VERSION ""

NS_ :

BS_:

BU_: FRM_FM_4X

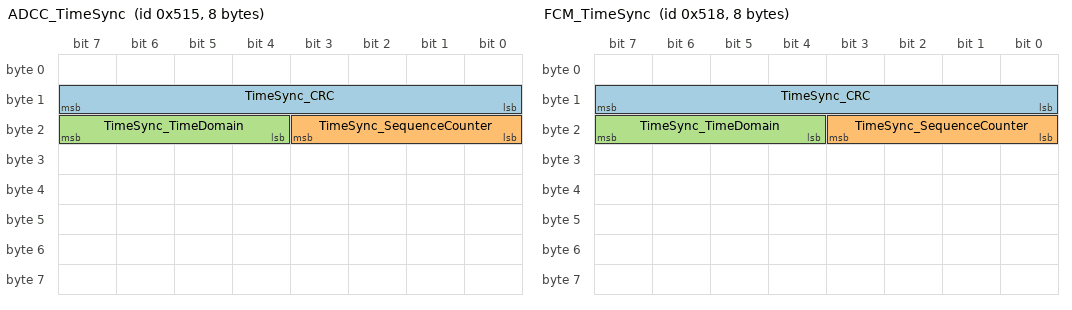
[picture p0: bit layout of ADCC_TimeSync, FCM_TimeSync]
BO_ 1301 ADCC_TimeSync: 8 Vector__XXX
 SG_ TimeSync_Type m: 7|8@0+ (1,0) [0|255] ""  FRM_FM_4X
 SG_ TimeSync_CRC : 15|8@0+ (1,0) [0|255] ""  FRM_FM_4X
 SG_ TimeSync_SequenceCounter : 19|4@0+ (1,0) [0|15] ""  FRM_FM_4X
 SG_ TimeSync_TimeDomain : 23|4@0+ (1,0) [0|15] ""  FRM_FM_4X
 SG_ TimeSync_UserByte0 m0x20: 31|8@0+ (1,0) [0|255] ""  FRM_FM_4X
 SG_ TimeSync_SyncTimeSec m0x20: 39|32@0+ (1,0) [0|4294967295] ""  FRM_FM_4X
 SG_ TimeSync_OverflowOfSeconds m0x28: 25|2@0+ (1,0) [0|3] ""  FRM_FM_4X
 SG_ TimeSync_SGW m0x28: 26|1@0+ (1,0) [0|1] ""  FRM_FM_4X
 SG_ TimeSync_Reserved0 m0x28: 31|5@0+ (1,0) [0|31] ""  FRM_FM_4X
 SG_ TimeSync_SyncTimeNSec m0x28: 39|32@0+ (1,0) [0|4294967295] ""  FRM_FM_4X

BO_ 1304 FCM_TimeSync: 8 Vector__XXX
 SG_ TimeSync_Type m: 7|8@0+ (1,0) [0|255] ""  FRM_FM_4X
 SG_ TimeSync_CRC : 15|8@0+ (1,0) [0|255] ""  FRM_FM_4X
 SG_ TimeSync_SequenceCounter : 19|4@0+ (1,0) [0|15] ""  FRM_FM_4X
 SG_ TimeSync_TimeDomain : 23|4@0+ (1,0) [0|15] ""  FRM_FM_4X
 SG_ TimeSync_UserByte0 m0x20: 31|8@0+ (1,0) [0|255] ""  FRM_FM_4X
 SG_ TimeSync_SyncTimeSec m0x20: 39|32@0+ (1,0) [0|4294967295] ""  FRM_FM_4X
 SG_ TimeSync_OverflowOfSeconds m0x28: 25|2@0+ (1,0) [0|3] ""  FRM_FM_4X
 SG_ TimeSync_SGW m0x28: 26|1@0+ (1,0) [0|1] ""  FRM_FM_4X
 SG_ TimeSync_Reserved0 m0x28: 31|5@0+ (1,0) [0|31] ""  FRM_FM_4X
 SG_ TimeSync_SyncTimeNSec m0x28: 39|32@0+ (1,0) [0|4294967295] ""  FRM_FM_4X

BO_ 960 FRM_1: 64 FRM_FM_4X
 SG_ FRM_1_CRC : 7|16@0+ (1,0) [0|65535] ""  Vector__XXX
 SG_ FRM_1_RollgCntr : 23|8@0+ (1,0) [0|255] ""  Vector__XXX
 SG_ FRM_1_ObjHd_ObjBlockCounter : 31|4@0+ (1,0) [0|15] ""  Vector__XXX
 SG_ FRM_1_ObjHd_MountPosX : 27|10@0+ (0.01,0) [0|10] "m"  Vector__XXX
 SG_ FRM_1_ObjHd_MountPosY : 33|9@0+ (0.01,-2.5) [-2.5|2.5] "m"  Vector__XXX
 SG_ FRM_1_ObjHd_MountPosZ : 40|9@0+ (0.01,0) [0|5] "m"  Vector__XXX
 SG_ FRM_1_ObjHd_MountAngleYaw : 63|9@0+ (0.1,-15) [-15|15] "deg"  Vector__XXX
 SG_ FRM_1_ObjHd_MountAnglePitch : 70|9@0+ (0.1,-15) [-15|15] "deg"  Vector__XXX
 SG_ FRM_1_ObjHd_MountAngleRoll : 77|9@0+ (0.1,-15) [-15|15] "deg"  Vector__XXX
 SG_ FRM_1_ObjHd_AlignAglYawErrCurr : 84|9@0+ (0.1,-15) [-15|15] "deg"  Vector__XXX
 SG_ FRM_1_ObjHd_AlignAglYawErrEOL : 91|9@0+ (0.1,-15) [-15|15] "deg"  Vector__XXX
 SG_ FRM_1_ObjHd_AlignAglPitchErrEOL : 98|9@0+ (0.1,-15) [-15|15] "deg"  Vector__XXX
 SG_ FRM_1_ObjHd_FOVYawAglLower : 105|11@0+ (0.1,-90) [-90|90] "deg"  Vector__XXX
 SG_ FRM_1_ObjHd_FOVYawAglUpper : 126|11@0+ (0.1,-90) [-90|90] "deg"  Vector__XXX
 SG_ FRM_1_ObjHd_FOVPitchAglLower : 131|10@0+ (0.1,-40) [-40|40] "deg"  Vector__XXX
 SG_ FRM_1_ObjHd_FOVPitchAglUpper : 137|10@0+ (0.1,-40) [-40|40] "deg"  Vector__XXX
 SG_ FRM_1_ObjHd_MaxDetectionRange : 159|8@0+ (1,0) [0|200] "m"  Vector__XXX
 SG_ FRM_1_ObjHd_HWFail : 160|1@0+ (1,0) [0|1] ""  Vector__XXX
 SG_ FRM_1_ObjHd_Misalignment : 161|1@0+ (1,0) [0|1] ""  Vector__XXX
 SG_ FRM_1_ObjHd_AlignmentNotDone : 162|1@0+ (1,0) [0|1] ""  Vector__XXX
 SG_ FRM_1_ObjHd_SensorBlockage : 163|1@0+ (1,0) [0|1] ""  Vector__XXX
 SG_ FRM_1_ObjHd_ObjDetFail : 164|1@0+ (1,0) [0|1] ""  Vector__XXX
 SG_ FRM_1_ObjHd_OutOfVoltage : 165|1@0+ (1,0) [0|1] ""  Vector__XXX
 SG_ FRM_1_ObjHd_OverTemperature : 166|1@0+ (1,0) [0|1] ""  Vector__XXX
 SG_ FRM_1_ObjHd_ReceivedCANTimeOut : 167|1@0+ (1,0) [0|1] ""  Vector__XXX
 SG_ FRM_1_ObjHd_ReceivedCANInvalid : 168|1@0+ (1,0) [0|1] ""  Vector__XXX
 SG_ FRM_1_ObjHd_RFBoardWorkingSts : 169|1@0+ (1,0) [0|1] ""  Vector__XXX
 SG_ FRM_1_ObjHd_ValidObjCount : 175|6@0+ (1,0) [0|50] ""  Vector__XXX
 SG_ FRM_1_ObjHd_ObjDownSel : 183|1@0+ (1,0) [0|1] ""  Vector__XXX
 SG_ FRM_1_ObjHd_ObjTimeStamp : 191|42@0+ (1,0) [0|4398046511103] "ms"  Vector__XXX
 SG_ FRM_1_ObjHd_ObjTimeStampSts : 229|5@0+ (1,0) [0|31] ""  Vector__XXX
 SG_ FRM_1_ObjHd_ObjTimeLatency : 224|9@0+ (1,0) [0|511] "ms"  Vector__XXX
 SG_ FRM_1_ObjHd_NotConfigured : 246|1@0+ (1,0) [0|1] ""  Vector__XXX
 SG_ FRM_1_ObjHd_ParameterInvalid : 247|1@0+ (1,0) [0|1] ""  Vector__XXX

BO_ 961 FRM_2: 64 FRM_FM_4X
 SG_ FRM_2_CRC : 7|16@0+ (1,0) [0|65535] ""  Vector__XXX
 SG_ FRM_2_RollgCntr : 23|8@0+ (1,0) [0|255] ""  Vector__XXX
 SG_ FRM_2_DetnHd_DetnBlockCounter : 31|4@0+ (1,0) [0|15] ""  Vector__XXX
 SG_ FRM_2_DetnHd_MountPosX : 27|10@0+ (0.01,0) [0|10] "m"  Vector__XXX
 SG_ FRM_2_DetnHd_MountPosY : 33|9@0+ (0.01,-2.5) [-2.5|2.5] "m"  Vector__XXX
 SG_ FRM_2_DetnHd_MountPosZ : 40|9@0+ (0.01,0) [0|5] "m"  Vector__XXX
 SG_ FRM_2_DetnHd_MountAngleYaw : 63|9@0+ (0.1,-15) [-15|15] "deg"  Vector__XXX
 SG_ FRM_2_DetnHd_MountAnglePitch : 70|9@0+ (0.1,-15) [-15|15] "deg"  Vector__XXX
 SG_ FRM_2_DetnHd_MountAngleRoll : 77|9@0+ (0.1,-15) [-15|15] "deg"  Vector__XXX
 SG_ FRM_2_DetnHd_AlignAglYawErrCurr : 84|9@0+ (0.1,-15) [-15|15] "deg"  Vector__XXX
 SG_ FRM_2_DetnHd_AlignAglYawErrEOL : 91|9@0+ (0.1,-15) [-15|15] "deg"  Vector__XXX
 SG_ FRM_2_DetnHd_AlignAglPitchErrEOL : 98|9@0+ (0.1,-15) [-15|15] "deg"  Vector__XXX
 SG_ FRM_2_DetnHd_FOVYawAglLower : 105|11@0+ (0.1,-90) [-90|90] "deg"  Vector__XXX
 SG_ FRM_2_DetnHd_FOVYawAglUpper : 126|11@0+ (0.1,-90) [-90|90] "deg"  Vector__XXX
 SG_ FRM_2_DetnHd_FOVPitchAglLower : 131|10@0+ (0.1,-40) [-40|40] "deg"  Vector__XXX
 SG_ FRM_2_DetnHd_FOVPitchAglUpper : 137|10@0+ (0.1,-40) [-40|40] "deg"  Vector__XXX
 SG_ FRM_2_DetnHd_MaxDetectionRange : 159|8@0+ (1,0) [0|200] "m"  Vector__XXX
 SG_ FRM_2_DetnHd_HWFail : 160|1@0+ (1,0) [0|1] ""  Vector__XXX
 SG_ FRM_2_DetnHd_Misalignment : 161|1@0+ (1,0) [0|1] ""  Vector__XXX
 SG_ FRM_2_DetnHd_AlignmentNotDone : 162|1@0+ (1,0) [0|1] ""  Vector__XXX
 SG_ FRM_2_DetnHd_SensorBlockage : 163|1@0+ (1,0) [0|1] ""  Vector__XXX
 SG_ FRM_2_DetnHd_ObjDetFail : 164|1@0+ (1,0) [0|1] ""  Vector__XXX
 SG_ FRM_2_DetnHd_OutOfVoltage : 165|1@0+ (1,0) [0|1] ""  Vector__XXX
 SG_ FRM_2_DetnHd_OverTemperature : 166|1@0+ (1,0) [0|1] ""  Vector__XXX
 SG_ FRM_2_DetnHd_ReceivedCANTimeOut : 167|1@0+ (1,0) [0|1] ""  Vector__XXX
 SG_ FRM_2_DetnHd_ReceivedCANInvalid : 168|1@0+ (1,0) [0|1] ""  Vector__XXX
 SG_ FRM_2_DetnHd_RFBoardWorkingSts : 169|1@0+ (1,0) [0|1] ""  Vector__XXX
 SG_ FRM_2_DetnHd_ValidDetnCount : 255|8@0+ (1,0) [0|200] ""  Vector__XXX
 SG_ FRM_2_DetnHd_DetnDownSel : 183|1@0+ (1,0) [0|1] ""  Vector__XXX
 SG_ FRM_2_DetnHd_DetnTimeStamp : 191|42@0+ (1,0) [0|4398046511103] "ms"  Vector__XXX
 SG_ FRM_2_DetnHd_DetnTimeStampSts : 229|5@0+ (1,0) [0|31] ""  Vector__XXX
 SG_ FRM_2_DetnHd_DetnTimeLatency : 224|9@0+ (1,0) [0|511] "ms"  Vector__XXX
 SG_ FRM_2_DetnHd_NotConfigured : 246|1@0+ (1,0) [0|1] ""  Vector__XXX
 SG_ FRM_2_DetnHd_ParameterInvalid : 247|1@0+ (1,0) [0|1] ""  Vector__XXX

BO_ 962 FRM_3: 64 FRM_FM_4X
 SG_ FRM_3_CRC : 7|16@0+ (1,0) [0|65535] ""  Vector__XXX
 SG_ FRM_3_RollgCntr : 23|8@0+ (1,0) [0|255] ""  Vector__XXX
 SG_ FRM_3_ObjBlockCounter : 31|4@0+ (1,0) [0|15] ""  Vector__XXX
 SG_ FRM_3_ObjID_00 : 39|8@0+ (1,0) [0|255] ""  Vector__XXX
 SG_ FRM_3_ObjClosestDistX_00 : 47|15@0+ (0.01,0) [0|200] "m"  Vector__XXX
 SG_ FRM_3_ObjClosestDistY_00 : 63|15@0+ (0.01,-100) [-100|100] "m"  Vector__XXX
 SG_ FRM_3_ObjRelVelX_00 : 79|15@0+ (0.01,-100) [-100|80] "m/s"  Vector__XXX
 SG_ FRM_3_ObjRelVelY_00 : 95|15@0+ (0.01,-100) [-100|80] "m/s"  Vector__XXX
 SG_ FRM_3_ObjAccelX_00 : 111|13@0+ (0.01,-25) [-25|25] "m/s^2"  Vector__XXX
 SG_ FRM_3_ObjAccelY_00 : 114|13@0+ (0.01,-25) [-25|25] "m/s^2"  Vector__XXX
 SG_ FRM_3_ObjClosestDistXStd_00 : 133|6@0+ (0.1,0) [0|5] ""  Vector__XXX
 SG_ FRM_3_ObjClosestDistYStd_00 : 143|6@0+ (0.1,0) [0|5] ""  Vector__XXX
 SG_ FRM_3_ObjRelVelXStd_00 : 137|7@0+ (0.05,0) [0|4] ""  Vector__XXX
 SG_ FRM_3_ObjRelVelYStd_00 : 146|7@0+ (0.05,0) [0|4] ""  Vector__XXX
 SG_ FRM_3_ObjRelAccelXStd_00 : 155|6@0+ (0.05,0) [0|3] ""  Vector__XXX
 SG_ FRM_3_ObjRelAccelYStd_00 : 165|6@0+ (0.05,0) [0|3] ""  Vector__XXX
 SG_ FRM_3_ObjExistProb_00 : 175|7@0+ (1,0) [0|100] "%"  Vector__XXX
 SG_ FRM_3_ObjType_00 : 168|2@0+ (1,0) [0|3] ""  Vector__XXX
 SG_ FRM_3_ObjTypeConf_00 : 182|7@0+ (1,0) [0|100] "%"  Vector__XXX
 SG_ FRM_3_ObjTrackSts_00 : 191|2@0+ (1,0) [0|3] ""  Vector__XXX
 SG_ FRM_3_ObjMotionSts_00 : 189|2@0+ (1,0) [0|3] ""  Vector__XXX
 SG_ FRM_3_ObjMotionDirection_00 : 187|2@0+ (1,0) [0|3] ""  Vector__XXX
 SG_ FRM_3_ObjCenterDistX_00 : 199|15@0+ (0.01,0) [0|200] "m"  Vector__XXX
 SG_ FRM_3_ObjCenterDistY_00 : 215|15@0+ (0.01,-100) [-100|100] "m"  Vector__XXX
 SG_ FRM_3_ObjLength_00 : 216|9@0+ (0.1,0) [0|50] "m"  Vector__XXX
 SG_ FRM_3_ObjWidth_00 : 239|9@0+ (0.1,0) [0|30] "m"  Vector__XXX
 SG_ FRM_3_ObjElevnSts_00 : 246|2@0+ (1,0) [0|3] ""  Vector__XXX
 SG_ FRM_3_ObjElevnStsConf_00 : 244|7@0+ (1,0) [0|100] "%"  Vector__XXX
 SG_ FRM_3_ObjHeading_00 : 253|12@0+ (0.1,-180) [-180|180] "deg"  Vector__XXX
 SG_ FRM_3_ObjID_01 : 271|8@0+ (1,0) [0|255] ""  Vector__XXX
 SG_ FRM_3_ObjClosestDistX_01 : 279|15@0+ (0.01,0) [0|200] "m"  Vector__XXX
 SG_ FRM_3_ObjClosestDistY_01 : 295|15@0+ (0.01,-100) [-100|100] "m"  Vector__XXX
 SG_ FRM_3_ObjRelVelX_01 : 311|15@0+ (0.01,-100) [-100|80] "m/s"  Vector__XXX
 SG_ FRM_3_ObjRelVelY_01 : 327|15@0+ (0.01,-100) [-100|80] "m/s"  Vector__XXX
 SG_ FRM_3_ObjAccelX_01 : 343|13@0+ (0.01,-25) [-25|25] "m/s^2"  Vector__XXX
 SG_ FRM_3_ObjAccelY_01 : 346|13@0+ (0.01,-25) [-25|25] "m/s^2"  Vector__XXX
 SG_ FRM_3_ObjClosestDistXStd_01 : 365|6@0+ (0.1,0) [0|5] ""  Vector__XXX
 SG_ FRM_3_ObjClosestDistYStd_01 : 375|6@0+ (0.1,0) [0|5] ""  Vector__XXX
 SG_ FRM_3_ObjRelVelXStd_01 : 369|7@0+ (0.05,0) [0|4] ""  Vector__XXX
 SG_ FRM_3_ObjRelVelYStd_01 : 378|7@0+ (0.05,0) [0|4] ""  Vector__XXX
 SG_ FRM_3_ObjRelAccelXStd_01 : 387|6@0+ (0.05,0) [0|3] ""  Vector__XXX
 SG_ FRM_3_ObjRelAccelYStd_01 : 397|6@0+ (0.05,0) [0|3] ""  Vector__XXX
 SG_ FRM_3_ObjExistProb_01 : 407|7@0+ (1,0) [0|100] "%"  Vector__XXX
 SG_ FRM_3_ObjType_01 : 400|2@0+ (1,0) [0|3] ""  Vector__XXX
 SG_ FRM_3_ObjTypeConf_01 : 414|7@0+ (1,0) [0|100] "%"  Vector__XXX
 SG_ FRM_3_ObjTrackSts_01 : 423|2@0+ (1,0) [0|3] ""  Vector__XXX
 SG_ FRM_3_ObjMotionSts_01 : 421|2@0+ (1,0) [0|3] ""  Vector__XXX
 SG_ FRM_3_ObjMotionDirection_01 : 419|2@0+ (1,0) [0|3] ""  Vector__XXX
 SG_ FRM_3_ObjCenterDistX_01 : 431|15@0+ (0.01,0) [0|200] "m"  Vector__XXX
 SG_ FRM_3_ObjCenterDistY_01 : 447|15@0+ (0.01,-100) [-100|100] "m"  Vector__XXX
 SG_ FRM_3_ObjLength_01 : 448|9@0+ (0.1,0) [0|50] "m"  Vector__XXX
 SG_ FRM_3_ObjWidth_01 : 471|9@0+ (0.1,0) [0|30] "m"  Vector__XXX
 SG_ FRM_3_ObjElevnSts_01 : 478|2@0+ (1,0) [0|3] ""  Vector__XXX
 SG_ FRM_3_ObjElevnStsConf_01 : 476|7@0+ (1,0) [0|100] "%"  Vector__XXX
 SG_ FRM_3_ObjHeading_01 : 485|12@0+ (0.1,-180) [-180|180] "deg"  Vector__XXX

BO_ 963 FRM_4: 64 FRM_FM_4X
 SG_ FRM_4_CRC : 7|16@0+ (1,0) [0|65535] ""  Vector__XXX
 SG_ FRM_4_RollgCntr : 23|8@0+ (1,0) [0|255] ""  Vector__XXX
 SG_ FRM_4_ObjBlockCounter : 31|4@0+ (1,0) [0|15] ""  Vector__XXX
 SG_ FRM_4_ObjID_02 : 39|8@0+ (1,0) [0|255] ""  Vector__XXX
 SG_ FRM_4_ObjClosestDistX_02 : 47|15@0+ (0.01,0) [0|200] "m"  Vector__XXX
 SG_ FRM_4_ObjClosestDistY_02 : 63|15@0+ (0.01,-100) [-100|100] "m"  Vector__XXX
 SG_ FRM_4_ObjRelVelX_02 : 79|15@0+ (0.01,-100) [-100|80] "m/s"  Vector__XXX
 SG_ FRM_4_ObjRelVelY_02 : 95|15@0+ (0.01,-100) [-100|80] "m/s"  Vector__XXX
 SG_ FRM_4_ObjAccelX_02 : 111|13@0+ (0.01,-25) [-25|25] "m/s^2"  Vector__XXX
 SG_ FRM_4_ObjAccelY_02 : 114|13@0+ (0.01,-25) [-25|25] "m/s^2"  Vector__XXX
 SG_ FRM_4_ObjClosestDistXStd_02 : 133|6@0+ (0.1,0) [0|5] ""  Vector__XXX
 SG_ FRM_4_ObjClosestDistYStd_02 : 143|6@0+ (0.1,0) [0|5] ""  Vector__XXX
 SG_ FRM_4_ObjRelVelXStd_02 : 137|7@0+ (0.05,0) [0|4] ""  Vector__XXX
 SG_ FRM_4_ObjRelVelYStd_02 : 146|7@0+ (0.05,0) [0|4] ""  Vector__XXX
 SG_ FRM_4_ObjRelAccelXStd_02 : 155|6@0+ (0.05,0) [0|3] ""  Vector__XXX
 SG_ FRM_4_ObjRelAccelYStd_02 : 165|6@0+ (0.05,0) [0|3] ""  Vector__XXX
 SG_ FRM_4_ObjExistProb_02 : 175|7@0+ (1,0) [0|100] "%"  Vector__XXX
 SG_ FRM_4_ObjType_02 : 168|2@0+ (1,0) [0|3] ""  Vector__XXX
 SG_ FRM_4_ObjTypeConf_02 : 182|7@0+ (1,0) [0|100] "%"  Vector__XXX
 SG_ FRM_4_ObjTrackSts_02 : 191|2@0+ (1,0) [0|3] ""  Vector__XXX
 SG_ FRM_4_ObjMotionSts_02 : 189|2@0+ (1,0) [0|3] ""  Vector__XXX
 SG_ FRM_4_ObjMotionDirection_02 : 187|2@0+ (1,0) [0|3] ""  Vector__XXX
 SG_ FRM_4_ObjCenterDistX_02 : 199|15@0+ (0.01,0) [0|200] "m"  Vector__XXX
 SG_ FRM_4_ObjCenterDistY_02 : 215|15@0+ (0.01,-100) [-100|100] "m"  Vector__XXX
 SG_ FRM_4_ObjLength_02 : 216|9@0+ (0.1,0) [0|50] "m"  Vector__XXX
 SG_ FRM_4_ObjWidth_02 : 239|9@0+ (0.1,0) [0|30] "m"  Vector__XXX
 SG_ FRM_4_ObjElevnSts_02 : 246|2@0+ (1,0) [0|3] ""  Vector__XXX
 SG_ FRM_4_ObjElevnStsConf_02 : 244|7@0+ (1,0) [0|100] "%"  Vector__XXX
 SG_ FRM_4_ObjHeading_02 : 253|12@0+ (0.1,-180) [-180|180] "deg"  Vector__XXX
 SG_ FRM_4_ObjID_03 : 271|8@0+ (1,0) [0|255] ""  Vector__XXX
 SG_ FRM_4_ObjClosestDistX_03 : 279|15@0+ (0.01,0) [0|200] "m"  Vector__XXX
 SG_ FRM_4_ObjClosestDistY_03 : 295|15@0+ (0.01,-100) [-100|100] "m"  Vector__XXX
 SG_ FRM_4_ObjRelVelX_03 : 311|15@0+ (0.01,-100) [-100|80] "m/s"  Vector__XXX
 SG_ FRM_4_ObjRelVelY_03 : 327|15@0+ (0.01,-100) [-100|80] "m/s"  Vector__XXX
 SG_ FRM_4_ObjAccelX_03 : 343|13@0+ (0.01,-25) [-25|25] "m/s^2"  Vector__XXX
 SG_ FRM_4_ObjAccelY_03 : 346|13@0+ (0.01,-25) [-25|25] "m/s^2"  Vector__XXX
 SG_ FRM_4_ObjClosestDistXStd_03 : 365|6@0+ (0.1,0) [0|5] ""  Vector__XXX
 SG_ FRM_4_ObjClosestDistYStd_03 : 375|6@0+ (0.1,0) [0|5] ""  Vector__XXX
 SG_ FRM_4_ObjRelVelXStd_03 : 369|7@0+ (0.05,0) [0|4] ""  Vector__XXX
 SG_ FRM_4_ObjRelVelYStd_03 : 378|7@0+ (0.05,0) [0|4] ""  Vector__XXX
 SG_ FRM_4_ObjRelAccelXStd_03 : 387|6@0+ (0.05,0) [0|3] ""  Vector__XXX
 SG_ FRM_4_ObjRelAccelYStd_03 : 397|6@0+ (0.05,0) [0|3] ""  Vector__XXX
 SG_ FRM_4_ObjExistProb_03 : 407|7@0+ (1,0) [0|100] "%"  Vector__XXX
 SG_ FRM_4_ObjType_03 : 400|2@0+ (1,0) [0|3] ""  Vector__XXX
 SG_ FRM_4_ObjTypeConf_03 : 414|7@0+ (1,0) [0|100] "%"  Vector__XXX
 SG_ FRM_4_ObjTrackSts_03 : 423|2@0+ (1,0) [0|3] ""  Vector__XXX
 SG_ FRM_4_ObjMotionSts_03 : 421|2@0+ (1,0) [0|3] ""  Vector__XXX
 SG_ FRM_4_ObjMotionDirection_03 : 419|2@0+ (1,0) [0|3] ""  Vector__XXX
 SG_ FRM_4_ObjCenterDistX_03 : 431|15@0+ (0.01,0) [0|200] "m"  Vector__XXX
 SG_ FRM_4_ObjCenterDistY_03 : 447|15@0+ (0.01,-100) [-100|100] "m"  Vector__XXX
 SG_ FRM_4_ObjLength_03 : 448|9@0+ (0.1,0) [0|50] "m"  Vector__XXX
 SG_ FRM_4_ObjWidth_03 : 471|9@0+ (0.1,0) [0|30] "m"  Vector__XXX
 SG_ FRM_4_ObjElevnSts_03 : 478|2@0+ (1,0) [0|3] ""  Vector__XXX
 SG_ FRM_4_ObjElevnStsConf_03 : 476|7@0+ (1,0) [0|100] "%"  Vector__XXX
 SG_ FRM_4_ObjHeading_03 : 485|12@0+ (0.1,-180) [-180|180] "deg"  Vector__XXX

BO_ 964 FRM_5: 64 FRM_FM_4X
 SG_ FRM_5_CRC : 7|16@0+ (1,0) [0|65535] ""  Vector__XXX
 SG_ FRM_5_RollgCntr : 23|8@0+ (1,0) [0|255] ""  Vector__XXX
 SG_ FRM_5_ObjBlockCounter : 31|4@0+ (1,0) [0|15] ""  Vector__XXX
 SG_ FRM_5_ObjID_04 : 39|8@0+ (1,0) [0|255] ""  Vector__XXX
 SG_ FRM_5_ObjClosestDistX_04 : 47|15@0+ (0.01,0) [0|200] "m"  Vector__XXX
 SG_ FRM_5_ObjClosestDistY_04 : 63|15@0+ (0.01,-100) [-100|100] "m"  Vector__XXX
 SG_ FRM_5_ObjRelVelX_04 : 79|15@0+ (0.01,-100) [-100|80] "m/s"  Vector__XXX
 SG_ FRM_5_ObjRelVelY_04 : 95|15@0+ (0.01,-100) [-100|80] "m/s"  Vector__XXX
 SG_ FRM_5_ObjAccelX_04 : 111|13@0+ (0.01,-25) [-25|25] "m/s^2"  Vector__XXX
 SG_ FRM_5_ObjAccelY_04 : 114|13@0+ (0.01,-25) [-25|25] "m/s^2"  Vector__XXX
 SG_ FRM_5_ObjClosestDistXStd_04 : 133|6@0+ (0.1,0) [0|5] ""  Vector__XXX
 SG_ FRM_5_ObjClosestDistYStd_04 : 143|6@0+ (0.1,0) [0|5] ""  Vector__XXX
 SG_ FRM_5_ObjRelVelXStd_04 : 137|7@0+ (0.05,0) [0|4] ""  Vector__XXX
 SG_ FRM_5_ObjRelVelYStd_04 : 146|7@0+ (0.05,0) [0|4] ""  Vector__XXX
 SG_ FRM_5_ObjRelAccelXStd_04 : 155|6@0+ (0.05,0) [0|3] ""  Vector__XXX
 SG_ FRM_5_ObjRelAccelYStd_04 : 165|6@0+ (0.05,0) [0|3] ""  Vector__XXX
 SG_ FRM_5_ObjExistProb_04 : 175|7@0+ (1,0) [0|100] "%"  Vector__XXX
 SG_ FRM_5_ObjType_04 : 168|2@0+ (1,0) [0|3] ""  Vector__XXX
 SG_ FRM_5_ObjTypeConf_04 : 182|7@0+ (1,0) [0|100] "%"  Vector__XXX
 SG_ FRM_5_ObjTrackSts_04 : 191|2@0+ (1,0) [0|3] ""  Vector__XXX
 SG_ FRM_5_ObjMotionSts_04 : 189|2@0+ (1,0) [0|3] ""  Vector__XXX
 SG_ FRM_5_ObjMotionDirection_04 : 187|2@0+ (1,0) [0|3] ""  Vector__XXX
 SG_ FRM_5_ObjCenterDistX_04 : 199|15@0+ (0.01,0) [0|200] "m"  Vector__XXX
 SG_ FRM_5_ObjCenterDistY_04 : 215|15@0+ (0.01,-100) [-100|100] "m"  Vector__XXX
 SG_ FRM_5_ObjLength_04 : 216|9@0+ (0.1,0) [0|50] "m"  Vector__XXX
 SG_ FRM_5_ObjWidth_04 : 239|9@0+ (0.1,0) [0|30] "m"  Vector__XXX
 SG_ FRM_5_ObjElevnSts_04 : 246|2@0+ (1,0) [0|3] ""  Vector__XXX
 SG_ FRM_5_ObjElevnStsConf_04 : 244|7@0+ (1,0) [0|100] "%"  Vector__XXX
 SG_ FRM_5_ObjHeading_04 : 253|12@0+ (0.1,-180) [-180|180] "deg"  Vector__XXX
 SG_ FRM_5_ObjID_05 : 271|8@0+ (1,0) [0|255] ""  Vector__XXX
 SG_ FRM_5_ObjClosestDistX_05 : 279|15@0+ (0.01,0) [0|200] "m"  Vector__XXX
 SG_ FRM_5_ObjClosestDistY_05 : 295|15@0+ (0.01,-100) [-100|100] "m"  Vector__XXX
 SG_ FRM_5_ObjRelVelX_05 : 311|15@0+ (0.01,-100) [-100|80] "m/s"  Vector__XXX
 SG_ FRM_5_ObjRelVelY_05 : 327|15@0+ (0.01,-100) [-100|80] "m/s"  Vector__XXX
 SG_ FRM_5_ObjAccelX_05 : 343|13@0+ (0.01,-25) [-25|25] "m/s^2"  Vector__XXX
 SG_ FRM_5_ObjAccelY_05 : 346|13@0+ (0.01,-25) [-25|25] "m/s^2"  Vector__XXX
 SG_ FRM_5_ObjClosestDistXStd_05 : 365|6@0+ (0.1,0) [0|5] ""  Vector__XXX
 SG_ FRM_5_ObjClosestDistYStd_05 : 375|6@0+ (0.1,0) [0|5] ""  Vector__XXX
 SG_ FRM_5_ObjRelVelXStd_05 : 369|7@0+ (0.05,0) [0|4] ""  Vector__XXX
 SG_ FRM_5_ObjRelVelYStd_05 : 378|7@0+ (0.05,0) [0|4] ""  Vector__XXX
 SG_ FRM_5_ObjRelAccelXStd_05 : 387|6@0+ (0.05,0) [0|3] ""  Vector__XXX
 SG_ FRM_5_ObjRelAccelYStd_05 : 397|6@0+ (0.05,0) [0|3] ""  Vector__XXX
 SG_ FRM_5_ObjExistProb_05 : 407|7@0+ (1,0) [0|100] "%"  Vector__XXX
 SG_ FRM_5_ObjType_05 : 400|2@0+ (1,0) [0|3] ""  Vector__XXX
 SG_ FRM_5_ObjTypeConf_05 : 414|7@0+ (1,0) [0|100] "%"  Vector__XXX
 SG_ FRM_5_ObjTrackSts_05 : 423|2@0+ (1,0) [0|3] ""  Vector__XXX
 SG_ FRM_5_ObjMotionSts_05 : 421|2@0+ (1,0) [0|3] ""  Vector__XXX
 SG_ FRM_5_ObjMotionDirection_05 : 419|2@0+ (1,0) [0|3] ""  Vector__XXX
 SG_ FRM_5_ObjCenterDistX_05 : 431|15@0+ (0.01,0) [0|200] "m"  Vector__XXX
 SG_ FRM_5_ObjCenterDistY_05 : 447|15@0+ (0.01,-100) [-100|100] "m"  Vector__XXX
 SG_ FRM_5_ObjLength_05 : 448|9@0+ (0.1,0) [0|50] "m"  Vector__XXX
 SG_ FRM_5_ObjWidth_05 : 471|9@0+ (0.1,0) [0|30] "m"  Vector__XXX
 SG_ FRM_5_ObjElevnSts_05 : 478|2@0+ (1,0) [0|3] ""  Vector__XXX
 SG_ FRM_5_ObjElevnStsConf_05 : 476|7@0+ (1,0) [0|100] "%"  Vector__XXX
 SG_ FRM_5_ObjHeading_05 : 485|12@0+ (0.1,-180) [-180|180] "deg"  Vector__XXX

BO_ 965 FRM_6: 64 FRM_FM_4X
 SG_ FRM_6_CRC : 7|16@0+ (1,0) [0|65535] ""  Vector__XXX
 SG_ FRM_6_RollgCntr : 23|8@0+ (1,0) [0|255] ""  Vector__XXX
 SG_ FRM_6_ObjBlockCounter : 31|4@0+ (1,0) [0|15] ""  Vector__XXX
 SG_ FRM_6_ObjID_06 : 39|8@0+ (1,0) [0|255] ""  Vector__XXX
 SG_ FRM_6_ObjClosestDistX_06 : 47|15@0+ (0.01,0) [0|200] "m"  Vector__XXX
 SG_ FRM_6_ObjClosestDistY_06 : 63|15@0+ (0.01,-100) [-100|100] "m"  Vector__XXX
 SG_ FRM_6_ObjRelVelX_06 : 79|15@0+ (0.01,-100) [-100|80] "m/s"  Vector__XXX
 SG_ FRM_6_ObjRelVelY_06 : 95|15@0+ (0.01,-100) [-100|80] "m/s"  Vector__XXX
 SG_ FRM_6_ObjAccelX_06 : 111|13@0+ (0.01,-25) [-25|25] "m/s^2"  Vector__XXX
 SG_ FRM_6_ObjAccelY_06 : 114|13@0+ (0.01,-25) [-25|25] "m/s^2"  Vector__XXX
 SG_ FRM_6_ObjClosestDistXStd_06 : 133|6@0+ (0.1,0) [0|5] ""  Vector__XXX
 SG_ FRM_6_ObjClosestDistYStd_06 : 143|6@0+ (0.1,0) [0|5] ""  Vector__XXX
 SG_ FRM_6_ObjRelVelXStd_06 : 137|7@0+ (0.05,0) [0|4] ""  Vector__XXX
 SG_ FRM_6_ObjRelVelYStd_06 : 146|7@0+ (0.05,0) [0|4] ""  Vector__XXX
 SG_ FRM_6_ObjRelAccelXStd_06 : 155|6@0+ (0.05,0) [0|3] ""  Vector__XXX
 SG_ FRM_6_ObjRelAccelYStd_06 : 165|6@0+ (0.05,0) [0|3] ""  Vector__XXX
 SG_ FRM_6_ObjExistProb_06 : 175|7@0+ (1,0) [0|100] "%"  Vector__XXX
 SG_ FRM_6_ObjType_06 : 168|2@0+ (1,0) [0|3] ""  Vector__XXX
 SG_ FRM_6_ObjTypeConf_06 : 182|7@0+ (1,0) [0|100] "%"  Vector__XXX
 SG_ FRM_6_ObjTrackSts_06 : 191|2@0+ (1,0) [0|3] ""  Vector__XXX
 SG_ FRM_6_ObjMotionSts_06 : 189|2@0+ (1,0) [0|3] ""  Vector__XXX
 SG_ FRM_6_ObjMotionDirection_06 : 187|2@0+ (1,0) [0|3] ""  Vector__XXX
 SG_ FRM_6_ObjCenterDistX_06 : 199|15@0+ (0.01,0) [0|200] "m"  Vector__XXX
 SG_ FRM_6_ObjCenterDistY_06 : 215|15@0+ (0.01,-100) [-100|100] "m"  Vector__XXX
 SG_ FRM_6_ObjLength_06 : 216|9@0+ (0.1,0) [0|50] "m"  Vector__XXX
 SG_ FRM_6_ObjWidth_06 : 239|9@0+ (0.1,0) [0|30] "m"  Vector__XXX
 SG_ FRM_6_ObjElevnSts_06 : 246|2@0+ (1,0) [0|3] ""  Vector__XXX
 SG_ FRM_6_ObjElevnStsConf_06 : 244|7@0+ (1,0) [0|100] "%"  Vector__XXX
 SG_ FRM_6_ObjHeading_06 : 253|12@0+ (0.1,-180) [-180|180] "deg"  Vector__XXX
 SG_ FRM_6_ObjID_07 : 271|8@0+ (1,0) [0|255] ""  Vector__XXX
 SG_ FRM_6_ObjClosestDistX_07 : 279|15@0+ (0.01,0) [0|200] "m"  Vector__XXX
 SG_ FRM_6_ObjClosestDistY_07 : 295|15@0+ (0.01,-100) [-100|100] "m"  Vector__XXX
 SG_ FRM_6_ObjRelVelX_07 : 311|15@0+ (0.01,-100) [-100|80] "m/s"  Vector__XXX
 SG_ FRM_6_ObjRelVelY_07 : 327|15@0+ (0.01,-100) [-100|80] "m/s"  Vector__XXX
 SG_ FRM_6_ObjAccelX_07 : 343|13@0+ (0.01,-25) [-25|25] "m/s^2"  Vector__XXX
 SG_ FRM_6_ObjAccelY_07 : 346|13@0+ (0.01,-25) [-25|25] "m/s^2"  Vector__XXX
 SG_ FRM_6_ObjClosestDistXStd_07 : 365|6@0+ (0.1,0) [0|5] ""  Vector__XXX
 SG_ FRM_6_ObjClosestDistYStd_07 : 375|6@0+ (0.1,0) [0|5] ""  Vector__XXX
 SG_ FRM_6_ObjRelVelXStd_07 : 369|7@0+ (0.05,0) [0|4] ""  Vector__XXX
 SG_ FRM_6_ObjRelVelYStd_07 : 378|7@0+ (0.05,0) [0|4] ""  Vector__XXX
 SG_ FRM_6_ObjRelAccelXStd_07 : 387|6@0+ (0.05,0) [0|3] ""  Vector__XXX
 SG_ FRM_6_ObjRelAccelYStd_07 : 397|6@0+ (0.05,0) [0|3] ""  Vector__XXX
 SG_ FRM_6_ObjExistProb_07 : 407|7@0+ (1,0) [0|100] "%"  Vector__XXX
 SG_ FRM_6_ObjType_07 : 400|2@0+ (1,0) [0|3] ""  Vector__XXX
 SG_ FRM_6_ObjTypeConf_07 : 414|7@0+ (1,0) [0|100] "%"  Vector__XXX
 SG_ FRM_6_ObjTrackSts_07 : 423|2@0+ (1,0) [0|3] ""  Vector__XXX
 SG_ FRM_6_ObjMotionSts_07 : 421|2@0+ (1,0) [0|3] ""  Vector__XXX
 SG_ FRM_6_ObjMotionDirection_07 : 419|2@0+ (1,0) [0|3] ""  Vector__XXX
 SG_ FRM_6_ObjCenterDistX_07 : 431|15@0+ (0.01,0) [0|200] "m"  Vector__XXX
 SG_ FRM_6_ObjCenterDistY_07 : 447|15@0+ (0.01,-100) [-100|100] "m"  Vector__XXX
 SG_ FRM_6_ObjLength_07 : 448|9@0+ (0.1,0) [0|50] "m"  Vector__XXX
 SG_ FRM_6_ObjWidth_07 : 471|9@0+ (0.1,0) [0|30] "m"  Vector__XXX
 SG_ FRM_6_ObjElevnSts_07 : 478|2@0+ (1,0) [0|3] ""  Vector__XXX
 SG_ FRM_6_ObjElevnStsConf_07 : 476|7@0+ (1,0) [0|100] "%"  Vector__XXX
 SG_ FRM_6_ObjHeading_07 : 485|12@0+ (0.1,-180) [-180|180] "deg"  Vector__XXX

BO_ 966 FRM_7: 64 FRM_FM_4X
 SG_ FRM_7_CRC : 7|16@0+ (1,0) [0|65535] ""  Vector__XXX
 SG_ FRM_7_RollgCntr : 23|8@0+ (1,0) [0|255] ""  Vector__XXX
 SG_ FRM_7_ObjBlockCounter : 31|4@0+ (1,0) [0|15] ""  Vector__XXX
 SG_ FRM_7_ObjID_08 : 39|8@0+ (1,0) [0|255] ""  Vector__XXX
 SG_ FRM_7_ObjClosestDistX_08 : 47|15@0+ (0.01,0) [0|200] "m"  Vector__XXX
 SG_ FRM_7_ObjClosestDistY_08 : 63|15@0+ (0.01,-100) [-100|100] "m"  Vector__XXX
 SG_ FRM_7_ObjRelVelX_08 : 79|15@0+ (0.01,-100) [-100|80] "m/s"  Vector__XXX
 SG_ FRM_7_ObjRelVelY_08 : 95|15@0+ (0.01,-100) [-100|80] "m/s"  Vector__XXX
 SG_ FRM_7_ObjAccelX_08 : 111|13@0+ (0.01,-25) [-25|25] "m/s^2"  Vector__XXX
 SG_ FRM_7_ObjAccelY_08 : 114|13@0+ (0.01,-25) [-25|25] "m/s^2"  Vector__XXX
 SG_ FRM_7_ObjClosestDistXStd_08 : 133|6@0+ (0.1,0) [0|5] ""  Vector__XXX
 SG_ FRM_7_ObjClosestDistYStd_08 : 143|6@0+ (0.1,0) [0|5] ""  Vector__XXX
 SG_ FRM_7_ObjRelVelXStd_08 : 137|7@0+ (0.05,0) [0|4] ""  Vector__XXX
 SG_ FRM_7_ObjRelVelYStd_08 : 146|7@0+ (0.05,0) [0|4] ""  Vector__XXX
 SG_ FRM_7_ObjRelAccelXStd_08 : 155|6@0+ (0.05,0) [0|3] ""  Vector__XXX
 SG_ FRM_7_ObjRelAccelYStd_08 : 165|6@0+ (0.05,0) [0|3] ""  Vector__XXX
 SG_ FRM_7_ObjExistProb_08 : 175|7@0+ (1,0) [0|100] "%"  Vector__XXX
 SG_ FRM_7_ObjType_08 : 168|2@0+ (1,0) [0|3] ""  Vector__XXX
 SG_ FRM_7_ObjTypeConf_08 : 182|7@0+ (1,0) [0|100] "%"  Vector__XXX
 SG_ FRM_7_ObjTrackSts_08 : 191|2@0+ (1,0) [0|3] ""  Vector__XXX
 SG_ FRM_7_ObjMotionSts_08 : 189|2@0+ (1,0) [0|3] ""  Vector__XXX
 SG_ FRM_7_ObjMotionDirection_08 : 187|2@0+ (1,0) [0|3] ""  Vector__XXX
 SG_ FRM_7_ObjCenterDistX_08 : 199|15@0+ (0.01,0) [0|200] "m"  Vector__XXX
 SG_ FRM_7_ObjCenterDistY_08 : 215|15@0+ (0.01,-100) [-100|100] "m"  Vector__XXX
 SG_ FRM_7_ObjLength_08 : 216|9@0+ (0.1,0) [0|50] "m"  Vector__XXX
 SG_ FRM_7_ObjWidth_08 : 239|9@0+ (0.1,0) [0|30] "m"  Vector__XXX
 SG_ FRM_7_ObjElevnSts_08 : 246|2@0+ (1,0) [0|3] ""  Vector__XXX
 SG_ FRM_7_ObjElevnStsConf_08 : 244|7@0+ (1,0) [0|100] "%"  Vector__XXX
 SG_ FRM_7_ObjHeading_08 : 253|12@0+ (0.1,-180) [-180|180] "deg"  Vector__XXX
 SG_ FRM_7_ObjID_09 : 271|8@0+ (1,0) [0|255] ""  Vector__XXX
 SG_ FRM_7_ObjClosestDistX_09 : 279|15@0+ (0.01,0) [0|200] "m"  Vector__XXX
 SG_ FRM_7_ObjClosestDistY_09 : 295|15@0+ (0.01,-100) [-100|100] "m"  Vector__XXX
 SG_ FRM_7_ObjRelVelX_09 : 311|15@0+ (0.01,-100) [-100|80] "m/s"  Vector__XXX
 SG_ FRM_7_ObjRelVelY_09 : 327|15@0+ (0.01,-100) [-100|80] "m/s"  Vector__XXX
 SG_ FRM_7_ObjAccelX_09 : 343|13@0+ (0.01,-25) [-25|25] "m/s^2"  Vector__XXX
 SG_ FRM_7_ObjAccelY_09 : 346|13@0+ (0.01,-25) [-25|25] "m/s^2"  Vector__XXX
 SG_ FRM_7_ObjClosestDistXStd_09 : 365|6@0+ (0.1,0) [0|5] ""  Vector__XXX
 SG_ FRM_7_ObjClosestDistYStd_09 : 375|6@0+ (0.1,0) [0|5] ""  Vector__XXX
 SG_ FRM_7_ObjRelVelXStd_09 : 369|7@0+ (0.05,0) [0|4] ""  Vector__XXX
 SG_ FRM_7_ObjRelVelYStd_09 : 378|7@0+ (0.05,0) [0|4] ""  Vector__XXX
 SG_ FRM_7_ObjRelAccelXStd_09 : 387|6@0+ (0.05,0) [0|3] ""  Vector__XXX
 SG_ FRM_7_ObjRelAccelYStd_09 : 397|6@0+ (0.05,0) [0|3] ""  Vector__XXX
 SG_ FRM_7_ObjExistProb_09 : 407|7@0+ (1,0) [0|100] "%"  Vector__XXX
 SG_ FRM_7_ObjType_09 : 400|2@0+ (1,0) [0|3] ""  Vector__XXX
 SG_ FRM_7_ObjTypeConf_09 : 414|7@0+ (1,0) [0|100] "%"  Vector__XXX
 SG_ FRM_7_ObjTrackSts_09 : 423|2@0+ (1,0) [0|3] ""  Vector__XXX
 SG_ FRM_7_ObjMotionSts_09 : 421|2@0+ (1,0) [0|3] ""  Vector__XXX
 SG_ FRM_7_ObjMotionDirection_09 : 419|2@0+ (1,0) [0|3] ""  Vector__XXX
 SG_ FRM_7_ObjCenterDistX_09 : 431|15@0+ (0.01,0) [0|200] "m"  Vector__XXX
 SG_ FRM_7_ObjCenterDistY_09 : 447|15@0+ (0.01,-100) [-100|100] "m"  Vector__XXX
 SG_ FRM_7_ObjLength_09 : 448|9@0+ (0.1,0) [0|50] "m"  Vector__XXX
 SG_ FRM_7_ObjWidth_09 : 471|9@0+ (0.1,0) [0|30] "m"  Vector__XXX
 SG_ FRM_7_ObjElevnSts_09 : 478|2@0+ (1,0) [0|3] ""  Vector__XXX
 SG_ FRM_7_ObjElevnStsConf_09 : 476|7@0+ (1,0) [0|100] "%"  Vector__XXX
 SG_ FRM_7_ObjHeading_09 : 485|12@0+ (0.1,-180) [-180|180] "deg"  Vector__XXX

BO_ 967 FRM_8: 64 FRM_FM_4X
 SG_ FRM_8_CRC : 7|16@0+ (1,0) [0|65535] ""  Vector__XXX
 SG_ FRM_8_RollgCntr : 23|8@0+ (1,0) [0|255] ""  Vector__XXX
 SG_ FRM_8_ObjBlockCounter : 31|4@0+ (1,0) [0|15] ""  Vector__XXX
 SG_ FRM_8_ObjID_10 : 39|8@0+ (1,0) [0|255] ""  Vector__XXX
 SG_ FRM_8_ObjClosestDistX_10 : 47|15@0+ (0.01,0) [0|200] "m"  Vector__XXX
 SG_ FRM_8_ObjClosestDistY_10 : 63|15@0+ (0.01,-100) [-100|100] "m"  Vector__XXX
 SG_ FRM_8_ObjRelVelX_10 : 79|15@0+ (0.01,-100) [-100|80] "m/s"  Vector__XXX
 SG_ FRM_8_ObjRelVelY_10 : 95|15@0+ (0.01,-100) [-100|80] "m/s"  Vector__XXX
 SG_ FRM_8_ObjAccelX_10 : 111|13@0+ (0.01,-25) [-25|25] "m/s^2"  Vector__XXX
 SG_ FRM_8_ObjAccelY_10 : 114|13@0+ (0.01,-25) [-25|25] "m/s^2"  Vector__XXX
 SG_ FRM_8_ObjClosestDistXStd_10 : 133|6@0+ (0.1,0) [0|5] ""  Vector__XXX
 SG_ FRM_8_ObjClosestDistYStd_10 : 143|6@0+ (0.1,0) [0|5] ""  Vector__XXX
 SG_ FRM_8_ObjRelVelXStd_10 : 137|7@0+ (0.05,0) [0|4] ""  Vector__XXX
 SG_ FRM_8_ObjRelVelYStd_10 : 146|7@0+ (0.05,0) [0|4] ""  Vector__XXX
 SG_ FRM_8_ObjRelAccelXStd_10 : 155|6@0+ (0.05,0) [0|3] ""  Vector__XXX
 SG_ FRM_8_ObjRelAccelYStd_10 : 165|6@0+ (0.05,0) [0|3] ""  Vector__XXX
 SG_ FRM_8_ObjExistProb_10 : 175|7@0+ (1,0) [0|100] "%"  Vector__XXX
 SG_ FRM_8_ObjType_10 : 168|2@0+ (1,0) [0|3] ""  Vector__XXX
 SG_ FRM_8_ObjTypeConf_10 : 182|7@0+ (1,0) [0|100] "%"  Vector__XXX
 SG_ FRM_8_ObjTrackSts_10 : 191|2@0+ (1,0) [0|3] ""  Vector__XXX
 SG_ FRM_8_ObjMotionSts_10 : 189|2@0+ (1,0) [0|3] ""  Vector__XXX
 SG_ FRM_8_ObjMotionDirection_10 : 187|2@0+ (1,0) [0|3] ""  Vector__XXX
 SG_ FRM_8_ObjCenterDistX_10 : 199|15@0+ (0.01,0) [0|200] "m"  Vector__XXX
 SG_ FRM_8_ObjCenterDistY_10 : 215|15@0+ (0.01,-100) [-100|100] "m"  Vector__XXX
 SG_ FRM_8_ObjLength_10 : 216|9@0+ (0.1,0) [0|50] "m"  Vector__XXX
 SG_ FRM_8_ObjWidth_10 : 239|9@0+ (0.1,0) [0|30] "m"  Vector__XXX
 SG_ FRM_8_ObjElevnSts_10 : 246|2@0+ (1,0) [0|3] ""  Vector__XXX
 SG_ FRM_8_ObjElevnStsConf_10 : 244|7@0+ (1,0) [0|100] "%"  Vector__XXX
 SG_ FRM_8_ObjHeading_10 : 253|12@0+ (0.1,-180) [-180|180] "deg"  Vector__XXX
 SG_ FRM_8_ObjID_11 : 271|8@0+ (1,0) [0|255] ""  Vector__XXX
 SG_ FRM_8_ObjClosestDistX_11 : 279|15@0+ (0.01,0) [0|200] "m"  Vector__XXX
 SG_ FRM_8_ObjClosestDistY_11 : 295|15@0+ (0.01,-100) [-100|100] "m"  Vector__XXX
 SG_ FRM_8_ObjRelVelX_11 : 311|15@0+ (0.01,-100) [-100|80] "m/s"  Vector__XXX
 SG_ FRM_8_ObjRelVelY_11 : 327|15@0+ (0.01,-100) [-100|80] "m/s"  Vector__XXX
 SG_ FRM_8_ObjAccelX_11 : 343|13@0+ (0.01,-25) [-25|25] "m/s^2"  Vector__XXX
 SG_ FRM_8_ObjAccelY_11 : 346|13@0+ (0.01,-25) [-25|25] "m/s^2"  Vector__XXX
 SG_ FRM_8_ObjClosestDistXStd_11 : 365|6@0+ (0.1,0) [0|5] ""  Vector__XXX
 SG_ FRM_8_ObjClosestDistYStd_11 : 375|6@0+ (0.1,0) [0|5] ""  Vector__XXX
 SG_ FRM_8_ObjRelVelXStd_11 : 369|7@0+ (0.05,0) [0|4] ""  Vector__XXX
 SG_ FRM_8_ObjRelVelYStd_11 : 378|7@0+ (0.05,0) [0|4] ""  Vector__XXX
 SG_ FRM_8_ObjRelAccelXStd_11 : 387|6@0+ (0.05,0) [0|3] ""  Vector__XXX
 SG_ FRM_8_ObjRelAccelYStd_11 : 397|6@0+ (0.05,0) [0|3] ""  Vector__XXX
 SG_ FRM_8_ObjExistProb_11 : 407|7@0+ (1,0) [0|100] "%"  Vector__XXX
 SG_ FRM_8_ObjType_11 : 400|2@0+ (1,0) [0|3] ""  Vector__XXX
 SG_ FRM_8_ObjTypeConf_11 : 414|7@0+ (1,0) [0|100] "%"  Vector__XXX
 SG_ FRM_8_ObjTrackSts_11 : 423|2@0+ (1,0) [0|3] ""  Vector__XXX
 SG_ FRM_8_ObjMotionSts_11 : 421|2@0+ (1,0) [0|3] ""  Vector__XXX
 SG_ FRM_8_ObjMotionDirection_11 : 419|2@0+ (1,0) [0|3] ""  Vector__XXX
 SG_ FRM_8_ObjCenterDistX_11 : 431|15@0+ (0.01,0) [0|200] "m"  Vector__XXX
 SG_ FRM_8_ObjCenterDistY_11 : 447|15@0+ (0.01,-100) [-100|100] "m"  Vector__XXX
 SG_ FRM_8_ObjLength_11 : 448|9@0+ (0.1,0) [0|50] "m"  Vector__XXX
 SG_ FRM_8_ObjWidth_11 : 471|9@0+ (0.1,0) [0|30] "m"  Vector__XXX
 SG_ FRM_8_ObjElevnSts_11 : 478|2@0+ (1,0) [0|3] ""  Vector__XXX
 SG_ FRM_8_ObjElevnStsConf_11 : 476|7@0+ (1,0) [0|100] "%"  Vector__XXX
 SG_ FRM_8_ObjHeading_11 : 485|12@0+ (0.1,-180) [-180|180] "deg"  Vector__XXX

BO_ 968 FRM_9: 64 FRM_FM_4X
 SG_ FRM_9_CRC : 7|16@0+ (1,0) [0|65535] ""  Vector__XXX
 SG_ FRM_9_RollgCntr : 23|8@0+ (1,0) [0|255] ""  Vector__XXX
 SG_ FRM_9_ObjBlockCounter : 31|4@0+ (1,0) [0|15] ""  Vector__XXX
 SG_ FRM_9_ObjID_12 : 39|8@0+ (1,0) [0|255] ""  Vector__XXX
 SG_ FRM_9_ObjClosestDistX_12 : 47|15@0+ (0.01,0) [0|200] "m"  Vector__XXX
 SG_ FRM_9_ObjClosestDistY_12 : 63|15@0+ (0.01,-100) [-100|100] "m"  Vector__XXX
 SG_ FRM_9_ObjRelVelX_12 : 79|15@0+ (0.01,-100) [-100|80] "m/s"  Vector__XXX
 SG_ FRM_9_ObjRelVelY_12 : 95|15@0+ (0.01,-100) [-100|80] "m/s"  Vector__XXX
 SG_ FRM_9_ObjAccelX_12 : 111|13@0+ (0.01,-25) [-25|25] "m/s^2"  Vector__XXX
 SG_ FRM_9_ObjAccelY_12 : 114|13@0+ (0.01,-25) [-25|25] "m/s^2"  Vector__XXX
 SG_ FRM_9_ObjClosestDistXStd_12 : 133|6@0+ (0.1,0) [0|5] ""  Vector__XXX
 SG_ FRM_9_ObjClosestDistYStd_12 : 143|6@0+ (0.1,0) [0|5] ""  Vector__XXX
 SG_ FRM_9_ObjRelVelXStd_12 : 137|7@0+ (0.05,0) [0|4] ""  Vector__XXX
 SG_ FRM_9_ObjRelVelYStd_12 : 146|7@0+ (0.05,0) [0|4] ""  Vector__XXX
 SG_ FRM_9_ObjRelAccelXStd_12 : 155|6@0+ (0.05,0) [0|3] ""  Vector__XXX
 SG_ FRM_9_ObjRelAccelYStd_12 : 165|6@0+ (0.05,0) [0|3] ""  Vector__XXX
 SG_ FRM_9_ObjExistProb_12 : 175|7@0+ (1,0) [0|100] "%"  Vector__XXX
 SG_ FRM_9_ObjType_12 : 168|2@0+ (1,0) [0|3] ""  Vector__XXX
 SG_ FRM_9_ObjTypeConf_12 : 182|7@0+ (1,0) [0|100] "%"  Vector__XXX
 SG_ FRM_9_ObjTrackSts_12 : 191|2@0+ (1,0) [0|3] ""  Vector__XXX
 SG_ FRM_9_ObjMotionSts_12 : 189|2@0+ (1,0) [0|3] ""  Vector__XXX
 SG_ FRM_9_ObjMotionDirection_12 : 187|2@0+ (1,0) [0|3] ""  Vector__XXX
 SG_ FRM_9_ObjCenterDistX_12 : 199|15@0+ (0.01,0) [0|200] "m"  Vector__XXX
 SG_ FRM_9_ObjCenterDistY_12 : 215|15@0+ (0.01,-100) [-100|100] "m"  Vector__XXX
 SG_ FRM_9_ObjLength_12 : 216|9@0+ (0.1,0) [0|50] "m"  Vector__XXX
 SG_ FRM_9_ObjWidth_12 : 239|9@0+ (0.1,0) [0|30] "m"  Vector__XXX
 SG_ FRM_9_ObjElevnSts_12 : 246|2@0+ (1,0) [0|3] ""  Vector__XXX
 SG_ FRM_9_ObjElevnStsConf_12 : 244|7@0+ (1,0) [0|100] "%"  Vector__XXX
 SG_ FRM_9_ObjHeading_12 : 253|12@0+ (0.1,-180) [-180|180] "deg"  Vector__XXX
 SG_ FRM_9_ObjID_13 : 271|8@0+ (1,0) [0|255] ""  Vector__XXX
 SG_ FRM_9_ObjClosestDistX_13 : 279|15@0+ (0.01,0) [0|200] "m"  Vector__XXX
 SG_ FRM_9_ObjClosestDistY_13 : 295|15@0+ (0.01,-100) [-100|100] "m"  Vector__XXX
 SG_ FRM_9_ObjRelVelX_13 : 311|15@0+ (0.01,-100) [-100|80] "m/s"  Vector__XXX
 SG_ FRM_9_ObjRelVelY_13 : 327|15@0+ (0.01,-100) [-100|80] "m/s"  Vector__XXX
 SG_ FRM_9_ObjAccelX_13 : 343|13@0+ (0.01,-25) [-25|25] "m/s^2"  Vector__XXX
 SG_ FRM_9_ObjAccelY_13 : 346|13@0+ (0.01,-25) [-25|25] "m/s^2"  Vector__XXX
 SG_ FRM_9_ObjClosestDistXStd_13 : 365|6@0+ (0.1,0) [0|5] ""  Vector__XXX
 SG_ FRM_9_ObjClosestDistYStd_13 : 375|6@0+ (0.1,0) [0|5] ""  Vector__XXX
 SG_ FRM_9_ObjRelVelXStd_13 : 369|7@0+ (0.05,0) [0|4] ""  Vector__XXX
 SG_ FRM_9_ObjRelVelYStd_13 : 378|7@0+ (0.05,0) [0|4] ""  Vector__XXX
 SG_ FRM_9_ObjRelAccelXStd_13 : 387|6@0+ (0.05,0) [0|3] ""  Vector__XXX
 SG_ FRM_9_ObjRelAccelYStd_13 : 397|6@0+ (0.05,0) [0|3] ""  Vector__XXX
 SG_ FRM_9_ObjExistProb_13 : 407|7@0+ (1,0) [0|100] "%"  Vector__XXX
 SG_ FRM_9_ObjType_13 : 400|2@0+ (1,0) [0|3] ""  Vector__XXX
 SG_ FRM_9_ObjTypeConf_13 : 414|7@0+ (1,0) [0|100] "%"  Vector__XXX
 SG_ FRM_9_ObjTrackSts_13 : 423|2@0+ (1,0) [0|3] ""  Vector__XXX
 SG_ FRM_9_ObjMotionSts_13 : 421|2@0+ (1,0) [0|3] ""  Vector__XXX
 SG_ FRM_9_ObjMotionDirection_13 : 419|2@0+ (1,0) [0|3] ""  Vector__XXX
 SG_ FRM_9_ObjCenterDistX_13 : 431|15@0+ (0.01,0) [0|200] "m"  Vector__XXX
 SG_ FRM_9_ObjCenterDistY_13 : 447|15@0+ (0.01,-100) [-100|100] "m"  Vector__XXX
 SG_ FRM_9_ObjLength_13 : 448|9@0+ (0.1,0) [0|50] "m"  Vector__XXX
 SG_ FRM_9_ObjWidth_13 : 471|9@0+ (0.1,0) [0|30] "m"  Vector__XXX
 SG_ FRM_9_ObjElevnSts_13 : 478|2@0+ (1,0) [0|3] ""  Vector__XXX
 SG_ FRM_9_ObjElevnStsConf_13 : 476|7@0+ (1,0) [0|100] "%"  Vector__XXX
 SG_ FRM_9_ObjHeading_13 : 485|12@0+ (0.1,-180) [-180|180] "deg"  Vector__XXX

BO_ 969 FRM_10: 64 FRM_FM_4X
 SG_ FRM_10_CRC : 7|16@0+ (1,0) [0|65535] ""  Vector__XXX
 SG_ FRM_10_RollgCntr : 23|8@0+ (1,0) [0|255] ""  Vector__XXX
 SG_ FRM_10_ObjBlockCounter : 31|4@0+ (1,0) [0|15] ""  Vector__XXX
 SG_ FRM_10_ObjID_14 : 39|8@0+ (1,0) [0|255] ""  Vector__XXX
 SG_ FRM_10_ObjClosestDistX_14 : 47|15@0+ (0.01,0) [0|200] "m"  Vector__XXX
 SG_ FRM_10_ObjClosestDistY_14 : 63|15@0+ (0.01,-100) [-100|100] "m"  Vector__XXX
 SG_ FRM_10_ObjRelVelX_14 : 79|15@0+ (0.01,-100) [-100|80] "m/s"  Vector__XXX
 SG_ FRM_10_ObjRelVelY_14 : 95|15@0+ (0.01,-100) [-100|80] "m/s"  Vector__XXX
 SG_ FRM_10_ObjAccelX_14 : 111|13@0+ (0.01,-25) [-25|25] "m/s^2"  Vector__XXX
 SG_ FRM_10_ObjAccelY_14 : 114|13@0+ (0.01,-25) [-25|25] "m/s^2"  Vector__XXX
 SG_ FRM_10_ObjClosestDistXStd_14 : 133|6@0+ (0.1,0) [0|5] ""  Vector__XXX
 SG_ FRM_10_ObjClosestDistYStd_14 : 143|6@0+ (0.1,0) [0|5] ""  Vector__XXX
 SG_ FRM_10_ObjRelVelXStd_14 : 137|7@0+ (0.05,0) [0|4] ""  Vector__XXX
 SG_ FRM_10_ObjRelVelYStd_14 : 146|7@0+ (0.05,0) [0|4] ""  Vector__XXX
 SG_ FRM_10_ObjRelAccelXStd_14 : 155|6@0+ (0.05,0) [0|3] ""  Vector__XXX
 SG_ FRM_10_ObjRelAccelYStd_14 : 165|6@0+ (0.05,0) [0|3] ""  Vector__XXX
 SG_ FRM_10_ObjExistProb_14 : 175|7@0+ (1,0) [0|100] "%"  Vector__XXX
 SG_ FRM_10_ObjType_14 : 168|2@0+ (1,0) [0|3] ""  Vector__XXX
 SG_ FRM_10_ObjTypeConf_14 : 182|7@0+ (1,0) [0|100] "%"  Vector__XXX
 SG_ FRM_10_ObjTrackSts_14 : 191|2@0+ (1,0) [0|3] ""  Vector__XXX
 SG_ FRM_10_ObjMotionSts_14 : 189|2@0+ (1,0) [0|3] ""  Vector__XXX
 SG_ FRM_10_ObjMotionDirection_14 : 187|2@0+ (1,0) [0|3] ""  Vector__XXX
 SG_ FRM_10_ObjCenterDistX_14 : 199|15@0+ (0.01,0) [0|200] "m"  Vector__XXX
 SG_ FRM_10_ObjCenterDistY_14 : 215|15@0+ (0.01,-100) [-100|100] "m"  Vector__XXX
 SG_ FRM_10_ObjLength_14 : 216|9@0+ (0.1,0) [0|50] "m"  Vector__XXX
 SG_ FRM_10_ObjWidth_14 : 239|9@0+ (0.1,0) [0|30] "m"  Vector__XXX
 SG_ FRM_10_ObjElevnSts_14 : 246|2@0+ (1,0) [0|3] ""  Vector__XXX
 SG_ FRM_10_ObjElevnStsConf_14 : 244|7@0+ (1,0) [0|100] "%"  Vector__XXX
 SG_ FRM_10_ObjHeading_14 : 253|12@0+ (0.1,-180) [-180|180] "deg"  Vector__XXX
 SG_ FRM_10_ObjID_15 : 271|8@0+ (1,0) [0|255] ""  Vector__XXX
 SG_ FRM_10_ObjClosestDistX_15 : 279|15@0+ (0.01,0) [0|200] "m"  Vector__XXX
 SG_ FRM_10_ObjClosestDistY_15 : 295|15@0+ (0.01,-100) [-100|100] "m"  Vector__XXX
 SG_ FRM_10_ObjRelVelX_15 : 311|15@0+ (0.01,-100) [-100|80] "m/s"  Vector__XXX
 SG_ FRM_10_ObjRelVelY_15 : 327|15@0+ (0.01,-100) [-100|80] "m/s"  Vector__XXX
 SG_ FRM_10_ObjAccelX_15 : 343|13@0+ (0.01,-25) [-25|25] "m/s^2"  Vector__XXX
 SG_ FRM_10_ObjAccelY_15 : 346|13@0+ (0.01,-25) [-25|25] "m/s^2"  Vector__XXX
 SG_ FRM_10_ObjClosestDistXStd_15 : 365|6@0+ (0.1,0) [0|5] ""  Vector__XXX
 SG_ FRM_10_ObjClosestDistYStd_15 : 375|6@0+ (0.1,0) [0|5] ""  Vector__XXX
 SG_ FRM_10_ObjRelVelXStd_15 : 369|7@0+ (0.05,0) [0|4] ""  Vector__XXX
 SG_ FRM_10_ObjRelVelYStd_15 : 378|7@0+ (0.05,0) [0|4] ""  Vector__XXX
 SG_ FRM_10_ObjRelAccelXStd_15 : 387|6@0+ (0.05,0) [0|3] ""  Vector__XXX
 SG_ FRM_10_ObjRelAccelYStd_15 : 397|6@0+ (0.05,0) [0|3] ""  Vector__XXX
 SG_ FRM_10_ObjExistProb_15 : 407|7@0+ (1,0) [0|100] "%"  Vector__XXX
 SG_ FRM_10_ObjType_15 : 400|2@0+ (1,0) [0|3] ""  Vector__XXX
 SG_ FRM_10_ObjTypeConf_15 : 414|7@0+ (1,0) [0|100] "%"  Vector__XXX
 SG_ FRM_10_ObjTrackSts_15 : 423|2@0+ (1,0) [0|3] ""  Vector__XXX
 SG_ FRM_10_ObjMotionSts_15 : 421|2@0+ (1,0) [0|3] ""  Vector__XXX
 SG_ FRM_10_ObjMotionDirection_15 : 419|2@0+ (1,0) [0|3] ""  Vector__XXX
 SG_ FRM_10_ObjCenterDistX_15 : 431|15@0+ (0.01,0) [0|200] "m"  Vector__XXX
 SG_ FRM_10_ObjCenterDistY_15 : 447|15@0+ (0.01,-100) [-100|100] "m"  Vector__XXX
 SG_ FRM_10_ObjLength_15 : 448|9@0+ (0.1,0) [0|50] "m"  Vector__XXX
 SG_ FRM_10_ObjWidth_15 : 471|9@0+ (0.1,0) [0|30] "m"  Vector__XXX
 SG_ FRM_10_ObjElevnSts_15 : 478|2@0+ (1,0) [0|3] ""  Vector__XXX
 SG_ FRM_10_ObjElevnStsConf_15 : 476|7@0+ (1,0) [0|100] "%"  Vector__XXX
 SG_ FRM_10_ObjHeading_15 : 485|12@0+ (0.1,-180) [-180|180] "deg"  Vector__XXX

CM_ "Version:V3.0,Date:2024.06.05,Author:ZhengFang,Review:ZhonglingWang,Approval:JiancaiLi,Description:()based on V3.2 of REEV(横置);
 ";

CM_ BO_ 1301 "中高配以ADCC时间同步信息为主";
CM_ BO_ 1304 "低配ADCC不发";
CM_ BO_ 961 "禾多配置不发此帧报文";
CM_ SG_ 1301 TimeSync_Type "Mode Signal: Multiplexer: 0x20 = SYNC with CRC, 0x28 = FUP with CRC, 0x10 = SYNC, 0x18 = FUP";
CM_ SG_ 1301 TimeSync_CRC "CRC calculation: AUTOSAR_SWS_CRCLibrary.pdf, function Crc_CalculateCRC8H2F()";
CM_ SG_ 1301 TimeSync_SequenceCounter "SC = Sequence Counter";
CM_ SG_ 1301 TimeSync_TimeDomain "Time Domain 0 to 15";
CM_ SG_ 1301 TimeSync_UserByte0 "Mode 32:UserByte0";
CM_ SG_ 1301 TimeSync_SyncTimeSec "Mode 32:SyncTime: seconds";
CM_ SG_ 1301 TimeSync_OverflowOfSeconds "Mode 40:OVS = Overflow of seconds, must be added to SyncTimeSec";
CM_ SG_ 1301 TimeSync_SGW "Mode 40:SyncToGTM = 0
SyncToSubDomain = 1";
CM_ SG_ 1301 TimeSync_Reserved0 "Mode 40:FUP Byte3: Bit7 to Bit3 reserved area";
CM_ SG_ 1301 TimeSync_SyncTimeNSec "Mode 40:SyncTime: nanoseconds";
CM_ SG_ 1304 TimeSync_Type "Mode Signal: Multiplexer: 0x20 = SYNC with CRC, 0x28 = FUP with CRC, 0x10 = SYNC, 0x18 = FUP";
CM_ SG_ 1304 TimeSync_CRC "CRC calculation: AUTOSAR_SWS_CRCLibrary.pdf, function Crc_CalculateCRC8H2F()";
CM_ SG_ 1304 TimeSync_SequenceCounter "SC = Sequence Counter";
CM_ SG_ 1304 TimeSync_TimeDomain "Time Domain 0 to 15";
CM_ SG_ 1304 TimeSync_UserByte0 "Mode 32:UserByte0";
CM_ SG_ 1304 TimeSync_SyncTimeSec "Mode 32:SyncTime: seconds";
CM_ SG_ 1304 TimeSync_OverflowOfSeconds "Mode 40:OVS = Overflow of seconds, must be added to SyncTimeSec";
CM_ SG_ 1304 TimeSync_SGW "Mode 40:SyncToGTM = 0
SyncToSubDomain = 1";
CM_ SG_ 1304 TimeSync_Reserved0 "Mode 40:FUP Byte3: Bit7 to Bit3 reserved area";
CM_ SG_ 1304 TimeSync_SyncTimeNSec "Mode 40:SyncTime: nanoseconds";
CM_ SG_ 960 FRM_1_CRC "Profile5:E2E CRC16 (polynomial:0x1021)       
DataID:Use CANID,other bits Fill with 0";
CM_ SG_ 960 FRM_1_RollgCntr "Profile5:E2E Rolling message counter";
CM_ SG_ 960 FRM_1_ObjHd_ObjBlockCounter "Front Radar Moudle_1_Object Header_Object Block Counter 
前雷达目标物前言：块计数值";
CM_ SG_ 960 FRM_1_ObjHd_MountPosX "Front Radar Moudle_1_Object Header_Mount Position X Direction
前雷达目标物前言：雷达在X方向安装位置
mount offset of sensor in longitudinal direction relative to rear axis of vehicle";
CM_ SG_ 960 FRM_1_ObjHd_MountPosY "Front Radar Moudle_1_Object Header_Mount Position Y Direction
前雷达目标物前言：雷达在Y方向安装位置
mount offset of sensor in lateral direction relative to mid axis of vehicle";
CM_ SG_ 960 FRM_1_ObjHd_MountPosZ "Front Radar Moudle_1_Object Header_Mount Position Z Direction
前雷达目标物前言：雷达在Z方向安装位置
mount offset of sensor in elevation direction relative to GROUND";
CM_ SG_ 960 FRM_1_ObjHd_MountAngleYaw "Front Radar Moudle_1_Object Header_Mount AngleYaw
前雷达目标物前言：雷达安装位置偏航角
angle between sensor mounting direction(boresight direction) and vehicle longitudinal axis, Azimuth";
CM_ SG_ 960 FRM_1_ObjHd_MountAnglePitch "Front Radar Moudle_1_Object Header_Mount Angle Pitch
前雷达目标物前言：雷达安装位置俯仰角
angle between sensor mounting direction(boresight direction) and vehicle longitudinal axis, Elevation";
CM_ SG_ 960 FRM_1_ObjHd_MountAngleRoll "Front Radar Moudle_1_Object Header_Mount Angle Roll
前雷达目标物前言：雷达安装倾斜角
Tilt of the mounting sensor";
CM_ SG_ 960 FRM_1_ObjHd_AlignAglYawErrCurr "Front Radar Moudle_1_Object Header_Alignment AngleYaw Erro Current
前雷达目标物前言：雷达当前校准的偏航角误差
Current sensor mounting azimuth angle error by auto-alignment";
CM_ SG_ 960 FRM_1_ObjHd_AlignAglYawErrEOL "Front Radar Moudle_1_Object Header_Alignment AngleYaw Erro EOL
前雷达目标物前言：雷达产线校准的偏航角误差
Recorded sensor mounting azimuth angle error by EOL-alignment";
CM_ SG_ 960 FRM_1_ObjHd_AlignAglPitchErrEOL "Front Radar Moudle_1_Object Header_Alignment Angle Pitch Erro EOL
前雷达目标物前言：雷达产线校准的俯仰角误差
Recorded sensor mounting elevation angle error by EOL-alignment";
CM_ SG_ 960 FRM_1_ObjHd_FOVYawAglLower "Front Radar Moudle_1_Object Header_Field Of View Yaw Angle Lower
前雷达目标物前言：雷达在偏航方向上的下视场角
Lower angle of the fied of view Azimuth";
CM_ SG_ 960 FRM_1_ObjHd_FOVYawAglUpper "Front Radar Moudle_1_Object Header_Field Of View Yaw Angle Upper
前雷达目标物前言：雷达在偏航方向上的上视场角
Upper angle of the field of view Azimuth based on sensro boresight direction";
CM_ SG_ 960 FRM_1_ObjHd_FOVPitchAglLower "Front Radar Moudle_1_Object Header_Field Of View Pitch Angle Lower
前雷达目标物前言：雷达在俯仰方向上的下视场
Lower angle of the fied of view Elevation based on sensro boresight direction";
CM_ SG_ 960 FRM_1_ObjHd_FOVPitchAglUpper "Front Radar Moudle_1_Object Header_Field Of View Pitch Angle Upper
前雷达目标物前言：雷达在俯仰方向上的上视场
Upper angle of the field of view Elevation based on sensro boresight direction";
CM_ SG_ 960 FRM_1_ObjHd_MaxDetectionRange "Front Radar Moudle_1_Object Header_Maximun Detection Range
前雷达目标物前言：雷达最大探测范围
Estimated detection range of the sensor";
CM_ SG_ 960 FRM_1_ObjHd_HWFail "Front Radar Moudle_1_Object Header_Hardware Fail
前雷达目标物前言：雷达硬件故障
Flag To Indicate If Sensor Hardware Failure Is Exist Or Not";
CM_ SG_ 960 FRM_1_ObjHd_Misalignment "Front Radar Moudle_1_Object Header_Misalignment
前雷达目标物前言：雷达失校准
Flag To Indicate If Alignment Out Of Spec";
CM_ SG_ 960 FRM_1_ObjHd_AlignmentNotDone "Front Radar Moudle_1_Object Header_Alignment Not Done
前雷达目标物前言：雷达未校准
Flag To Indicate if Alignment Has Been Done or Not";
CM_ SG_ 960 FRM_1_ObjHd_SensorBlockage "Front Radar Moudle_1_Object Header_Sensor Blockage
前雷达目标物前言：雷达被遮挡
Flag To Indicate If Sensor Is Blind Or Not";
CM_ SG_ 960 FRM_1_ObjHd_ObjDetFail "Front Radar Moudle_1_Object Header_Object Detection Fail
前雷达目标物前言：雷达目标探测失效
Indicates An Error In The Object Detection System. This flag include all conditions that shall impact radar detection performance, like HWFailure, Misalignment, AlignmentNotDone, SensorBlockage, OutOfVoltage, OverTemperature, ReceivedCANTimeOut, ReceivedCANInvalid, RF-BoardNoWorking.";
CM_ SG_ 960 FRM_1_ObjHd_OutOfVoltage "Front Radar Moudle_1_Object Header_Out Of Voltage
前雷达目标物前言：雷达电压超范围
Indicates An Error Of Over Or Under Voltage";
CM_ SG_ 960 FRM_1_ObjHd_OverTemperature "Front Radar Moudle_1_Detection Header_Over Temperature
前雷达目标物前言：雷达温度过高
Indicates An Error Of Over Temperature";
CM_ SG_ 960 FRM_1_ObjHd_ReceivedCANTimeOut "Front Radar Moudle_1_Object Header_Received CAN Time Out
前雷达目标物前言：雷达接收CAN信号超时
Flag To Indicate If Received CAN Signal Time Out Or Not";
CM_ SG_ 960 FRM_1_ObjHd_ReceivedCANInvalid "Front Radar Moudle_1_Object Header_Received CAN Invalid
前雷达目标物前言：雷达接收到无效CAN信号
Flag To Indicate If Received CAN Signal Invalid Or Not";
CM_ SG_ 960 FRM_1_ObjHd_RFBoardWorkingSts "Front Radar Moudle_1_Object Header_Radial Frequency Board Working Status
前雷达目标物前言：雷达射频板工作状态
Flag To Indicate Sensor RF Board Working Or Not. This flag shall set to 0x1 NoWokring only when RF Board power cutted off via UDS command actively. RF Board failure shall not set this flag.";
CM_ SG_ 960 FRM_1_ObjHd_ValidObjCount "Front Radar Moudle_1_Object Header_Valid Object Count
前雷达目标物前言：雷达有效目标物数量
number of detected VALID Objects that have been sent to the bus";
CM_ SG_ 960 FRM_1_ObjHd_ObjDownSel "Front Radar Moudle_1_Object Header_Object Down Select
前雷达目标物前言：雷达目标物输出达到上限
the detected number of objects exceeded the number of max. objects that can be transmitted";
CM_ SG_ 960 FRM_1_ObjHd_ObjTimeStamp "Front Radar Moudle_1_Object Header_Object Time Stamp
前雷达目标物前言：目标物的时间戳
Captured time of object based on local time base of FRM which is synchronized by global time periodically";
CM_ SG_ 960 FRM_1_ObjHd_ObjTimeStampSts "Front Radar Moudle_1_Object Header_Object Time Stamp Status
前雷达目标物前言：目标物时间戳状态
Autosar StbM_TimeBaseStatusType bitfield
Bit 0: TIMEOUT
Bit 1: SYNC_TO_GATEWAY
Bit 2: GLOBAL_TIME_BASE
Bit 3: TIMELEAP_FUTURE
Bit 4: TIMELEAP_PAST";
CM_ SG_ 960 FRM_1_ObjHd_ObjTimeLatency "Front Radar Moudle_1_Object Header_Object Time Latency
前雷达目标物前言：目标物时间延迟
Sensor latency from object capture scene to object transmission";
CM_ SG_ 960 FRM_1_ObjHd_NotConfigured "Front Radar Moudle_1_Object Header_Not Configured
前雷达目标物前言：雷达未配置
Flag To Indicate If Radar Configured Or Not";
CM_ SG_ 960 FRM_1_ObjHd_ParameterInvalid "Front Radar Moudle_1_Object Header_Parameter Invalid
前雷达目标物前言：雷达参数无效
Flag To Indicate If Parameter Invalid Or Not";
CM_ SG_ 961 FRM_2_CRC "Profile5:E2E CRC16 (polynomial:0x1021)       
DataID:Use CANID,other bits Fill with 0";
CM_ SG_ 961 FRM_2_RollgCntr "Profile5:E2E Rolling message counter";
CM_ SG_ 961 FRM_2_DetnHd_DetnBlockCounter "Front Radar Moudle_2_Detection Header_Detection Block Counter 
前雷达探测点前言：块计数值";
CM_ SG_ 961 FRM_2_DetnHd_MountPosX "Front Radar Moudle_2_Detection Header_Mount Position X
前雷达探测点前言：雷达在X方向安装位置
mount offset of sensor in longitudinal direction relative to rear axis of vehicle";
CM_ SG_ 961 FRM_2_DetnHd_MountPosY "Front Radar Moudle_2_Detection Header_Mount Position Y
前雷达探测点前言：雷达在Y方向安装位置
mount offset of sensor in lateral direction relative to mid axis of vehicle";
CM_ SG_ 961 FRM_2_DetnHd_MountPosZ "Front Radar Moudle_2_Detection Header_Mount Position Z
前雷达探测点前言：雷达在Z方向安装位置
mount offset of sensor in elevation direction relative to GROUND";
CM_ SG_ 961 FRM_2_DetnHd_MountAngleYaw "Front Radar Moudle_2_Detection Header_Mount AngleYaw
前雷达探测点前言：雷达安装位置偏航角
angle between sensor mounting direction(boresight direction) and vehicle longitudinal axis, Azimuth";
CM_ SG_ 961 FRM_2_DetnHd_MountAnglePitch "Front Radar Moudle_2_Detection Header_Mount Angle Pitch
前雷达探测点前言：雷达安装位置俯仰角
angle between sensor mounting direction(boresight direction) and vehicle longitudinal axis, Elevation";
CM_ SG_ 961 FRM_2_DetnHd_MountAngleRoll "Front Radar Moudle_2_Detection Header_Mount Angle Roll
前雷达探测点前言：雷达安装倾斜角
Tilt of the mounting sensor";
CM_ SG_ 961 FRM_2_DetnHd_AlignAglYawErrCurr "Front Radar Moudle_2_Detection Header_Alignment AngleYaw Erro Current
前雷达探测点前言：雷达当前校准的偏航角误差
Current sensor mounting azimuth angle error by auto-alignment";
CM_ SG_ 961 FRM_2_DetnHd_AlignAglYawErrEOL "Front Radar Moudle_2_Detection Header_Alignment AngleYaw ErroEOL
前雷达探测点前言：雷达产线校准的偏航角误差
Recorded sensor mounting azimuth angle error by EOL-alignment";
CM_ SG_ 961 FRM_2_DetnHd_AlignAglPitchErrEOL "Front Radar Moudle_2_Detection Header_Alignment Angle Pitch Erro EOL
前雷达探测点前言：雷达产线校准的俯仰角误差
Recorded sensor mounting elevation angle error by EOL-alignment";
CM_ SG_ 961 FRM_2_DetnHd_FOVYawAglLower "Front Radar Moudle_2_Detection Header_Field Of View Yaw Angle Lower
前雷达探测点前言：雷达在偏航方向上的下视场角
Lower angle of the fied of view Azimuth";
CM_ SG_ 961 FRM_2_DetnHd_FOVYawAglUpper "Front Radar Moudle_2_Detection Header_Field Of View Yaw Angle Upper
前雷达探测点前言：雷达在偏航方向上的上视场角
Upper angle of the field of view Azimuth based on sensro boresight direction";
CM_ SG_ 961 FRM_2_DetnHd_FOVPitchAglLower "Front Radar Moudle_2_Detection Header_Field Of View Pitch Angle Lower
前雷达探测点前言：雷达在俯仰方向上的下视场
Lower angle of the fied of view Elevation based on sensro boresight direction";
CM_ SG_ 961 FRM_2_DetnHd_FOVPitchAglUpper "Front Radar Moudle_2_Detection Header_Field Of View Pitch Angle Upper
前雷达探测点前言：雷达在俯仰方向上的上视场
Upper angle of the field of view Elevation based on sensro boresight direction";
CM_ SG_ 961 FRM_2_DetnHd_MaxDetectionRange "Front Radar Moudle_2_Detection Header_Maximun Detection Range
前雷达探测点前言：雷达最大探测范围
Estimated detection range of the sensor";
CM_ SG_ 961 FRM_2_DetnHd_HWFail "Front Radar Moudle_2_Detection Header_Hardware Fail
前雷达探测点前言：雷达硬件故障
Flag To Indicate If Sensor Hardware Failure Is Exist Or Not";
CM_ SG_ 961 FRM_2_DetnHd_Misalignment "Front Radar Moudle_2_Detection Header_Misalignment
前雷达探测点前言：雷达失校准
Flag To Indicate If Alignment Out Of Spec";
CM_ SG_ 961 FRM_2_DetnHd_AlignmentNotDone "Front Radar Moudle_2_Detection Header_Alignment Not Done
前雷达探测点前言：雷达未校准
Flag To Indicate if Alignment Has Been Done or Not";
CM_ SG_ 961 FRM_2_DetnHd_SensorBlockage "Front Radar Moudle_2_Detection Header_Sensor Blockage
前雷达探测点前言：雷达被遮挡
Flag To Indicate If Sensor Is Blind Or Not";
CM_ SG_ 961 FRM_2_DetnHd_ObjDetFail "Front Radar Moudle_2_Detection Header_Object Detection Fail
前雷达探测点前言：雷达目标探测失效
Indicates An Error In The Object Detection System. This flag include all conditions that shall impact radar detection performance, like HWFailure, Misalignment, AlignmentNotDone, SensorBlockage, OutOfVoltage, OverTemperature, ReceivedCANTimeOut, ReceivedCANInvalid, RF-BoardNoWorking.";
CM_ SG_ 961 FRM_2_DetnHd_OutOfVoltage "Front Radar Moudle_2_Detection Header_Out Of Voltage
前雷达探测点前言：雷达电压超范围
Indicates An Error Of Over Or Under Voltage";
CM_ SG_ 961 FRM_2_DetnHd_OverTemperature "Front Radar Moudle_2_Detection Header_Over Temperature
前雷达探测点前言：雷达温度过高
Indicates An Error Of Over Temperature";
CM_ SG_ 961 FRM_2_DetnHd_ReceivedCANTimeOut "Front Radar Moudle_2_Detection Header_Received CAN Time Out
前雷达探测点前言：雷达接收CAN信号超时
Flag To Indicate If Received CAN Signal Time Out Or Not";
CM_ SG_ 961 FRM_2_DetnHd_ReceivedCANInvalid "Front Radar Moudle_2_Detection Header_Received CAN Invalid
前雷达探测点前言：雷达接收到无效CAN信号
Flag To Indicate If Received CAN Signal Invalid Or Not";
CM_ SG_ 961 FRM_2_DetnHd_RFBoardWorkingSts "Front Radar Moudle_2_Detection Header_Radial Frequency Board Working Status
前雷达探测点前言：雷达射频板工作状态
Flag To Indicate Sensor RF Board Working Or Not. This flag shall set to 0x1 NoWokring only when RF Board power cutted off via UDS command actively. RF Board failure shall not set this flag.";
CM_ SG_ 961 FRM_2_DetnHd_ValidDetnCount "Front Radar Moudle_2_Detection Header_Valid Detection Count
前雷达探测点前言：雷达有效探测点数量
number of detected VALID Objects that have been sent to the bus";
CM_ SG_ 961 FRM_2_DetnHd_DetnDownSel "Front Radar Moudle_2_Detection Header_Detection Down Select
前雷达探测点前言：雷达探测点输出达到上限
the detected number of objects exceeded the number of max. objects that can be transmitted";
CM_ SG_ 961 FRM_2_DetnHd_DetnTimeStamp "Front Radar Moudle_2_Detection Header_Detection Time Stamp
前雷达探测点前言：探测点的时间戳
Captured time of object based on local time base of FRM which is synchronized by global time periodically";
CM_ SG_ 961 FRM_2_DetnHd_DetnTimeStampSts "Front Radar Moudle_2_Detection Header_Detection Time Stamp Status
前雷达探测点前言：探测点时间戳状态
Autosar StbM_TimeBaseStatusType bitfield
Bit 0: TIMEOUT
Bit 1: SYNC_TO_GATEWAY
Bit 2: GLOBAL_TIME_BASE
Bit 3: TIMELEAP_FUTURE
Bit 4: TIMELEAP_PAST";
CM_ SG_ 961 FRM_2_DetnHd_DetnTimeLatency "Front Radar Moudle_2_Detection Header_Detection Time Latency
前雷达探测点前言：探测点时间延迟
Sensor latency from object capture scene to object transmission";
CM_ SG_ 961 FRM_2_DetnHd_NotConfigured "Front Radar Moudle_2_Detection Header_Not Configured
前雷达探测点前言：雷达未配置
Flag To Indicate If Radar Configured Or Not";
CM_ SG_ 961 FRM_2_DetnHd_ParameterInvalid "Front Radar Moudle_2_Detection Header_Parameter Invalid
前雷达探测点前言：雷达参数无效
Flag To Indicate If Parameter Invalid Or Not";
CM_ SG_ 962 FRM_3_CRC "Profile5:E2E CRC16 (polynomial:0x1021)       
DataID:Use CANID,other bits Fill with 0";
CM_ SG_ 962 FRM_3_RollgCntr "Profile5:E2E Rolling message counter";
CM_ SG_ 962 FRM_3_ObjBlockCounter "Front Radar Moudle_X_Object Block Counter
前雷达目标物块计数值";
CM_ SG_ 962 FRM_3_ObjID_00 "Front Radar Moudle_X_Object ID_00
前雷达目标物身份标识码_00
ID Is An Identifier Number That Allows For Tracking Of Persistent Objects Over Time
Note:A value of 0 indicates 'no object'";
CM_ SG_ 962 FRM_3_ObjClosestDistX_00 "Front Radar Moudle_X_Object Closest Distance X_00
前雷达目标物最近点在X轴上的距离_00
Closest Position Of Target Vehicle In X Direction
The rear axle center coordinate system is used";
CM_ SG_ 962 FRM_3_ObjClosestDistY_00 "Front Radar Moudle_X_Object Closest Distance Y_00
前雷达距目标物最近点在Y轴上的距离_00
Closest Position Of Target Vehicle In Y Direction
The rear axle center coordinate system is used";
CM_ SG_ 962 FRM_3_ObjRelVelX_00 "Front Radar Moudle_X_Object Relative Velocity X_00
前雷达目标物在X轴上的相对速度_00
Relative Target Object Velocity In X Direction";
CM_ SG_ 962 FRM_3_ObjRelVelY_00 "Front Radar Moudle_X_Object Relative Velocity Y_00
前雷达目标物在Y轴上的相对速度_00
Relative Target Object Velocity In Y Direction";
CM_ SG_ 962 FRM_3_ObjAccelX_00 "Front Radar Moudle_X_Object Acceleration X_00
前雷达目标物在X轴上的加速度_00
Relative Target Object Acceleration In X Direction";
CM_ SG_ 962 FRM_3_ObjAccelY_00 "Front Radar Moudle_X_Object Acceleration Y_00
前雷达目标物在Y轴上的加速度_00
Relative Target Object Acceleration In Y Direction";
CM_ SG_ 962 FRM_3_ObjClosestDistXStd_00 "Front Radar Moudle_X_Object Closest Distance X Standard_00
前雷达目标物最近点在X轴上的距离的标准差_00
Standard Deviation Of Closest Position Of Target Vehicle in X Direction";
CM_ SG_ 962 FRM_3_ObjClosestDistYStd_00 "Front Radar Moudle_X_Object Closest Distance Y Standard_00
前雷达目标物最近点在Y轴上的距离的标准差_00
Standard Deviation Of Closest Position Of Target Vehicle in Y Direction";
CM_ SG_ 962 FRM_3_ObjRelVelXStd_00 "Front Radar Moudle_X_Object Relative Velocity X Standard_00
前雷达目标物在X轴上的相对速度的标准差_00
Standard Deviation Of Relative Velocity X";
CM_ SG_ 962 FRM_3_ObjRelVelYStd_00 "Front Radar Moudle_X_Object Relative Velocity Y Standard_00
前雷达目标物在Y轴上的相对速度的标准差_00
Standard Deviation Of Relative Velocity Y";
CM_ SG_ 962 FRM_3_ObjRelAccelXStd_00 "Front Radar Moudle_X_Object Relative  Acceleration X Standard_00
前雷达目标物在X轴上的相对加速度的标准差_00
Standard Deviation Of Relative Acceleration X";
CM_ SG_ 962 FRM_3_ObjRelAccelYStd_00 "Front Radar Moudle_X_Object Relative  Acceleration Y Standard_00
前雷达目标物相对加速度在Y轴上的标准差_00
Standard Deviation Of Relative Acceleration Y";
CM_ SG_ 962 FRM_3_ObjExistProb_00 "Front Radar Moudle_X_Object Exist Probability_00
前雷达目标物存在的可能性_00
The Probability Of An Object To Exist In Reality";
CM_ SG_ 962 FRM_3_ObjType_00 "Front Radar Moudle_X_Object Type_00
前雷达目标物的分类_00
Class Of Object Type
Note: Type of static object shall always be 0x0: unknown";
CM_ SG_ 962 FRM_3_ObjTypeConf_00 "Front Radar Moudle_X_Object Type Confidence_00
前雷达目标物分类的置信度_00
The Class Confidence Of Object Type";
CM_ SG_ 962 FRM_3_ObjTrackSts_00 "Front Radar Moudle_X_Object Track Status_00
前雷达目标物的跟踪状态_00
Signal To Indicate The Object Track Status";
CM_ SG_ 962 FRM_3_ObjMotionSts_00 "Front Radar Moudle_X_Object Motion Status_00
前雷达目标物的运动状态_00
Signal To Indicate The Object Whether Moving or Stopped or Static";
CM_ SG_ 962 FRM_3_ObjMotionDirection_00 "Front Radar Moudle_X_Object Motion Direction_00
前雷达目标物的运动方向_00
Signal To Indicate The Object Moving Direction.
Note: Moving direction of static object or stopped object shall always be 0x0: Unknown";
CM_ SG_ 962 FRM_3_ObjCenterDistX_00 "Front Radar Moudle_X_Object Center Distance X_00
前雷达目标物中心点在X轴方向的距离_00
Center Position Of Target Vehicle In X Direction
The rear axle center coordinate system is used";
CM_ SG_ 962 FRM_3_ObjCenterDistY_00 "Front Radar Moudle_X_Object Center Distance Y_00
前雷达目标物中心点在Y轴方向的距离_00
Center Position Of Target Vehicle In Y Direction
The rear axle center coordinate system is used";
CM_ SG_ 962 FRM_3_ObjLength_00 "Front Radar Moudle_X_Object Length_00
前雷达目标物的长度_00
Length Of Target
Note: Length of static object shall always be 0";
CM_ SG_ 962 FRM_3_ObjWidth_00 "Front Radar Moudle_X_Object Width_00
前雷达目标物的宽度_00
Width Of Target
Note: Width of static object shall always be 0";
CM_ SG_ 962 FRM_3_ObjElevnSts_00 "Front Radar Moudle_X_Object Elevation Status_00
前雷达目标物的高度状态_00
The Elevation Status Of An Object
Note: Elevation Status of moving object or stopped object shall always be 0x2: Obstacle";
CM_ SG_ 962 FRM_3_ObjElevnStsConf_00 "Front Radar Moudle_X_Object Elevation Status Confidence_00
前雷达目标物的高度状态的置信度_00
The Confidence Of An Object Elevation Status
Note: Elevation Status Confidence of moving object or stopped object shall always be 100%";
CM_ SG_ 962 FRM_3_ObjHeading_00 "Front Radar Moudle_X_Object Heading_00
前雷达目标物朝向_00
Heading of object 
Note: A rotation vector with anticlock-rotating as positive +π shall be used instead of -π when obect vertically backward
Note: Heading of static object shall always be 0";
CM_ SG_ 962 FRM_3_ObjID_01 "Front Radar Moudle_X_Object ID_01
前雷达目标物身份标识码_01
ID Is An Identifier Number That Allows For Tracking Of Persistent Objects Over Time
Note:A value of 0 indicates 'no object'";
CM_ SG_ 962 FRM_3_ObjClosestDistX_01 "Front Radar Moudle_X_Object Closest Distance X_01
前雷达目标物最近点在X轴上的距离_01
Closest Position Of Target Vehicle In X Direction
The rear axle center coordinate system is used";
CM_ SG_ 962 FRM_3_ObjClosestDistY_01 "Front Radar Moudle_X_Object Closest Distance Y_01
前雷达距目标物最近点在Y轴上的距离_01
Closest Position Of Target Vehicle In Y Direction
The rear axle center coordinate system is used";
CM_ SG_ 962 FRM_3_ObjRelVelX_01 "Front Radar Moudle_X_Object Relative Velocity X_01
前雷达目标物在X轴上的相对速度_01
Relative Target Object Velocity In X Direction";
CM_ SG_ 962 FRM_3_ObjRelVelY_01 "Front Radar Moudle_X_Object Relative Velocity Y_01
前雷达目标物在Y轴上的相对速度_01
Relative Target Object Velocity In Y Direction";
CM_ SG_ 962 FRM_3_ObjAccelX_01 "Front Radar Moudle_X_Object Acceleration X_01
前雷达目标物在X轴上的加速度_01
Relative Target Object Acceleration In X Direction";
CM_ SG_ 962 FRM_3_ObjAccelY_01 "Front Radar Moudle_X_Object Acceleration Y_01
前雷达目标物在Y轴上的加速度_01
Relative Target Object Acceleration In Y Direction";
CM_ SG_ 962 FRM_3_ObjClosestDistXStd_01 "Front Radar Moudle_X_Object Closest Distance X Standard_01
前雷达目标物最近点在X轴上的距离的标准差_01
Standard Deviation Of Closest Position Of Target Vehicle in X Direction";
CM_ SG_ 962 FRM_3_ObjClosestDistYStd_01 "Front Radar Moudle_X_Object Closest Distance Y Standard_01
前雷达目标物最近点在Y轴上的距离的标准差_01
Standard Deviation Of Closest Position Of Target Vehicle in Y Direction";
CM_ SG_ 962 FRM_3_ObjRelVelXStd_01 "Front Radar Moudle_X_Object Relative Velocity X Standard_01
前雷达目标物在X轴上的相对速度的标准差_01
Standard Deviation Of Relative Velocity X";
CM_ SG_ 962 FRM_3_ObjRelVelYStd_01 "Front Radar Moudle_X_Object Relative Velocity Y Standard_01
前雷达目标物在Y轴上的相对速度的标准差_01
Standard Deviation Of Relative Velocity Y";
CM_ SG_ 962 FRM_3_ObjRelAccelXStd_01 "Front Radar Moudle_X_Object Relative  Acceleration X Standard_01
前雷达目标物在X轴上的相对加速度的标准差_01
Standard Deviation Of Relative Acceleration X";
CM_ SG_ 962 FRM_3_ObjRelAccelYStd_01 "Front Radar Moudle_X_Object Relative  Acceleration Y Standard_01
前雷达目标物相对加速度在Y轴上的标准差_01
Standard Deviation Of Relative Acceleration Y";
CM_ SG_ 962 FRM_3_ObjExistProb_01 "Front Radar Moudle_X_Object Exist Probability_01
前雷达目标物存在的可能性_01
The Probability Of An Object To Exist In Reality";
CM_ SG_ 962 FRM_3_ObjType_01 "Front Radar Moudle_X_Object Type_01
前雷达目标物的分类_01
Class Of Object Type
Note: Type of static object shall always be 0x0: unknown";
CM_ SG_ 962 FRM_3_ObjTypeConf_01 "Front Radar Moudle_X_Object Type Confidence_01
前雷达目标物分类的置信度_01
The Class Confidence Of Object Type";
CM_ SG_ 962 FRM_3_ObjTrackSts_01 "Front Radar Moudle_X_Object Track Status_01
前雷达目标物的跟踪状态_01
Signal To Indicate The Object Track Status";
CM_ SG_ 962 FRM_3_ObjMotionSts_01 "Front Radar Moudle_X_Object Motion Status_01
前雷达目标物的运动状态_01
Signal To Indicate The Object Whether Moving or Stopped or Static";
CM_ SG_ 962 FRM_3_ObjMotionDirection_01 "Front Radar Moudle_X_Object Motion Direction_01
前雷达目标物的运动方向_01
Signal To Indicate The Object Moving Direction.
Note: Moving direction of static object or stopped object shall always be 0x0: Unknown";
CM_ SG_ 962 FRM_3_ObjCenterDistX_01 "Front Radar Moudle_X_Object Center Distance X_01
前雷达目标物中心点在X轴方向的距离_01
Center Position Of Target Vehicle In X Direction
The rear axle center coordinate system is used";
CM_ SG_ 962 FRM_3_ObjCenterDistY_01 "Front Radar Moudle_X_Object Center Distance Y_01
前雷达目标物中心点在Y轴方向的距离_01
Center Position Of Target Vehicle In Y Direction
The rear axle center coordinate system is used";
CM_ SG_ 962 FRM_3_ObjLength_01 "Front Radar Moudle_X_Object Length_01
前雷达目标物的长度_01
Length Of Target
Note: Length of static object shall always be 0";
CM_ SG_ 962 FRM_3_ObjWidth_01 "Front Radar Moudle_X_Object Width_01
前雷达目标物的宽度_01
Width Of Target
Note: Width of static object shall always be 0";
CM_ SG_ 962 FRM_3_ObjElevnSts_01 "Front Radar Moudle_X_Object Elevation Status_01
前雷达目标物的高度状态_01
The Elevation Status Of An Object
Note: Elevation Status of moving object or stopped object shall always be 0x2: Obstacle";
CM_ SG_ 962 FRM_3_ObjElevnStsConf_01 "Front Radar Moudle_X_Object Elevation Status Confidence_01
前雷达目标物的高度状态的置信度_01
The Confidence Of An Object Elevation Status
Note: Elevation Status Confidence of moving object or stopped object shall always be 100%";
CM_ SG_ 962 FRM_3_ObjHeading_01 "Front Radar Moudle_X_Object Heading_01
前雷达目标物朝向_01
Heading of object 
Note: A rotation vector with anticlock-rotating as positive +π shall be used instead of -π when obect vertically backward
Note: Heading of static object shall always be 0";
CM_ SG_ 963 FRM_4_CRC "Profile5:E2E CRC16 (polynomial:0x1021)       
DataID:Use CANID,other bits Fill with 0";
CM_ SG_ 963 FRM_4_RollgCntr "Profile5:E2E Rolling message counter";
CM_ SG_ 963 FRM_4_ObjBlockCounter "Front Radar Moudle_X_Object Block Counter
前雷达目标物块计数值";
CM_ SG_ 963 FRM_4_ObjID_02 "Front Radar Moudle_X_Object ID_00
前雷达目标物身份标识码_00
ID Is An Identifier Number That Allows For Tracking Of Persistent Objects Over Time
Note:A value of 0 indicates 'no object'";
CM_ SG_ 963 FRM_4_ObjClosestDistX_02 "Front Radar Moudle_X_Object Closest Distance X_00
前雷达目标物最近点在X轴上的距离_00
Closest Position Of Target Vehicle In X Direction
The rear axle center coordinate system is used";
CM_ SG_ 963 FRM_4_ObjClosestDistY_02 "Front Radar Moudle_X_Object Closest Distance Y_00
前雷达距目标物最近点在Y轴上的距离_00
Closest Position Of Target Vehicle In Y Direction
The rear axle center coordinate system is used";
CM_ SG_ 963 FRM_4_ObjRelVelX_02 "Front Radar Moudle_X_Object Relative Velocity X_00
前雷达目标物在X轴上的相对速度_00
Relative Target Object Velocity In X Direction";
CM_ SG_ 963 FRM_4_ObjRelVelY_02 "Front Radar Moudle_X_Object Relative Velocity Y_00
前雷达目标物在Y轴上的相对速度_00
Relative Target Object Velocity In Y Direction";
CM_ SG_ 963 FRM_4_ObjAccelX_02 "Front Radar Moudle_X_Object Acceleration X_00
前雷达目标物在X轴上的加速度_00
Relative Target Object Acceleration In X Direction";
CM_ SG_ 963 FRM_4_ObjAccelY_02 "Front Radar Moudle_X_Object Acceleration Y_00
前雷达目标物在Y轴上的加速度_00
Relative Target Object Acceleration In Y Direction";
CM_ SG_ 963 FRM_4_ObjClosestDistXStd_02 "Front Radar Moudle_X_Object Closest Distance X Standard_00
前雷达目标物最近点在X轴上的距离的标准差_00
Standard Deviation Of Closest Position Of Target Vehicle in X Direction";
CM_ SG_ 963 FRM_4_ObjClosestDistYStd_02 "Front Radar Moudle_X_Object Closest Distance Y Standard_00
前雷达目标物最近点在Y轴上的距离的标准差_00
Standard Deviation Of Closest Position Of Target Vehicle in Y Direction";
CM_ SG_ 963 FRM_4_ObjRelVelXStd_02 "Front Radar Moudle_X_Object Relative Velocity X Standard_00
前雷达目标物在X轴上的相对速度的标准差_00
Standard Deviation Of Relative Velocity X";
CM_ SG_ 963 FRM_4_ObjRelVelYStd_02 "Front Radar Moudle_X_Object Relative Velocity Y Standard_00
前雷达目标物在Y轴上的相对速度的标准差_00
Standard Deviation Of Relative Velocity Y";
CM_ SG_ 963 FRM_4_ObjRelAccelXStd_02 "Front Radar Moudle_X_Object Relative  Acceleration X Standard_00
前雷达目标物在X轴上的相对加速度的标准差_00
Standard Deviation Of Relative Acceleration X";
CM_ SG_ 963 FRM_4_ObjRelAccelYStd_02 "Front Radar Moudle_X_Object Relative  Acceleration Y Standard_00
前雷达目标物相对加速度在Y轴上的标准差_00
Standard Deviation Of Relative Acceleration Y";
CM_ SG_ 963 FRM_4_ObjExistProb_02 "Front Radar Moudle_X_Object Exist Probability_00
前雷达目标物存在的可能性_00
The Probability Of An Object To Exist In Reality";
CM_ SG_ 963 FRM_4_ObjType_02 "Front Radar Moudle_X_Object Type_00
前雷达目标物的分类_00
Class Of Object Type
Note: Type of static object shall always be 0x0: unknown";
CM_ SG_ 963 FRM_4_ObjTypeConf_02 "Front Radar Moudle_X_Object Type Confidence_00
前雷达目标物分类的置信度_00
The Class Confidence Of Object Type";
CM_ SG_ 963 FRM_4_ObjTrackSts_02 "Front Radar Moudle_X_Object Track Status_00
前雷达目标物的跟踪状态_00
Signal To Indicate The Object Track Status";
CM_ SG_ 963 FRM_4_ObjMotionSts_02 "Front Radar Moudle_X_Object Motion Status_00
前雷达目标物的运动状态_00
Signal To Indicate The Object Whether Moving or Stopped or Static";
CM_ SG_ 963 FRM_4_ObjMotionDirection_02 "Front Radar Moudle_X_Object Motion Direction_00
前雷达目标物的运动方向_00
Signal To Indicate The Object Moving Direction.
Note: Moving direction of static object or stopped object shall always be 0x0: Unknown";
CM_ SG_ 963 FRM_4_ObjCenterDistX_02 "Front Radar Moudle_X_Object Center Distance X_00
前雷达目标物中心点在X轴方向的距离_00
Center Position Of Target Vehicle In X Direction
The rear axle center coordinate system is used";
CM_ SG_ 963 FRM_4_ObjCenterDistY_02 "Front Radar Moudle_X_Object Center Distance Y_00
前雷达目标物中心点在Y轴方向的距离_00
Center Position Of Target Vehicle In Y Direction
The rear axle center coordinate system is used";
CM_ SG_ 963 FRM_4_ObjLength_02 "Front Radar Moudle_X_Object Length_00
前雷达目标物的长度_00
Length Of Target
Note: Length of static object shall always be 0";
CM_ SG_ 963 FRM_4_ObjWidth_02 "Front Radar Moudle_X_Object Width_00
前雷达目标物的宽度_00
Width Of Target
Note: Width of static object shall always be 0";
CM_ SG_ 963 FRM_4_ObjElevnSts_02 "Front Radar Moudle_X_Object Elevation Status_00
前雷达目标物的高度状态_00
The Elevation Status Of An Object
Note: Elevation Status of moving object or stopped object shall always be 0x2: Obstacle";
CM_ SG_ 963 FRM_4_ObjElevnStsConf_02 "Front Radar Moudle_X_Object Elevation Status Confidence_00
前雷达目标物的高度状态的置信度_00
The Confidence Of An Object Elevation Status
Note: Elevation Status Confidence of moving object or stopped object shall always be 100%";
CM_ SG_ 963 FRM_4_ObjHeading_02 "Front Radar Moudle_X_Object Heading_00
前雷达目标物朝向_00
Heading of object 
Note: A rotation vector with anticlock-rotating as positive +π shall be used instead of -π when obect vertically backward
Note: Heading of static object shall always be 0";
CM_ SG_ 963 FRM_4_ObjID_03 "Front Radar Moudle_X_Object ID_01
前雷达目标物身份标识码_01
ID Is An Identifier Number That Allows For Tracking Of Persistent Objects Over Time
Note:A value of 0 indicates 'no object'";
CM_ SG_ 963 FRM_4_ObjClosestDistX_03 "Front Radar Moudle_X_Object Closest Distance X_01
前雷达目标物最近点在X轴上的距离_01
Closest Position Of Target Vehicle In X Direction
The rear axle center coordinate system is used";
CM_ SG_ 963 FRM_4_ObjClosestDistY_03 "Front Radar Moudle_X_Object Closest Distance Y_01
前雷达距目标物最近点在Y轴上的距离_01
Closest Position Of Target Vehicle In Y Direction
The rear axle center coordinate system is used";
CM_ SG_ 963 FRM_4_ObjRelVelX_03 "Front Radar Moudle_X_Object Relative Velocity X_01
前雷达目标物在X轴上的相对速度_01
Relative Target Object Velocity In X Direction";
CM_ SG_ 963 FRM_4_ObjRelVelY_03 "Front Radar Moudle_X_Object Relative Velocity Y_01
前雷达目标物在Y轴上的相对速度_01
Relative Target Object Velocity In Y Direction";
CM_ SG_ 963 FRM_4_ObjAccelX_03 "Front Radar Moudle_X_Object Acceleration X_01
前雷达目标物在X轴上的加速度_01
Relative Target Object Acceleration In X Direction";
CM_ SG_ 963 FRM_4_ObjAccelY_03 "Front Radar Moudle_X_Object Acceleration Y_01
前雷达目标物在Y轴上的加速度_01
Relative Target Object Acceleration In Y Direction";
CM_ SG_ 963 FRM_4_ObjClosestDistXStd_03 "Front Radar Moudle_X_Object Closest Distance X Standard_01
前雷达目标物最近点在X轴上的距离的标准差_01
Standard Deviation Of Closest Position Of Target Vehicle in X Direction";
CM_ SG_ 963 FRM_4_ObjClosestDistYStd_03 "Front Radar Moudle_X_Object Closest Distance Y Standard_01
前雷达目标物最近点在Y轴上的距离的标准差_01
Standard Deviation Of Closest Position Of Target Vehicle in Y Direction";
CM_ SG_ 963 FRM_4_ObjRelVelXStd_03 "Front Radar Moudle_X_Object Relative Velocity X Standard_01
前雷达目标物在X轴上的相对速度的标准差_01
Standard Deviation Of Relative Velocity X";
CM_ SG_ 963 FRM_4_ObjRelVelYStd_03 "Front Radar Moudle_X_Object Relative Velocity Y Standard_01
前雷达目标物在Y轴上的相对速度的标准差_01
Standard Deviation Of Relative Velocity Y";
CM_ SG_ 963 FRM_4_ObjRelAccelXStd_03 "Front Radar Moudle_X_Object Relative  Acceleration X Standard_01
前雷达目标物在X轴上的相对加速度的标准差_01
Standard Deviation Of Relative Acceleration X";
CM_ SG_ 963 FRM_4_ObjRelAccelYStd_03 "Front Radar Moudle_X_Object Relative  Acceleration Y Standard_01
前雷达目标物相对加速度在Y轴上的标准差_01
Standard Deviation Of Relative Acceleration Y";
CM_ SG_ 963 FRM_4_ObjExistProb_03 "Front Radar Moudle_X_Object Exist Probability_01
前雷达目标物存在的可能性_01
The Probability Of An Object To Exist In Reality";
CM_ SG_ 963 FRM_4_ObjType_03 "Front Radar Moudle_X_Object Type_01
前雷达目标物的分类_01
Class Of Object Type
Note: Type of static object shall always be 0x0: unknown";
CM_ SG_ 963 FRM_4_ObjTypeConf_03 "Front Radar Moudle_X_Object Type Confidence_01
前雷达目标物分类的置信度_01
The Class Confidence Of Object Type";
CM_ SG_ 963 FRM_4_ObjTrackSts_03 "Front Radar Moudle_X_Object Track Status_01
前雷达目标物的跟踪状态_01
Signal To Indicate The Object Track Status";
CM_ SG_ 963 FRM_4_ObjMotionSts_03 "Front Radar Moudle_X_Object Motion Status_01
前雷达目标物的运动状态_01
Signal To Indicate The Object Whether Moving or Stopped or Static";
CM_ SG_ 963 FRM_4_ObjMotionDirection_03 "Front Radar Moudle_X_Object Motion Direction_01
前雷达目标物的运动方向_01
Signal To Indicate The Object Moving Direction.
Note: Moving direction of static object or stopped object shall always be 0x0: Unknown";
CM_ SG_ 963 FRM_4_ObjCenterDistX_03 "Front Radar Moudle_X_Object Center Distance X_01
前雷达目标物中心点在X轴方向的距离_01
Center Position Of Target Vehicle In X Direction
The rear axle center coordinate system is used";
CM_ SG_ 963 FRM_4_ObjCenterDistY_03 "Front Radar Moudle_X_Object Center Distance Y_01
前雷达目标物中心点在Y轴方向的距离_01
Center Position Of Target Vehicle In Y Direction
The rear axle center coordinate system is used";
CM_ SG_ 963 FRM_4_ObjLength_03 "Front Radar Moudle_X_Object Length_01
前雷达目标物的长度_01
Length Of Target
Note: Length of static object shall always be 0";
CM_ SG_ 963 FRM_4_ObjWidth_03 "Front Radar Moudle_X_Object Width_01
前雷达目标物的宽度_01
Width Of Target
Note: Width of static object shall always be 0";
CM_ SG_ 963 FRM_4_ObjElevnSts_03 "Front Radar Moudle_X_Object Elevation Status_01
前雷达目标物的高度状态_01
The Elevation Status Of An Object
Note: Elevation Status of moving object or stopped object shall always be 0x2: Obstacle";
CM_ SG_ 963 FRM_4_ObjElevnStsConf_03 "Front Radar Moudle_X_Object Elevation Status Confidence_01
前雷达目标物的高度状态的置信度_01
The Confidence Of An Object Elevation Status
Note: Elevation Status Confidence of moving object or stopped object shall always be 100%";
CM_ SG_ 963 FRM_4_ObjHeading_03 "Front Radar Moudle_X_Object Heading_01
前雷达目标物朝向_01
Heading of object 
Note: A rotation vector with anticlock-rotating as positive +π shall be used instead of -π when obect vertically backward
Note: Heading of static object shall always be 0";
CM_ SG_ 964 FRM_5_CRC "Profile5:E2E CRC16 (polynomial:0x1021)       
DataID:Use CANID,other bits Fill with 0";
CM_ SG_ 964 FRM_5_RollgCntr "Profile5:E2E Rolling message counter";
CM_ SG_ 964 FRM_5_ObjBlockCounter "Front Radar Moudle_X_Object Block Counter
前雷达目标物块计数值";
CM_ SG_ 964 FRM_5_ObjID_04 "Front Radar Moudle_X_Object ID_00
前雷达目标物身份标识码_00
ID Is An Identifier Number That Allows For Tracking Of Persistent Objects Over Time
Note:A value of 0 indicates 'no object'";
CM_ SG_ 964 FRM_5_ObjClosestDistX_04 "Front Radar Moudle_X_Object Closest Distance X_00
前雷达目标物最近点在X轴上的距离_00
Closest Position Of Target Vehicle In X Direction
The rear axle center coordinate system is used";
CM_ SG_ 964 FRM_5_ObjClosestDistY_04 "Front Radar Moudle_X_Object Closest Distance Y_00
前雷达距目标物最近点在Y轴上的距离_00
Closest Position Of Target Vehicle In Y Direction
The rear axle center coordinate system is used";
CM_ SG_ 964 FRM_5_ObjRelVelX_04 "Front Radar Moudle_X_Object Relative Velocity X_00
前雷达目标物在X轴上的相对速度_00
Relative Target Object Velocity In X Direction";
CM_ SG_ 964 FRM_5_ObjRelVelY_04 "Front Radar Moudle_X_Object Relative Velocity Y_00
前雷达目标物在Y轴上的相对速度_00
Relative Target Object Velocity In Y Direction";
CM_ SG_ 964 FRM_5_ObjAccelX_04 "Front Radar Moudle_X_Object Acceleration X_00
前雷达目标物在X轴上的加速度_00
Relative Target Object Acceleration In X Direction";
CM_ SG_ 964 FRM_5_ObjAccelY_04 "Front Radar Moudle_X_Object Acceleration Y_00
前雷达目标物在Y轴上的加速度_00
Relative Target Object Acceleration In Y Direction";
CM_ SG_ 964 FRM_5_ObjClosestDistXStd_04 "Front Radar Moudle_X_Object Closest Distance X Standard_00
前雷达目标物最近点在X轴上的距离的标准差_00
Standard Deviation Of Closest Position Of Target Vehicle in X Direction";
CM_ SG_ 964 FRM_5_ObjClosestDistYStd_04 "Front Radar Moudle_X_Object Closest Distance Y Standard_00
前雷达目标物最近点在Y轴上的距离的标准差_00
Standard Deviation Of Closest Position Of Target Vehicle in Y Direction";
CM_ SG_ 964 FRM_5_ObjRelVelXStd_04 "Front Radar Moudle_X_Object Relative Velocity X Standard_00
前雷达目标物在X轴上的相对速度的标准差_00
Standard Deviation Of Relative Velocity X";
CM_ SG_ 964 FRM_5_ObjRelVelYStd_04 "Front Radar Moudle_X_Object Relative Velocity Y Standard_00
前雷达目标物在Y轴上的相对速度的标准差_00
Standard Deviation Of Relative Velocity Y";
CM_ SG_ 964 FRM_5_ObjRelAccelXStd_04 "Front Radar Moudle_X_Object Relative  Acceleration X Standard_00
前雷达目标物在X轴上的相对加速度的标准差_00
Standard Deviation Of Relative Acceleration X";
CM_ SG_ 964 FRM_5_ObjRelAccelYStd_04 "Front Radar Moudle_X_Object Relative  Acceleration Y Standard_00
前雷达目标物相对加速度在Y轴上的标准差_00
Standard Deviation Of Relative Acceleration Y";
CM_ SG_ 964 FRM_5_ObjExistProb_04 "Front Radar Moudle_X_Object Exist Probability_00
前雷达目标物存在的可能性_00
The Probability Of An Object To Exist In Reality";
CM_ SG_ 964 FRM_5_ObjType_04 "Front Radar Moudle_X_Object Type_00
前雷达目标物的分类_00
Class Of Object Type
Note: Type of static object shall always be 0x0: unknown";
CM_ SG_ 964 FRM_5_ObjTypeConf_04 "Front Radar Moudle_X_Object Type Confidence_00
前雷达目标物分类的置信度_00
The Class Confidence Of Object Type";
CM_ SG_ 964 FRM_5_ObjTrackSts_04 "Front Radar Moudle_X_Object Track Status_00
前雷达目标物的跟踪状态_00
Signal To Indicate The Object Track Status";
CM_ SG_ 964 FRM_5_ObjMotionSts_04 "Front Radar Moudle_X_Object Motion Status_00
前雷达目标物的运动状态_00
Signal To Indicate The Object Whether Moving or Stopped or Static";
CM_ SG_ 964 FRM_5_ObjMotionDirection_04 "Front Radar Moudle_X_Object Motion Direction_00
前雷达目标物的运动方向_00
Signal To Indicate The Object Moving Direction.
Note: Moving direction of static object or stopped object shall always be 0x0: Unknown";
CM_ SG_ 964 FRM_5_ObjCenterDistX_04 "Front Radar Moudle_X_Object Center Distance X_00
前雷达目标物中心点在X轴方向的距离_00
Center Position Of Target Vehicle In X Direction
The rear axle center coordinate system is used";
CM_ SG_ 964 FRM_5_ObjCenterDistY_04 "Front Radar Moudle_X_Object Center Distance Y_00
前雷达目标物中心点在Y轴方向的距离_00
Center Position Of Target Vehicle In Y Direction
The rear axle center coordinate system is used";
CM_ SG_ 964 FRM_5_ObjLength_04 "Front Radar Moudle_X_Object Length_00
前雷达目标物的长度_00
Length Of Target
Note: Length of static object shall always be 0";
CM_ SG_ 964 FRM_5_ObjWidth_04 "Front Radar Moudle_X_Object Width_00
前雷达目标物的宽度_00
Width Of Target
Note: Width of static object shall always be 0";
CM_ SG_ 964 FRM_5_ObjElevnSts_04 "Front Radar Moudle_X_Object Elevation Status_00
前雷达目标物的高度状态_00
The Elevation Status Of An Object
Note: Elevation Status of moving object or stopped object shall always be 0x2: Obstacle";
CM_ SG_ 964 FRM_5_ObjElevnStsConf_04 "Front Radar Moudle_X_Object Elevation Status Confidence_00
前雷达目标物的高度状态的置信度_00
The Confidence Of An Object Elevation Status
Note: Elevation Status Confidence of moving object or stopped object shall always be 100%";
CM_ SG_ 964 FRM_5_ObjHeading_04 "Front Radar Moudle_X_Object Heading_00
前雷达目标物朝向_00
Heading of object 
Note: A rotation vector with anticlock-rotating as positive +π shall be used instead of -π when obect vertically backward
Note: Heading of static object shall always be 0";
CM_ SG_ 964 FRM_5_ObjID_05 "Front Radar Moudle_X_Object ID_01
前雷达目标物身份标识码_01
ID Is An Identifier Number That Allows For Tracking Of Persistent Objects Over Time
Note:A value of 0 indicates 'no object'";
CM_ SG_ 964 FRM_5_ObjClosestDistX_05 "Front Radar Moudle_X_Object Closest Distance X_01
前雷达目标物最近点在X轴上的距离_01
Closest Position Of Target Vehicle In X Direction
The rear axle center coordinate system is used";
CM_ SG_ 964 FRM_5_ObjClosestDistY_05 "Front Radar Moudle_X_Object Closest Distance Y_01
前雷达距目标物最近点在Y轴上的距离_01
Closest Position Of Target Vehicle In Y Direction
The rear axle center coordinate system is used";
CM_ SG_ 964 FRM_5_ObjRelVelX_05 "Front Radar Moudle_X_Object Relative Velocity X_01
前雷达目标物在X轴上的相对速度_01
Relative Target Object Velocity In X Direction";
CM_ SG_ 964 FRM_5_ObjRelVelY_05 "Front Radar Moudle_X_Object Relative Velocity Y_01
前雷达目标物在Y轴上的相对速度_01
Relative Target Object Velocity In Y Direction";
CM_ SG_ 964 FRM_5_ObjAccelX_05 "Front Radar Moudle_X_Object Acceleration X_01
前雷达目标物在X轴上的加速度_01
Relative Target Object Acceleration In X Direction";
CM_ SG_ 964 FRM_5_ObjAccelY_05 "Front Radar Moudle_X_Object Acceleration Y_01
前雷达目标物在Y轴上的加速度_01
Relative Target Object Acceleration In Y Direction";
CM_ SG_ 964 FRM_5_ObjClosestDistXStd_05 "Front Radar Moudle_X_Object Closest Distance X Standard_01
前雷达目标物最近点在X轴上的距离的标准差_01
Standard Deviation Of Closest Position Of Target Vehicle in X Direction";
CM_ SG_ 964 FRM_5_ObjClosestDistYStd_05 "Front Radar Moudle_X_Object Closest Distance Y Standard_01
前雷达目标物最近点在Y轴上的距离的标准差_01
Standard Deviation Of Closest Position Of Target Vehicle in Y Direction";
CM_ SG_ 964 FRM_5_ObjRelVelXStd_05 "Front Radar Moudle_X_Object Relative Velocity X Standard_01
前雷达目标物在X轴上的相对速度的标准差_01
Standard Deviation Of Relative Velocity X";
CM_ SG_ 964 FRM_5_ObjRelVelYStd_05 "Front Radar Moudle_X_Object Relative Velocity Y Standard_01
前雷达目标物在Y轴上的相对速度的标准差_01
Standard Deviation Of Relative Velocity Y";
CM_ SG_ 964 FRM_5_ObjRelAccelXStd_05 "Front Radar Moudle_X_Object Relative  Acceleration X Standard_01
前雷达目标物在X轴上的相对加速度的标准差_01
Standard Deviation Of Relative Acceleration X";
CM_ SG_ 964 FRM_5_ObjRelAccelYStd_05 "Front Radar Moudle_X_Object Relative  Acceleration Y Standard_01
前雷达目标物相对加速度在Y轴上的标准差_01
Standard Deviation Of Relative Acceleration Y";
CM_ SG_ 964 FRM_5_ObjExistProb_05 "Front Radar Moudle_X_Object Exist Probability_01
前雷达目标物存在的可能性_01
The Probability Of An Object To Exist In Reality";
CM_ SG_ 964 FRM_5_ObjType_05 "Front Radar Moudle_X_Object Type_01
前雷达目标物的分类_01
Class Of Object Type
Note: Type of static object shall always be 0x0: unknown";
CM_ SG_ 964 FRM_5_ObjTypeConf_05 "Front Radar Moudle_X_Object Type Confidence_01
前雷达目标物分类的置信度_01
The Class Confidence Of Object Type";
CM_ SG_ 964 FRM_5_ObjTrackSts_05 "Front Radar Moudle_X_Object Track Status_01
前雷达目标物的跟踪状态_01
Signal To Indicate The Object Track Status";
CM_ SG_ 964 FRM_5_ObjMotionSts_05 "Front Radar Moudle_X_Object Motion Status_01
前雷达目标物的运动状态_01
Signal To Indicate The Object Whether Moving or Stopped or Static";
CM_ SG_ 964 FRM_5_ObjMotionDirection_05 "Front Radar Moudle_X_Object Motion Direction_01
前雷达目标物的运动方向_01
Signal To Indicate The Object Moving Direction.
Note: Moving direction of static object or stopped object shall always be 0x0: Unknown";
CM_ SG_ 964 FRM_5_ObjCenterDistX_05 "Front Radar Moudle_X_Object Center Distance X_01
前雷达目标物中心点在X轴方向的距离_01
Center Position Of Target Vehicle In X Direction
The rear axle center coordinate system is used";
CM_ SG_ 964 FRM_5_ObjCenterDistY_05 "Front Radar Moudle_X_Object Center Distance Y_01
前雷达目标物中心点在Y轴方向的距离_01
Center Position Of Target Vehicle In Y Direction
The rear axle center coordinate system is used";
CM_ SG_ 964 FRM_5_ObjLength_05 "Front Radar Moudle_X_Object Length_01
前雷达目标物的长度_01
Length Of Target
Note: Length of static object shall always be 0";
CM_ SG_ 964 FRM_5_ObjWidth_05 "Front Radar Moudle_X_Object Width_01
前雷达目标物的宽度_01
Width Of Target
Note: Width of static object shall always be 0";
CM_ SG_ 964 FRM_5_ObjElevnSts_05 "Front Radar Moudle_X_Object Elevation Status_01
前雷达目标物的高度状态_01
The Elevation Status Of An Object
Note: Elevation Status of moving object or stopped object shall always be 0x2: Obstacle";
CM_ SG_ 964 FRM_5_ObjElevnStsConf_05 "Front Radar Moudle_X_Object Elevation Status Confidence_01
前雷达目标物的高度状态的置信度_01
The Confidence Of An Object Elevation Status
Note: Elevation Status Confidence of moving object or stopped object shall always be 100%";
CM_ SG_ 964 FRM_5_ObjHeading_05 "Front Radar Moudle_X_Object Heading_01
前雷达目标物朝向_01
Heading of object 
Note: A rotation vector with anticlock-rotating as positive +π shall be used instead of -π when obect vertically backward
Note: Heading of static object shall always be 0";
CM_ SG_ 965 FRM_6_CRC "Profile5:E2E CRC16 (polynomial:0x1021)       
DataID:Use CANID,other bits Fill with 0";
CM_ SG_ 965 FRM_6_RollgCntr "Profile5:E2E Rolling message counter";
CM_ SG_ 965 FRM_6_ObjBlockCounter "Front Radar Moudle_X_Object Block Counter
前雷达目标物块计数值";
CM_ SG_ 965 FRM_6_ObjID_06 "Front Radar Moudle_X_Object ID_00
前雷达目标物身份标识码_00
ID Is An Identifier Number That Allows For Tracking Of Persistent Objects Over Time
Note:A value of 0 indicates 'no object'";
CM_ SG_ 965 FRM_6_ObjClosestDistX_06 "Front Radar Moudle_X_Object Closest Distance X_00
前雷达目标物最近点在X轴上的距离_00
Closest Position Of Target Vehicle In X Direction
The rear axle center coordinate system is used";
CM_ SG_ 965 FRM_6_ObjClosestDistY_06 "Front Radar Moudle_X_Object Closest Distance Y_00
前雷达距目标物最近点在Y轴上的距离_00
Closest Position Of Target Vehicle In Y Direction
The rear axle center coordinate system is used";
CM_ SG_ 965 FRM_6_ObjRelVelX_06 "Front Radar Moudle_X_Object Relative Velocity X_00
前雷达目标物在X轴上的相对速度_00
Relative Target Object Velocity In X Direction";
CM_ SG_ 965 FRM_6_ObjRelVelY_06 "Front Radar Moudle_X_Object Relative Velocity Y_00
前雷达目标物在Y轴上的相对速度_00
Relative Target Object Velocity In Y Direction";
CM_ SG_ 965 FRM_6_ObjAccelX_06 "Front Radar Moudle_X_Object Acceleration X_00
前雷达目标物在X轴上的加速度_00
Relative Target Object Acceleration In X Direction";
CM_ SG_ 965 FRM_6_ObjAccelY_06 "Front Radar Moudle_X_Object Acceleration Y_00
前雷达目标物在Y轴上的加速度_00
Relative Target Object Acceleration In Y Direction";
CM_ SG_ 965 FRM_6_ObjClosestDistXStd_06 "Front Radar Moudle_X_Object Closest Distance X Standard_00
前雷达目标物最近点在X轴上的距离的标准差_00
Standard Deviation Of Closest Position Of Target Vehicle in X Direction";
CM_ SG_ 965 FRM_6_ObjClosestDistYStd_06 "Front Radar Moudle_X_Object Closest Distance Y Standard_00
前雷达目标物最近点在Y轴上的距离的标准差_00
Standard Deviation Of Closest Position Of Target Vehicle in Y Direction";
CM_ SG_ 965 FRM_6_ObjRelVelXStd_06 "Front Radar Moudle_X_Object Relative Velocity X Standard_00
前雷达目标物在X轴上的相对速度的标准差_00
Standard Deviation Of Relative Velocity X";
CM_ SG_ 965 FRM_6_ObjRelVelYStd_06 "Front Radar Moudle_X_Object Relative Velocity Y Standard_00
前雷达目标物在Y轴上的相对速度的标准差_00
Standard Deviation Of Relative Velocity Y";
CM_ SG_ 965 FRM_6_ObjRelAccelXStd_06 "Front Radar Moudle_X_Object Relative  Acceleration X Standard_00
前雷达目标物在X轴上的相对加速度的标准差_00
Standard Deviation Of Relative Acceleration X";
CM_ SG_ 965 FRM_6_ObjRelAccelYStd_06 "Front Radar Moudle_X_Object Relative  Acceleration Y Standard_00
前雷达目标物相对加速度在Y轴上的标准差_00
Standard Deviation Of Relative Acceleration Y";
CM_ SG_ 965 FRM_6_ObjExistProb_06 "Front Radar Moudle_X_Object Exist Probability_00
前雷达目标物存在的可能性_00
The Probability Of An Object To Exist In Reality";
CM_ SG_ 965 FRM_6_ObjType_06 "Front Radar Moudle_X_Object Type_00
前雷达目标物的分类_00
Class Of Object Type
Note: Type of static object shall always be 0x0: unknown";
CM_ SG_ 965 FRM_6_ObjTypeConf_06 "Front Radar Moudle_X_Object Type Confidence_00
前雷达目标物分类的置信度_00
The Class Confidence Of Object Type";
CM_ SG_ 965 FRM_6_ObjTrackSts_06 "Front Radar Moudle_X_Object Track Status_00
前雷达目标物的跟踪状态_00
Signal To Indicate The Object Track Status";
CM_ SG_ 965 FRM_6_ObjMotionSts_06 "Front Radar Moudle_X_Object Motion Status_00
前雷达目标物的运动状态_00
Signal To Indicate The Object Whether Moving or Stopped or Static";
CM_ SG_ 965 FRM_6_ObjMotionDirection_06 "Front Radar Moudle_X_Object Motion Direction_00
前雷达目标物的运动方向_00
Signal To Indicate The Object Moving Direction.
Note: Moving direction of static object or stopped object shall always be 0x0: Unknown";
CM_ SG_ 965 FRM_6_ObjCenterDistX_06 "Front Radar Moudle_X_Object Center Distance X_00
前雷达目标物中心点在X轴方向的距离_00
Center Position Of Target Vehicle In X Direction
The rear axle center coordinate system is used";
CM_ SG_ 965 FRM_6_ObjCenterDistY_06 "Front Radar Moudle_X_Object Center Distance Y_00
前雷达目标物中心点在Y轴方向的距离_00
Center Position Of Target Vehicle In Y Direction
The rear axle center coordinate system is used";
CM_ SG_ 965 FRM_6_ObjLength_06 "Front Radar Moudle_X_Object Length_00
前雷达目标物的长度_00
Length Of Target
Note: Length of static object shall always be 0";
CM_ SG_ 965 FRM_6_ObjWidth_06 "Front Radar Moudle_X_Object Width_00
前雷达目标物的宽度_00
Width Of Target
Note: Width of static object shall always be 0";
CM_ SG_ 965 FRM_6_ObjElevnSts_06 "Front Radar Moudle_X_Object Elevation Status_00
前雷达目标物的高度状态_00
The Elevation Status Of An Object
Note: Elevation Status of moving object or stopped object shall always be 0x2: Obstacle";
CM_ SG_ 965 FRM_6_ObjElevnStsConf_06 "Front Radar Moudle_X_Object Elevation Status Confidence_00
前雷达目标物的高度状态的置信度_00
The Confidence Of An Object Elevation Status
Note: Elevation Status Confidence of moving object or stopped object shall always be 100%";
CM_ SG_ 965 FRM_6_ObjHeading_06 "Front Radar Moudle_X_Object Heading_00
前雷达目标物朝向_00
Heading of object 
Note: A rotation vector with anticlock-rotating as positive +π shall be used instead of -π when obect vertically backward
Note: Heading of static object shall always be 0";
CM_ SG_ 965 FRM_6_ObjID_07 "Front Radar Moudle_X_Object ID_01
前雷达目标物身份标识码_01
ID Is An Identifier Number That Allows For Tracking Of Persistent Objects Over Time
Note:A value of 0 indicates 'no object'";
CM_ SG_ 965 FRM_6_ObjClosestDistX_07 "Front Radar Moudle_X_Object Closest Distance X_01
前雷达目标物最近点在X轴上的距离_01
Closest Position Of Target Vehicle In X Direction
The rear axle center coordinate system is used";
CM_ SG_ 965 FRM_6_ObjClosestDistY_07 "Front Radar Moudle_X_Object Closest Distance Y_01
前雷达距目标物最近点在Y轴上的距离_01
Closest Position Of Target Vehicle In Y Direction
The rear axle center coordinate system is used";
CM_ SG_ 965 FRM_6_ObjRelVelX_07 "Front Radar Moudle_X_Object Relative Velocity X_01
前雷达目标物在X轴上的相对速度_01
Relative Target Object Velocity In X Direction";
CM_ SG_ 965 FRM_6_ObjRelVelY_07 "Front Radar Moudle_X_Object Relative Velocity Y_01
前雷达目标物在Y轴上的相对速度_01
Relative Target Object Velocity In Y Direction";
CM_ SG_ 965 FRM_6_ObjAccelX_07 "Front Radar Moudle_X_Object Acceleration X_01
前雷达目标物在X轴上的加速度_01
Relative Target Object Acceleration In X Direction";
CM_ SG_ 965 FRM_6_ObjAccelY_07 "Front Radar Moudle_X_Object Acceleration Y_01
前雷达目标物在Y轴上的加速度_01
Relative Target Object Acceleration In Y Direction";
CM_ SG_ 965 FRM_6_ObjClosestDistXStd_07 "Front Radar Moudle_X_Object Closest Distance X Standard_01
前雷达目标物最近点在X轴上的距离的标准差_01
Standard Deviation Of Closest Position Of Target Vehicle in X Direction";
CM_ SG_ 965 FRM_6_ObjClosestDistYStd_07 "Front Radar Moudle_X_Object Closest Distance Y Standard_01
前雷达目标物最近点在Y轴上的距离的标准差_01
Standard Deviation Of Closest Position Of Target Vehicle in Y Direction";
CM_ SG_ 965 FRM_6_ObjRelVelXStd_07 "Front Radar Moudle_X_Object Relative Velocity X Standard_01
前雷达目标物在X轴上的相对速度的标准差_01
Standard Deviation Of Relative Velocity X";
CM_ SG_ 965 FRM_6_ObjRelVelYStd_07 "Front Radar Moudle_X_Object Relative Velocity Y Standard_01
前雷达目标物在Y轴上的相对速度的标准差_01
Standard Deviation Of Relative Velocity Y";
CM_ SG_ 965 FRM_6_ObjRelAccelXStd_07 "Front Radar Moudle_X_Object Relative  Acceleration X Standard_01
前雷达目标物在X轴上的相对加速度的标准差_01
Standard Deviation Of Relative Acceleration X";
CM_ SG_ 965 FRM_6_ObjRelAccelYStd_07 "Front Radar Moudle_X_Object Relative  Acceleration Y Standard_01
前雷达目标物相对加速度在Y轴上的标准差_01
Standard Deviation Of Relative Acceleration Y";
CM_ SG_ 965 FRM_6_ObjExistProb_07 "Front Radar Moudle_X_Object Exist Probability_01
前雷达目标物存在的可能性_01
The Probability Of An Object To Exist In Reality";
CM_ SG_ 965 FRM_6_ObjType_07 "Front Radar Moudle_X_Object Type_01
前雷达目标物的分类_01
Class Of Object Type
Note: Type of static object shall always be 0x0: unknown";
CM_ SG_ 965 FRM_6_ObjTypeConf_07 "Front Radar Moudle_X_Object Type Confidence_01
前雷达目标物分类的置信度_01
The Class Confidence Of Object Type";
CM_ SG_ 965 FRM_6_ObjTrackSts_07 "Front Radar Moudle_X_Object Track Status_01
前雷达目标物的跟踪状态_01
Signal To Indicate The Object Track Status";
CM_ SG_ 965 FRM_6_ObjMotionSts_07 "Front Radar Moudle_X_Object Motion Status_01
前雷达目标物的运动状态_01
Signal To Indicate The Object Whether Moving or Stopped or Static";
CM_ SG_ 965 FRM_6_ObjMotionDirection_07 "Front Radar Moudle_X_Object Motion Direction_01
前雷达目标物的运动方向_01
Signal To Indicate The Object Moving Direction.
Note: Moving direction of static object or stopped object shall always be 0x0: Unknown";
CM_ SG_ 965 FRM_6_ObjCenterDistX_07 "Front Radar Moudle_X_Object Center Distance X_01
前雷达目标物中心点在X轴方向的距离_01
Center Position Of Target Vehicle In X Direction
The rear axle center coordinate system is used";
CM_ SG_ 965 FRM_6_ObjCenterDistY_07 "Front Radar Moudle_X_Object Center Distance Y_01
前雷达目标物中心点在Y轴方向的距离_01
Center Position Of Target Vehicle In Y Direction
The rear axle center coordinate system is used";
CM_ SG_ 965 FRM_6_ObjLength_07 "Front Radar Moudle_X_Object Length_01
前雷达目标物的长度_01
Length Of Target
Note: Length of static object shall always be 0";
CM_ SG_ 965 FRM_6_ObjWidth_07 "Front Radar Moudle_X_Object Width_01
前雷达目标物的宽度_01
Width Of Target
Note: Width of static object shall always be 0";
CM_ SG_ 965 FRM_6_ObjElevnSts_07 "Front Radar Moudle_X_Object Elevation Status_01
前雷达目标物的高度状态_01
The Elevation Status Of An Object
Note: Elevation Status of moving object or stopped object shall always be 0x2: Obstacle";
CM_ SG_ 965 FRM_6_ObjElevnStsConf_07 "Front Radar Moudle_X_Object Elevation Status Confidence_01
前雷达目标物的高度状态的置信度_01
The Confidence Of An Object Elevation Status
Note: Elevation Status Confidence of moving object or stopped object shall always be 100%";
CM_ SG_ 965 FRM_6_ObjHeading_07 "Front Radar Moudle_X_Object Heading_01
前雷达目标物朝向_01
Heading of object 
Note: A rotation vector with anticlock-rotating as positive +π shall be used instead of -π when obect vertically backward
Note: Heading of static object shall always be 0";
CM_ SG_ 966 FRM_7_CRC "Profile5:E2E CRC16 (polynomial:0x1021)       
DataID:Use CANID,other bits Fill with 0";
CM_ SG_ 966 FRM_7_RollgCntr "Profile5:E2E Rolling message counter";
CM_ SG_ 966 FRM_7_ObjBlockCounter "Front Radar Moudle_X_Object Block Counter
前雷达目标物块计数值";
CM_ SG_ 966 FRM_7_ObjID_08 "Front Radar Moudle_X_Object ID_00
前雷达目标物身份标识码_00
ID Is An Identifier Number That Allows For Tracking Of Persistent Objects Over Time
Note:A value of 0 indicates 'no object'";
CM_ SG_ 966 FRM_7_ObjClosestDistX_08 "Front Radar Moudle_X_Object Closest Distance X_00
前雷达目标物最近点在X轴上的距离_00
Closest Position Of Target Vehicle In X Direction
The rear axle center coordinate system is used";
CM_ SG_ 966 FRM_7_ObjClosestDistY_08 "Front Radar Moudle_X_Object Closest Distance Y_00
前雷达距目标物最近点在Y轴上的距离_00
Closest Position Of Target Vehicle In Y Direction
The rear axle center coordinate system is used";
CM_ SG_ 966 FRM_7_ObjRelVelX_08 "Front Radar Moudle_X_Object Relative Velocity X_00
前雷达目标物在X轴上的相对速度_00
Relative Target Object Velocity In X Direction";
CM_ SG_ 966 FRM_7_ObjRelVelY_08 "Front Radar Moudle_X_Object Relative Velocity Y_00
前雷达目标物在Y轴上的相对速度_00
Relative Target Object Velocity In Y Direction";
CM_ SG_ 966 FRM_7_ObjAccelX_08 "Front Radar Moudle_X_Object Acceleration X_00
前雷达目标物在X轴上的加速度_00
Relative Target Object Acceleration In X Direction";
CM_ SG_ 966 FRM_7_ObjAccelY_08 "Front Radar Moudle_X_Object Acceleration Y_00
前雷达目标物在Y轴上的加速度_00
Relative Target Object Acceleration In Y Direction";
CM_ SG_ 966 FRM_7_ObjClosestDistXStd_08 "Front Radar Moudle_X_Object Closest Distance X Standard_00
前雷达目标物最近点在X轴上的距离的标准差_00
Standard Deviation Of Closest Position Of Target Vehicle in X Direction";
CM_ SG_ 966 FRM_7_ObjClosestDistYStd_08 "Front Radar Moudle_X_Object Closest Distance Y Standard_00
前雷达目标物最近点在Y轴上的距离的标准差_00
Standard Deviation Of Closest Position Of Target Vehicle in Y Direction";
CM_ SG_ 966 FRM_7_ObjRelVelXStd_08 "Front Radar Moudle_X_Object Relative Velocity X Standard_00
前雷达目标物在X轴上的相对速度的标准差_00
Standard Deviation Of Relative Velocity X";
CM_ SG_ 966 FRM_7_ObjRelVelYStd_08 "Front Radar Moudle_X_Object Relative Velocity Y Standard_00
前雷达目标物在Y轴上的相对速度的标准差_00
Standard Deviation Of Relative Velocity Y";
CM_ SG_ 966 FRM_7_ObjRelAccelXStd_08 "Front Radar Moudle_X_Object Relative  Acceleration X Standard_00
前雷达目标物在X轴上的相对加速度的标准差_00
Standard Deviation Of Relative Acceleration X";
CM_ SG_ 966 FRM_7_ObjRelAccelYStd_08 "Front Radar Moudle_X_Object Relative  Acceleration Y Standard_00
前雷达目标物相对加速度在Y轴上的标准差_00
Standard Deviation Of Relative Acceleration Y";
CM_ SG_ 966 FRM_7_ObjExistProb_08 "Front Radar Moudle_X_Object Exist Probability_00
前雷达目标物存在的可能性_00
The Probability Of An Object To Exist In Reality";
CM_ SG_ 966 FRM_7_ObjType_08 "Front Radar Moudle_X_Object Type_00
前雷达目标物的分类_00
Class Of Object Type
Note: Type of static object shall always be 0x0: unknown";
CM_ SG_ 966 FRM_7_ObjTypeConf_08 "Front Radar Moudle_X_Object Type Confidence_00
前雷达目标物分类的置信度_00
The Class Confidence Of Object Type";
CM_ SG_ 966 FRM_7_ObjTrackSts_08 "Front Radar Moudle_X_Object Track Status_00
前雷达目标物的跟踪状态_00
Signal To Indicate The Object Track Status";
CM_ SG_ 966 FRM_7_ObjMotionSts_08 "Front Radar Moudle_X_Object Motion Status_00
前雷达目标物的运动状态_00
Signal To Indicate The Object Whether Moving or Stopped or Static";
CM_ SG_ 966 FRM_7_ObjMotionDirection_08 "Front Radar Moudle_X_Object Motion Direction_00
前雷达目标物的运动方向_00
Signal To Indicate The Object Moving Direction.
Note: Moving direction of static object or stopped object shall always be 0x0: Unknown";
CM_ SG_ 966 FRM_7_ObjCenterDistX_08 "Front Radar Moudle_X_Object Center Distance X_00
前雷达目标物中心点在X轴方向的距离_00
Center Position Of Target Vehicle In X Direction
The rear axle center coordinate system is used";
CM_ SG_ 966 FRM_7_ObjCenterDistY_08 "Front Radar Moudle_X_Object Center Distance Y_00
前雷达目标物中心点在Y轴方向的距离_00
Center Position Of Target Vehicle In Y Direction
The rear axle center coordinate system is used";
CM_ SG_ 966 FRM_7_ObjLength_08 "Front Radar Moudle_X_Object Length_00
前雷达目标物的长度_00
Length Of Target
Note: Length of static object shall always be 0";
CM_ SG_ 966 FRM_7_ObjWidth_08 "Front Radar Moudle_X_Object Width_00
前雷达目标物的宽度_00
Width Of Target
Note: Width of static object shall always be 0";
CM_ SG_ 966 FRM_7_ObjElevnSts_08 "Front Radar Moudle_X_Object Elevation Status_00
前雷达目标物的高度状态_00
The Elevation Status Of An Object
Note: Elevation Status of moving object or stopped object shall always be 0x2: Obstacle";
CM_ SG_ 966 FRM_7_ObjElevnStsConf_08 "Front Radar Moudle_X_Object Elevation Status Confidence_00
前雷达目标物的高度状态的置信度_00
The Confidence Of An Object Elevation Status
Note: Elevation Status Confidence of moving object or stopped object shall always be 100%";
CM_ SG_ 966 FRM_7_ObjHeading_08 "Front Radar Moudle_X_Object Heading_00
前雷达目标物朝向_00
Heading of object 
Note: A rotation vector with anticlock-rotating as positive +π shall be used instead of -π when obect vertically backward
Note: Heading of static object shall always be 0";
CM_ SG_ 966 FRM_7_ObjID_09 "Front Radar Moudle_X_Object ID_01
前雷达目标物身份标识码_01
ID Is An Identifier Number That Allows For Tracking Of Persistent Objects Over Time
Note:A value of 0 indicates 'no object'";
CM_ SG_ 966 FRM_7_ObjClosestDistX_09 "Front Radar Moudle_X_Object Closest Distance X_01
前雷达目标物最近点在X轴上的距离_01
Closest Position Of Target Vehicle In X Direction
The rear axle center coordinate system is used";
CM_ SG_ 966 FRM_7_ObjClosestDistY_09 "Front Radar Moudle_X_Object Closest Distance Y_01
前雷达距目标物最近点在Y轴上的距离_01
Closest Position Of Target Vehicle In Y Direction
The rear axle center coordinate system is used";
CM_ SG_ 966 FRM_7_ObjRelVelX_09 "Front Radar Moudle_X_Object Relative Velocity X_01
前雷达目标物在X轴上的相对速度_01
Relative Target Object Velocity In X Direction";
CM_ SG_ 966 FRM_7_ObjRelVelY_09 "Front Radar Moudle_X_Object Relative Velocity Y_01
前雷达目标物在Y轴上的相对速度_01
Relative Target Object Velocity In Y Direction";
CM_ SG_ 966 FRM_7_ObjAccelX_09 "Front Radar Moudle_X_Object Acceleration X_01
前雷达目标物在X轴上的加速度_01
Relative Target Object Acceleration In X Direction";
CM_ SG_ 966 FRM_7_ObjAccelY_09 "Front Radar Moudle_X_Object Acceleration Y_01
前雷达目标物在Y轴上的加速度_01
Relative Target Object Acceleration In Y Direction";
CM_ SG_ 966 FRM_7_ObjClosestDistXStd_09 "Front Radar Moudle_X_Object Closest Distance X Standard_01
前雷达目标物最近点在X轴上的距离的标准差_01
Standard Deviation Of Closest Position Of Target Vehicle in X Direction";
CM_ SG_ 966 FRM_7_ObjClosestDistYStd_09 "Front Radar Moudle_X_Object Closest Distance Y Standard_01
前雷达目标物最近点在Y轴上的距离的标准差_01
Standard Deviation Of Closest Position Of Target Vehicle in Y Direction";
CM_ SG_ 966 FRM_7_ObjRelVelXStd_09 "Front Radar Moudle_X_Object Relative Velocity X Standard_01
前雷达目标物在X轴上的相对速度的标准差_01
Standard Deviation Of Relative Velocity X";
CM_ SG_ 966 FRM_7_ObjRelVelYStd_09 "Front Radar Moudle_X_Object Relative Velocity Y Standard_01
前雷达目标物在Y轴上的相对速度的标准差_01
Standard Deviation Of Relative Velocity Y";
CM_ SG_ 966 FRM_7_ObjRelAccelXStd_09 "Front Radar Moudle_X_Object Relative  Acceleration X Standard_01
前雷达目标物在X轴上的相对加速度的标准差_01
Standard Deviation Of Relative Acceleration X";
CM_ SG_ 966 FRM_7_ObjRelAccelYStd_09 "Front Radar Moudle_X_Object Relative  Acceleration Y Standard_01
前雷达目标物相对加速度在Y轴上的标准差_01
Standard Deviation Of Relative Acceleration Y";
CM_ SG_ 966 FRM_7_ObjExistProb_09 "Front Radar Moudle_X_Object Exist Probability_01
前雷达目标物存在的可能性_01
The Probability Of An Object To Exist In Reality";
CM_ SG_ 966 FRM_7_ObjType_09 "Front Radar Moudle_X_Object Type_01
前雷达目标物的分类_01
Class Of Object Type
Note: Type of static object shall always be 0x0: unknown";
CM_ SG_ 966 FRM_7_ObjTypeConf_09 "Front Radar Moudle_X_Object Type Confidence_01
前雷达目标物分类的置信度_01
The Class Confidence Of Object Type";
CM_ SG_ 966 FRM_7_ObjTrackSts_09 "Front Radar Moudle_X_Object Track Status_01
前雷达目标物的跟踪状态_01
Signal To Indicate The Object Track Status";
CM_ SG_ 966 FRM_7_ObjMotionSts_09 "Front Radar Moudle_X_Object Motion Status_01
前雷达目标物的运动状态_01
Signal To Indicate The Object Whether Moving or Stopped or Static";
CM_ SG_ 966 FRM_7_ObjMotionDirection_09 "Front Radar Moudle_X_Object Motion Direction_01
前雷达目标物的运动方向_01
Signal To Indicate The Object Moving Direction.
Note: Moving direction of static object or stopped object shall always be 0x0: Unknown";
CM_ SG_ 966 FRM_7_ObjCenterDistX_09 "Front Radar Moudle_X_Object Center Distance X_01
前雷达目标物中心点在X轴方向的距离_01
Center Position Of Target Vehicle In X Direction
The rear axle center coordinate system is used";
CM_ SG_ 966 FRM_7_ObjCenterDistY_09 "Front Radar Moudle_X_Object Center Distance Y_01
前雷达目标物中心点在Y轴方向的距离_01
Center Position Of Target Vehicle In Y Direction
The rear axle center coordinate system is used";
CM_ SG_ 966 FRM_7_ObjLength_09 "Front Radar Moudle_X_Object Length_01
前雷达目标物的长度_01
Length Of Target
Note: Length of static object shall always be 0";
CM_ SG_ 966 FRM_7_ObjWidth_09 "Front Radar Moudle_X_Object Width_01
前雷达目标物的宽度_01
Width Of Target
Note: Width of static object shall always be 0";
CM_ SG_ 966 FRM_7_ObjElevnSts_09 "Front Radar Moudle_X_Object Elevation Status_01
前雷达目标物的高度状态_01
The Elevation Status Of An Object
Note: Elevation Status of moving object or stopped object shall always be 0x2: Obstacle";
CM_ SG_ 966 FRM_7_ObjElevnStsConf_09 "Front Radar Moudle_X_Object Elevation Status Confidence_01
前雷达目标物的高度状态的置信度_01
The Confidence Of An Object Elevation Status
Note: Elevation Status Confidence of moving object or stopped object shall always be 100%";
CM_ SG_ 966 FRM_7_ObjHeading_09 "Front Radar Moudle_X_Object Heading_01
前雷达目标物朝向_01
Heading of object 
Note: A rotation vector with anticlock-rotating as positive +π shall be used instead of -π when obect vertically backward
Note: Heading of static object shall always be 0";
CM_ SG_ 967 FRM_8_CRC "Profile5:E2E CRC16 (polynomial:0x1021)       
DataID:Use CANID,other bits Fill with 0";
CM_ SG_ 967 FRM_8_RollgCntr "Profile5:E2E Rolling message counter";
CM_ SG_ 967 FRM_8_ObjBlockCounter "Front Radar Moudle_X_Object Block Counter
前雷达目标物块计数值";
CM_ SG_ 967 FRM_8_ObjID_10 "Front Radar Moudle_X_Object ID_00
前雷达目标物身份标识码_00
ID Is An Identifier Number That Allows For Tracking Of Persistent Objects Over Time
Note:A value of 0 indicates 'no object'";
CM_ SG_ 967 FRM_8_ObjClosestDistX_10 "Front Radar Moudle_X_Object Closest Distance X_00
前雷达目标物最近点在X轴上的距离_00
Closest Position Of Target Vehicle In X Direction
The rear axle center coordinate system is used";
CM_ SG_ 967 FRM_8_ObjClosestDistY_10 "Front Radar Moudle_X_Object Closest Distance Y_00
前雷达距目标物最近点在Y轴上的距离_00
Closest Position Of Target Vehicle In Y Direction
The rear axle center coordinate system is used";
CM_ SG_ 967 FRM_8_ObjRelVelX_10 "Front Radar Moudle_X_Object Relative Velocity X_00
前雷达目标物在X轴上的相对速度_00
Relative Target Object Velocity In X Direction";
CM_ SG_ 967 FRM_8_ObjRelVelY_10 "Front Radar Moudle_X_Object Relative Velocity Y_00
前雷达目标物在Y轴上的相对速度_00
Relative Target Object Velocity In Y Direction";
CM_ SG_ 967 FRM_8_ObjAccelX_10 "Front Radar Moudle_X_Object Acceleration X_00
前雷达目标物在X轴上的加速度_00
Relative Target Object Acceleration In X Direction";
CM_ SG_ 967 FRM_8_ObjAccelY_10 "Front Radar Moudle_X_Object Acceleration Y_00
前雷达目标物在Y轴上的加速度_00
Relative Target Object Acceleration In Y Direction";
CM_ SG_ 967 FRM_8_ObjClosestDistXStd_10 "Front Radar Moudle_X_Object Closest Distance X Standard_00
前雷达目标物最近点在X轴上的距离的标准差_00
Standard Deviation Of Closest Position Of Target Vehicle in X Direction";
CM_ SG_ 967 FRM_8_ObjClosestDistYStd_10 "Front Radar Moudle_X_Object Closest Distance Y Standard_00
前雷达目标物最近点在Y轴上的距离的标准差_00
Standard Deviation Of Closest Position Of Target Vehicle in Y Direction";
CM_ SG_ 967 FRM_8_ObjRelVelXStd_10 "Front Radar Moudle_X_Object Relative Velocity X Standard_00
前雷达目标物在X轴上的相对速度的标准差_00
Standard Deviation Of Relative Velocity X";
CM_ SG_ 967 FRM_8_ObjRelVelYStd_10 "Front Radar Moudle_X_Object Relative Velocity Y Standard_00
前雷达目标物在Y轴上的相对速度的标准差_00
Standard Deviation Of Relative Velocity Y";
CM_ SG_ 967 FRM_8_ObjRelAccelXStd_10 "Front Radar Moudle_X_Object Relative  Acceleration X Standard_00
前雷达目标物在X轴上的相对加速度的标准差_00
Standard Deviation Of Relative Acceleration X";
CM_ SG_ 967 FRM_8_ObjRelAccelYStd_10 "Front Radar Moudle_X_Object Relative  Acceleration Y Standard_00
前雷达目标物相对加速度在Y轴上的标准差_00
Standard Deviation Of Relative Acceleration Y";
CM_ SG_ 967 FRM_8_ObjExistProb_10 "Front Radar Moudle_X_Object Exist Probability_00
前雷达目标物存在的可能性_00
The Probability Of An Object To Exist In Reality";
CM_ SG_ 967 FRM_8_ObjType_10 "Front Radar Moudle_X_Object Type_00
前雷达目标物的分类_00
Class Of Object Type
Note: Type of static object shall always be 0x0: unknown";
CM_ SG_ 967 FRM_8_ObjTypeConf_10 "Front Radar Moudle_X_Object Type Confidence_00
前雷达目标物分类的置信度_00
The Class Confidence Of Object Type";
CM_ SG_ 967 FRM_8_ObjTrackSts_10 "Front Radar Moudle_X_Object Track Status_00
前雷达目标物的跟踪状态_00
Signal To Indicate The Object Track Status";
CM_ SG_ 967 FRM_8_ObjMotionSts_10 "Front Radar Moudle_X_Object Motion Status_00
前雷达目标物的运动状态_00
Signal To Indicate The Object Whether Moving or Stopped or Static";
CM_ SG_ 967 FRM_8_ObjMotionDirection_10 "Front Radar Moudle_X_Object Motion Direction_00
前雷达目标物的运动方向_00
Signal To Indicate The Object Moving Direction.
Note: Moving direction of static object or stopped object shall always be 0x0: Unknown";
CM_ SG_ 967 FRM_8_ObjCenterDistX_10 "Front Radar Moudle_X_Object Center Distance X_00
前雷达目标物中心点在X轴方向的距离_00
Center Position Of Target Vehicle In X Direction
The rear axle center coordinate system is used";
CM_ SG_ 967 FRM_8_ObjCenterDistY_10 "Front Radar Moudle_X_Object Center Distance Y_00
前雷达目标物中心点在Y轴方向的距离_00
Center Position Of Target Vehicle In Y Direction
The rear axle center coordinate system is used";
CM_ SG_ 967 FRM_8_ObjLength_10 "Front Radar Moudle_X_Object Length_00
前雷达目标物的长度_00
Length Of Target
Note: Length of static object shall always be 0";
CM_ SG_ 967 FRM_8_ObjWidth_10 "Front Radar Moudle_X_Object Width_00
前雷达目标物的宽度_00
Width Of Target
Note: Width of static object shall always be 0";
CM_ SG_ 967 FRM_8_ObjElevnSts_10 "Front Radar Moudle_X_Object Elevation Status_00
前雷达目标物的高度状态_00
The Elevation Status Of An Object
Note: Elevation Status of moving object or stopped object shall always be 0x2: Obstacle";
CM_ SG_ 967 FRM_8_ObjElevnStsConf_10 "Front Radar Moudle_X_Object Elevation Status Confidence_00
前雷达目标物的高度状态的置信度_00
The Confidence Of An Object Elevation Status
Note: Elevation Status Confidence of moving object or stopped object shall always be 100%";
CM_ SG_ 967 FRM_8_ObjHeading_10 "Front Radar Moudle_X_Object Heading_00
前雷达目标物朝向_00
Heading of object 
Note: A rotation vector with anticlock-rotating as positive +π shall be used instead of -π when obect vertically backward
Note: Heading of static object shall always be 0";
CM_ SG_ 967 FRM_8_ObjID_11 "Front Radar Moudle_X_Object ID_01
前雷达目标物身份标识码_01
ID Is An Identifier Number That Allows For Tracking Of Persistent Objects Over Time
Note:A value of 0 indicates 'no object'";
CM_ SG_ 967 FRM_8_ObjClosestDistX_11 "Front Radar Moudle_X_Object Closest Distance X_01
前雷达目标物最近点在X轴上的距离_01
Closest Position Of Target Vehicle In X Direction
The rear axle center coordinate system is used";
CM_ SG_ 967 FRM_8_ObjClosestDistY_11 "Front Radar Moudle_X_Object Closest Distance Y_01
前雷达距目标物最近点在Y轴上的距离_01
Closest Position Of Target Vehicle In Y Direction
The rear axle center coordinate system is used";
CM_ SG_ 967 FRM_8_ObjRelVelX_11 "Front Radar Moudle_X_Object Relative Velocity X_01
前雷达目标物在X轴上的相对速度_01
Relative Target Object Velocity In X Direction";
CM_ SG_ 967 FRM_8_ObjRelVelY_11 "Front Radar Moudle_X_Object Relative Velocity Y_01
前雷达目标物在Y轴上的相对速度_01
Relative Target Object Velocity In Y Direction";
CM_ SG_ 967 FRM_8_ObjAccelX_11 "Front Radar Moudle_X_Object Acceleration X_01
前雷达目标物在X轴上的加速度_01
Relative Target Object Acceleration In X Direction";
CM_ SG_ 967 FRM_8_ObjAccelY_11 "Front Radar Moudle_X_Object Acceleration Y_01
前雷达目标物在Y轴上的加速度_01
Relative Target Object Acceleration In Y Direction";
CM_ SG_ 967 FRM_8_ObjClosestDistXStd_11 "Front Radar Moudle_X_Object Closest Distance X Standard_01
前雷达目标物最近点在X轴上的距离的标准差_01
Standard Deviation Of Closest Position Of Target Vehicle in X Direction";
CM_ SG_ 967 FRM_8_ObjClosestDistYStd_11 "Front Radar Moudle_X_Object Closest Distance Y Standard_01
前雷达目标物最近点在Y轴上的距离的标准差_01
Standard Deviation Of Closest Position Of Target Vehicle in Y Direction";
CM_ SG_ 967 FRM_8_ObjRelVelXStd_11 "Front Radar Moudle_X_Object Relative Velocity X Standard_01
前雷达目标物在X轴上的相对速度的标准差_01
Standard Deviation Of Relative Velocity X";
CM_ SG_ 967 FRM_8_ObjRelVelYStd_11 "Front Radar Moudle_X_Object Relative Velocity Y Standard_01
前雷达目标物在Y轴上的相对速度的标准差_01
Standard Deviation Of Relative Velocity Y";
CM_ SG_ 967 FRM_8_ObjRelAccelXStd_11 "Front Radar Moudle_X_Object Relative  Acceleration X Standard_01
前雷达目标物在X轴上的相对加速度的标准差_01
Standard Deviation Of Relative Acceleration X";
CM_ SG_ 967 FRM_8_ObjRelAccelYStd_11 "Front Radar Moudle_X_Object Relative  Acceleration Y Standard_01
前雷达目标物相对加速度在Y轴上的标准差_01
Standard Deviation Of Relative Acceleration Y";
CM_ SG_ 967 FRM_8_ObjExistProb_11 "Front Radar Moudle_X_Object Exist Probability_01
前雷达目标物存在的可能性_01
The Probability Of An Object To Exist In Reality";
CM_ SG_ 967 FRM_8_ObjType_11 "Front Radar Moudle_X_Object Type_01
前雷达目标物的分类_01
Class Of Object Type
Note: Type of static object shall always be 0x0: unknown";
CM_ SG_ 967 FRM_8_ObjTypeConf_11 "Front Radar Moudle_X_Object Type Confidence_01
前雷达目标物分类的置信度_01
The Class Confidence Of Object Type";
CM_ SG_ 967 FRM_8_ObjTrackSts_11 "Front Radar Moudle_X_Object Track Status_01
前雷达目标物的跟踪状态_01
Signal To Indicate The Object Track Status";
CM_ SG_ 967 FRM_8_ObjMotionSts_11 "Front Radar Moudle_X_Object Motion Status_01
前雷达目标物的运动状态_01
Signal To Indicate The Object Whether Moving or Stopped or Static";
CM_ SG_ 967 FRM_8_ObjMotionDirection_11 "Front Radar Moudle_X_Object Motion Direction_01
前雷达目标物的运动方向_01
Signal To Indicate The Object Moving Direction.
Note: Moving direction of static object or stopped object shall always be 0x0: Unknown";
CM_ SG_ 967 FRM_8_ObjCenterDistX_11 "Front Radar Moudle_X_Object Center Distance X_01
前雷达目标物中心点在X轴方向的距离_01
Center Position Of Target Vehicle In X Direction
The rear axle center coordinate system is used";
CM_ SG_ 967 FRM_8_ObjCenterDistY_11 "Front Radar Moudle_X_Object Center Distance Y_01
前雷达目标物中心点在Y轴方向的距离_01
Center Position Of Target Vehicle In Y Direction
The rear axle center coordinate system is used";
CM_ SG_ 967 FRM_8_ObjLength_11 "Front Radar Moudle_X_Object Length_01
前雷达目标物的长度_01
Length Of Target
Note: Length of static object shall always be 0";
CM_ SG_ 967 FRM_8_ObjWidth_11 "Front Radar Moudle_X_Object Width_01
前雷达目标物的宽度_01
Width Of Target
Note: Width of static object shall always be 0";
CM_ SG_ 967 FRM_8_ObjElevnSts_11 "Front Radar Moudle_X_Object Elevation Status_01
前雷达目标物的高度状态_01
The Elevation Status Of An Object
Note: Elevation Status of moving object or stopped object shall always be 0x2: Obstacle";
CM_ SG_ 967 FRM_8_ObjElevnStsConf_11 "Front Radar Moudle_X_Object Elevation Status Confidence_01
前雷达目标物的高度状态的置信度_01
The Confidence Of An Object Elevation Status
Note: Elevation Status Confidence of moving object or stopped object shall always be 100%";
CM_ SG_ 967 FRM_8_ObjHeading_11 "Front Radar Moudle_X_Object Heading_01
前雷达目标物朝向_01
Heading of object 
Note: A rotation vector with anticlock-rotating as positive +π shall be used instead of -π when obect vertically backward
Note: Heading of static object shall always be 0";
CM_ SG_ 968 FRM_9_CRC "Profile5:E2E CRC16 (polynomial:0x1021)       
DataID:Use CANID,other bits Fill with 0";
CM_ SG_ 968 FRM_9_RollgCntr "Profile5:E2E Rolling message counter";
CM_ SG_ 968 FRM_9_ObjBlockCounter "Front Radar Moudle_X_Object Block Counter
前雷达目标物块计数值";
CM_ SG_ 968 FRM_9_ObjID_12 "Front Radar Moudle_X_Object ID_00
前雷达目标物身份标识码_00
ID Is An Identifier Number That Allows For Tracking Of Persistent Objects Over Time
Note:A value of 0 indicates 'no object'";
CM_ SG_ 968 FRM_9_ObjClosestDistX_12 "Front Radar Moudle_X_Object Closest Distance X_00
前雷达目标物最近点在X轴上的距离_00
Closest Position Of Target Vehicle In X Direction
The rear axle center coordinate system is used";
CM_ SG_ 968 FRM_9_ObjClosestDistY_12 "Front Radar Moudle_X_Object Closest Distance Y_00
前雷达距目标物最近点在Y轴上的距离_00
Closest Position Of Target Vehicle In Y Direction
The rear axle center coordinate system is used";
CM_ SG_ 968 FRM_9_ObjRelVelX_12 "Front Radar Moudle_X_Object Relative Velocity X_00
前雷达目标物在X轴上的相对速度_00
Relative Target Object Velocity In X Direction";
CM_ SG_ 968 FRM_9_ObjRelVelY_12 "Front Radar Moudle_X_Object Relative Velocity Y_00
前雷达目标物在Y轴上的相对速度_00
Relative Target Object Velocity In Y Direction";
CM_ SG_ 968 FRM_9_ObjAccelX_12 "Front Radar Moudle_X_Object Acceleration X_00
前雷达目标物在X轴上的加速度_00
Relative Target Object Acceleration In X Direction";
CM_ SG_ 968 FRM_9_ObjAccelY_12 "Front Radar Moudle_X_Object Acceleration Y_00
前雷达目标物在Y轴上的加速度_00
Relative Target Object Acceleration In Y Direction";
CM_ SG_ 968 FRM_9_ObjClosestDistXStd_12 "Front Radar Moudle_X_Object Closest Distance X Standard_00
前雷达目标物最近点在X轴上的距离的标准差_00
Standard Deviation Of Closest Position Of Target Vehicle in X Direction";
CM_ SG_ 968 FRM_9_ObjClosestDistYStd_12 "Front Radar Moudle_X_Object Closest Distance Y Standard_00
前雷达目标物最近点在Y轴上的距离的标准差_00
Standard Deviation Of Closest Position Of Target Vehicle in Y Direction";
CM_ SG_ 968 FRM_9_ObjRelVelXStd_12 "Front Radar Moudle_X_Object Relative Velocity X Standard_00
前雷达目标物在X轴上的相对速度的标准差_00
Standard Deviation Of Relative Velocity X";
CM_ SG_ 968 FRM_9_ObjRelVelYStd_12 "Front Radar Moudle_X_Object Relative Velocity Y Standard_00
前雷达目标物在Y轴上的相对速度的标准差_00
Standard Deviation Of Relative Velocity Y";
CM_ SG_ 968 FRM_9_ObjRelAccelXStd_12 "Front Radar Moudle_X_Object Relative  Acceleration X Standard_00
前雷达目标物在X轴上的相对加速度的标准差_00
Standard Deviation Of Relative Acceleration X";
CM_ SG_ 968 FRM_9_ObjRelAccelYStd_12 "Front Radar Moudle_X_Object Relative  Acceleration Y Standard_00
前雷达目标物相对加速度在Y轴上的标准差_00
Standard Deviation Of Relative Acceleration Y";
CM_ SG_ 968 FRM_9_ObjExistProb_12 "Front Radar Moudle_X_Object Exist Probability_00
前雷达目标物存在的可能性_00
The Probability Of An Object To Exist In Reality";
CM_ SG_ 968 FRM_9_ObjType_12 "Front Radar Moudle_X_Object Type_00
前雷达目标物的分类_00
Class Of Object Type
Note: Type of static object shall always be 0x0: unknown";
CM_ SG_ 968 FRM_9_ObjTypeConf_12 "Front Radar Moudle_X_Object Type Confidence_00
前雷达目标物分类的置信度_00
The Class Confidence Of Object Type";
CM_ SG_ 968 FRM_9_ObjTrackSts_12 "Front Radar Moudle_X_Object Track Status_00
前雷达目标物的跟踪状态_00
Signal To Indicate The Object Track Status";
CM_ SG_ 968 FRM_9_ObjMotionSts_12 "Front Radar Moudle_X_Object Motion Status_00
前雷达目标物的运动状态_00
Signal To Indicate The Object Whether Moving or Stopped or Static";
CM_ SG_ 968 FRM_9_ObjMotionDirection_12 "Front Radar Moudle_X_Object Motion Direction_00
前雷达目标物的运动方向_00
Signal To Indicate The Object Moving Direction.
Note: Moving direction of static object or stopped object shall always be 0x0: Unknown";
CM_ SG_ 968 FRM_9_ObjCenterDistX_12 "Front Radar Moudle_X_Object Center Distance X_00
前雷达目标物中心点在X轴方向的距离_00
Center Position Of Target Vehicle In X Direction
The rear axle center coordinate system is used";
CM_ SG_ 968 FRM_9_ObjCenterDistY_12 "Front Radar Moudle_X_Object Center Distance Y_00
前雷达目标物中心点在Y轴方向的距离_00
Center Position Of Target Vehicle In Y Direction
The rear axle center coordinate system is used";
CM_ SG_ 968 FRM_9_ObjLength_12 "Front Radar Moudle_X_Object Length_00
前雷达目标物的长度_00
Length Of Target
Note: Length of static object shall always be 0";
CM_ SG_ 968 FRM_9_ObjWidth_12 "Front Radar Moudle_X_Object Width_00
前雷达目标物的宽度_00
Width Of Target
Note: Width of static object shall always be 0";
CM_ SG_ 968 FRM_9_ObjElevnSts_12 "Front Radar Moudle_X_Object Elevation Status_00
前雷达目标物的高度状态_00
The Elevation Status Of An Object
Note: Elevation Status of moving object or stopped object shall always be 0x2: Obstacle";
CM_ SG_ 968 FRM_9_ObjElevnStsConf_12 "Front Radar Moudle_X_Object Elevation Status Confidence_00
前雷达目标物的高度状态的置信度_00
The Confidence Of An Object Elevation Status
Note: Elevation Status Confidence of moving object or stopped object shall always be 100%";
CM_ SG_ 968 FRM_9_ObjHeading_12 "Front Radar Moudle_X_Object Heading_00
前雷达目标物朝向_00
Heading of object 
Note: A rotation vector with anticlock-rotating as positive +π shall be used instead of -π when obect vertically backward
Note: Heading of static object shall always be 0";
CM_ SG_ 968 FRM_9_ObjID_13 "Front Radar Moudle_X_Object ID_01
前雷达目标物身份标识码_01
ID Is An Identifier Number That Allows For Tracking Of Persistent Objects Over Time
Note:A value of 0 indicates 'no object'";
CM_ SG_ 968 FRM_9_ObjClosestDistX_13 "Front Radar Moudle_X_Object Closest Distance X_01
前雷达目标物最近点在X轴上的距离_01
Closest Position Of Target Vehicle In X Direction
The rear axle center coordinate system is used";
CM_ SG_ 968 FRM_9_ObjClosestDistY_13 "Front Radar Moudle_X_Object Closest Distance Y_01
前雷达距目标物最近点在Y轴上的距离_01
Closest Position Of Target Vehicle In Y Direction
The rear axle center coordinate system is used";
CM_ SG_ 968 FRM_9_ObjRelVelX_13 "Front Radar Moudle_X_Object Relative Velocity X_01
前雷达目标物在X轴上的相对速度_01
Relative Target Object Velocity In X Direction";
CM_ SG_ 968 FRM_9_ObjRelVelY_13 "Front Radar Moudle_X_Object Relative Velocity Y_01
前雷达目标物在Y轴上的相对速度_01
Relative Target Object Velocity In Y Direction";
CM_ SG_ 968 FRM_9_ObjAccelX_13 "Front Radar Moudle_X_Object Acceleration X_01
前雷达目标物在X轴上的加速度_01
Relative Target Object Acceleration In X Direction";
CM_ SG_ 968 FRM_9_ObjAccelY_13 "Front Radar Moudle_X_Object Acceleration Y_01
前雷达目标物在Y轴上的加速度_01
Relative Target Object Acceleration In Y Direction";
CM_ SG_ 968 FRM_9_ObjClosestDistXStd_13 "Front Radar Moudle_X_Object Closest Distance X Standard_01
前雷达目标物最近点在X轴上的距离的标准差_01
Standard Deviation Of Closest Position Of Target Vehicle in X Direction";
CM_ SG_ 968 FRM_9_ObjClosestDistYStd_13 "Front Radar Moudle_X_Object Closest Distance Y Standard_01
前雷达目标物最近点在Y轴上的距离的标准差_01
Standard Deviation Of Closest Position Of Target Vehicle in Y Direction";
CM_ SG_ 968 FRM_9_ObjRelVelXStd_13 "Front Radar Moudle_X_Object Relative Velocity X Standard_01
前雷达目标物在X轴上的相对速度的标准差_01
Standard Deviation Of Relative Velocity X";
CM_ SG_ 968 FRM_9_ObjRelVelYStd_13 "Front Radar Moudle_X_Object Relative Velocity Y Standard_01
前雷达目标物在Y轴上的相对速度的标准差_01
Standard Deviation Of Relative Velocity Y";
CM_ SG_ 968 FRM_9_ObjRelAccelXStd_13 "Front Radar Moudle_X_Object Relative  Acceleration X Standard_01
前雷达目标物在X轴上的相对加速度的标准差_01
Standard Deviation Of Relative Acceleration X";
CM_ SG_ 968 FRM_9_ObjRelAccelYStd_13 "Front Radar Moudle_X_Object Relative  Acceleration Y Standard_01
前雷达目标物相对加速度在Y轴上的标准差_01
Standard Deviation Of Relative Acceleration Y";
CM_ SG_ 968 FRM_9_ObjExistProb_13 "Front Radar Moudle_X_Object Exist Probability_01
前雷达目标物存在的可能性_01
The Probability Of An Object To Exist In Reality";
CM_ SG_ 968 FRM_9_ObjType_13 "Front Radar Moudle_X_Object Type_01
前雷达目标物的分类_01
Class Of Object Type
Note: Type of static object shall always be 0x0: unknown";
CM_ SG_ 968 FRM_9_ObjTypeConf_13 "Front Radar Moudle_X_Object Type Confidence_01
前雷达目标物分类的置信度_01
The Class Confidence Of Object Type";
CM_ SG_ 968 FRM_9_ObjTrackSts_13 "Front Radar Moudle_X_Object Track Status_01
前雷达目标物的跟踪状态_01
Signal To Indicate The Object Track Status";
CM_ SG_ 968 FRM_9_ObjMotionSts_13 "Front Radar Moudle_X_Object Motion Status_01
前雷达目标物的运动状态_01
Signal To Indicate The Object Whether Moving or Stopped or Static";
CM_ SG_ 968 FRM_9_ObjMotionDirection_13 "Front Radar Moudle_X_Object Motion Direction_01
前雷达目标物的运动方向_01
Signal To Indicate The Object Moving Direction.
Note: Moving direction of static object or stopped object shall always be 0x0: Unknown";
CM_ SG_ 968 FRM_9_ObjCenterDistX_13 "Front Radar Moudle_X_Object Center Distance X_01
前雷达目标物中心点在X轴方向的距离_01
Center Position Of Target Vehicle In X Direction
The rear axle center coordinate system is used";
CM_ SG_ 968 FRM_9_ObjCenterDistY_13 "Front Radar Moudle_X_Object Center Distance Y_01
前雷达目标物中心点在Y轴方向的距离_01
Center Position Of Target Vehicle In Y Direction
The rear axle center coordinate system is used";
CM_ SG_ 968 FRM_9_ObjLength_13 "Front Radar Moudle_X_Object Length_01
前雷达目标物的长度_01
Length Of Target
Note: Length of static object shall always be 0";
CM_ SG_ 968 FRM_9_ObjWidth_13 "Front Radar Moudle_X_Object Width_01
前雷达目标物的宽度_01
Width Of Target
Note: Width of static object shall always be 0";
CM_ SG_ 968 FRM_9_ObjElevnSts_13 "Front Radar Moudle_X_Object Elevation Status_01
前雷达目标物的高度状态_01
The Elevation Status Of An Object
Note: Elevation Status of moving object or stopped object shall always be 0x2: Obstacle";
CM_ SG_ 968 FRM_9_ObjElevnStsConf_13 "Front Radar Moudle_X_Object Elevation Status Confidence_01
前雷达目标物的高度状态的置信度_01
The Confidence Of An Object Elevation Status
Note: Elevation Status Confidence of moving object or stopped object shall always be 100%";
CM_ SG_ 968 FRM_9_ObjHeading_13 "Front Radar Moudle_X_Object Heading_01
前雷达目标物朝向_01
Heading of object 
Note: A rotation vector with anticlock-rotating as positive +π shall be used instead of -π when obect vertically backward
Note: Heading of static object shall always be 0";
CM_ SG_ 969 FRM_10_CRC "Profile5:E2E CRC16 (polynomial:0x1021)       
DataID:Use CANID,other bits Fill with 0";
CM_ SG_ 969 FRM_10_RollgCntr "Profile5:E2E Rolling message counter";
CM_ SG_ 969 FRM_10_ObjBlockCounter "Front Radar Moudle_X_Object Block Counter
前雷达目标物块计数值";
CM_ SG_ 969 FRM_10_ObjID_14 "Front Radar Moudle_X_Object ID_00
前雷达目标物身份标识码_00
ID Is An Identifier Number That Allows For Tracking Of Persistent Objects Over Time
Note:A value of 0 indicates 'no object'";
CM_ SG_ 969 FRM_10_ObjClosestDistX_14 "Front Radar Moudle_X_Object Closest Distance X_00
前雷达目标物最近点在X轴上的距离_00
Closest Position Of Target Vehicle In X Direction
The rear axle center coordinate system is used";
CM_ SG_ 969 FRM_10_ObjClosestDistY_14 "Front Radar Moudle_X_Object Closest Distance Y_00
前雷达距目标物最近点在Y轴上的距离_00
Closest Position Of Target Vehicle In Y Direction
The rear axle center coordinate system is used";
CM_ SG_ 969 FRM_10_ObjRelVelX_14 "Front Radar Moudle_X_Object Relative Velocity X_00
前雷达目标物在X轴上的相对速度_00
Relative Target Object Velocity In X Direction";
CM_ SG_ 969 FRM_10_ObjRelVelY_14 "Front Radar Moudle_X_Object Relative Velocity Y_00
前雷达目标物在Y轴上的相对速度_00
Relative Target Object Velocity In Y Direction";
CM_ SG_ 969 FRM_10_ObjAccelX_14 "Front Radar Moudle_X_Object Acceleration X_00
前雷达目标物在X轴上的加速度_00
Relative Target Object Acceleration In X Direction";
CM_ SG_ 969 FRM_10_ObjAccelY_14 "Front Radar Moudle_X_Object Acceleration Y_00
前雷达目标物在Y轴上的加速度_00
Relative Target Object Acceleration In Y Direction";
CM_ SG_ 969 FRM_10_ObjClosestDistXStd_14 "Front Radar Moudle_X_Object Closest Distance X Standard_00
前雷达目标物最近点在X轴上的距离的标准差_00
Standard Deviation Of Closest Position Of Target Vehicle in X Direction";
CM_ SG_ 969 FRM_10_ObjClosestDistYStd_14 "Front Radar Moudle_X_Object Closest Distance Y Standard_00
前雷达目标物最近点在Y轴上的距离的标准差_00
Standard Deviation Of Closest Position Of Target Vehicle in Y Direction";
CM_ SG_ 969 FRM_10_ObjRelVelXStd_14 "Front Radar Moudle_X_Object Relative Velocity X Standard_00
前雷达目标物在X轴上的相对速度的标准差_00
Standard Deviation Of Relative Velocity X";
CM_ SG_ 969 FRM_10_ObjRelVelYStd_14 "Front Radar Moudle_X_Object Relative Velocity Y Standard_00
前雷达目标物在Y轴上的相对速度的标准差_00
Standard Deviation Of Relative Velocity Y";
CM_ SG_ 969 FRM_10_ObjRelAccelXStd_14 "Front Radar Moudle_X_Object Relative  Acceleration X Standard_00
前雷达目标物在X轴上的相对加速度的标准差_00
Standard Deviation Of Relative Acceleration X";
CM_ SG_ 969 FRM_10_ObjRelAccelYStd_14 "Front Radar Moudle_X_Object Relative  Acceleration Y Standard_00
前雷达目标物相对加速度在Y轴上的标准差_00
Standard Deviation Of Relative Acceleration Y";
CM_ SG_ 969 FRM_10_ObjExistProb_14 "Front Radar Moudle_X_Object Exist Probability_00
前雷达目标物存在的可能性_00
The Probability Of An Object To Exist In Reality";
CM_ SG_ 969 FRM_10_ObjType_14 "Front Radar Moudle_X_Object Type_00
前雷达目标物的分类_00
Class Of Object Type
Note: Type of static object shall always be 0x0: unknown";
CM_ SG_ 969 FRM_10_ObjTypeConf_14 "Front Radar Moudle_X_Object Type Confidence_00
前雷达目标物分类的置信度_00
The Class Confidence Of Object Type";
CM_ SG_ 969 FRM_10_ObjTrackSts_14 "Front Radar Moudle_X_Object Track Status_00
前雷达目标物的跟踪状态_00
Signal To Indicate The Object Track Status";
CM_ SG_ 969 FRM_10_ObjMotionSts_14 "Front Radar Moudle_X_Object Motion Status_00
前雷达目标物的运动状态_00
Signal To Indicate The Object Whether Moving or Stopped or Static";
CM_ SG_ 969 FRM_10_ObjMotionDirection_14 "Front Radar Moudle_X_Object Motion Direction_00
前雷达目标物的运动方向_00
Signal To Indicate The Object Moving Direction.
Note: Moving direction of static object or stopped object shall always be 0x0: Unknown";
CM_ SG_ 969 FRM_10_ObjCenterDistX_14 "Front Radar Moudle_X_Object Center Distance X_00
前雷达目标物中心点在X轴方向的距离_00
Center Position Of Target Vehicle In X Direction
The rear axle center coordinate system is used";
CM_ SG_ 969 FRM_10_ObjCenterDistY_14 "Front Radar Moudle_X_Object Center Distance Y_00
前雷达目标物中心点在Y轴方向的距离_00
Center Position Of Target Vehicle In Y Direction
The rear axle center coordinate system is used";
CM_ SG_ 969 FRM_10_ObjLength_14 "Front Radar Moudle_X_Object Length_00
前雷达目标物的长度_00
Length Of Target
Note: Length of static object shall always be 0";
CM_ SG_ 969 FRM_10_ObjWidth_14 "Front Radar Moudle_X_Object Width_00
前雷达目标物的宽度_00
Width Of Target
Note: Width of static object shall always be 0";
CM_ SG_ 969 FRM_10_ObjElevnSts_14 "Front Radar Moudle_X_Object Elevation Status_00
前雷达目标物的高度状态_00
The Elevation Status Of An Object
Note: Elevation Status of moving object or stopped object shall always be 0x2: Obstacle";
CM_ SG_ 969 FRM_10_ObjElevnStsConf_14 "Front Radar Moudle_X_Object Elevation Status Confidence_00
前雷达目标物的高度状态的置信度_00
The Confidence Of An Object Elevation Status
Note: Elevation Status Confidence of moving object or stopped object shall always be 100%";
CM_ SG_ 969 FRM_10_ObjHeading_14 "Front Radar Moudle_X_Object Heading_00
前雷达目标物朝向_00
Heading of object 
Note: A rotation vector with anticlock-rotating as positive +π shall be used instead of -π when obect vertically backward
Note: Heading of static object shall always be 0";
CM_ SG_ 969 FRM_10_ObjID_15 "Front Radar Moudle_X_Object ID_01
前雷达目标物身份标识码_01
ID Is An Identifier Number That Allows For Tracking Of Persistent Objects Over Time
Note:A value of 0 indicates 'no object'";
CM_ SG_ 969 FRM_10_ObjClosestDistX_15 "Front Radar Moudle_X_Object Closest Distance X_01
前雷达目标物最近点在X轴上的距离_01
Closest Position Of Target Vehicle In X Direction
The rear axle center coordinate system is used";
CM_ SG_ 969 FRM_10_ObjClosestDistY_15 "Front Radar Moudle_X_Object Closest Distance Y_01
前雷达距目标物最近点在Y轴上的距离_01
Closest Position Of Target Vehicle In Y Direction
The rear axle center coordinate system is used";
CM_ SG_ 969 FRM_10_ObjRelVelX_15 "Front Radar Moudle_X_Object Relative Velocity X_01
前雷达目标物在X轴上的相对速度_01
Relative Target Object Velocity In X Direction";
CM_ SG_ 969 FRM_10_ObjRelVelY_15 "Front Radar Moudle_X_Object Relative Velocity Y_01
前雷达目标物在Y轴上的相对速度_01
Relative Target Object Velocity In Y Direction";
CM_ SG_ 969 FRM_10_ObjAccelX_15 "Front Radar Moudle_X_Object Acceleration X_01
前雷达目标物在X轴上的加速度_01
Relative Target Object Acceleration In X Direction";
CM_ SG_ 969 FRM_10_ObjAccelY_15 "Front Radar Moudle_X_Object Acceleration Y_01
前雷达目标物在Y轴上的加速度_01
Relative Target Object Acceleration In Y Direction";
CM_ SG_ 969 FRM_10_ObjClosestDistXStd_15 "Front Radar Moudle_X_Object Closest Distance X Standard_01
前雷达目标物最近点在X轴上的距离的标准差_01
Standard Deviation Of Closest Position Of Target Vehicle in X Direction";
CM_ SG_ 969 FRM_10_ObjClosestDistYStd_15 "Front Radar Moudle_X_Object Closest Distance Y Standard_01
前雷达目标物最近点在Y轴上的距离的标准差_01
Standard Deviation Of Closest Position Of Target Vehicle in Y Direction";
CM_ SG_ 969 FRM_10_ObjRelVelXStd_15 "Front Radar Moudle_X_Object Relative Velocity X Standard_01
前雷达目标物在X轴上的相对速度的标准差_01
Standard Deviation Of Relative Velocity X";
CM_ SG_ 969 FRM_10_ObjRelVelYStd_15 "Front Radar Moudle_X_Object Relative Velocity Y Standard_01
前雷达目标物在Y轴上的相对速度的标准差_01
Standard Deviation Of Relative Velocity Y";
CM_ SG_ 969 FRM_10_ObjRelAccelXStd_15 "Front Radar Moudle_X_Object Relative  Acceleration X Standard_01
前雷达目标物在X轴上的相对加速度的标准差_01
Standard Deviation Of Relative Acceleration X";
CM_ SG_ 969 FRM_10_ObjRelAccelYStd_15 "Front Radar Moudle_X_Object Relative  Acceleration Y Standard_01
前雷达目标物相对加速度在Y轴上的标准差_01
Standard Deviation Of Relative Acceleration Y";
CM_ SG_ 969 FRM_10_ObjExistProb_15 "Front Radar Moudle_X_Object Exist Probability_01
前雷达目标物存在的可能性_01
The Probability Of An Object To Exist In Reality";
CM_ SG_ 969 FRM_10_ObjType_15 "Front Radar Moudle_X_Object Type_01
前雷达目标物的分类_01
Class Of Object Type
Note: Type of static object shall always be 0x0: unknown";
CM_ SG_ 969 FRM_10_ObjTypeConf_15 "Front Radar Moudle_X_Object Type Confidence_01
前雷达目标物分类的置信度_01
The Class Confidence Of Object Type";
CM_ SG_ 969 FRM_10_ObjTrackSts_15 "Front Radar Moudle_X_Object Track Status_01
前雷达目标物的跟踪状态_01
Signal To Indicate The Object Track Status";
CM_ SG_ 969 FRM_10_ObjMotionSts_15 "Front Radar Moudle_X_Object Motion Status_01
前雷达目标物的运动状态_01
Signal To Indicate The Object Whether Moving or Stopped or Static";
CM_ SG_ 969 FRM_10_ObjMotionDirection_15 "Front Radar Moudle_X_Object Motion Direction_01
前雷达目标物的运动方向_01
Signal To Indicate The Object Moving Direction.
Note: Moving direction of static object or stopped object shall always be 0x0: Unknown";
CM_ SG_ 969 FRM_10_ObjCenterDistX_15 "Front Radar Moudle_X_Object Center Distance X_01
前雷达目标物中心点在X轴方向的距离_01
Center Position Of Target Vehicle In X Direction
The rear axle center coordinate system is used";
CM_ SG_ 969 FRM_10_ObjCenterDistY_15 "Front Radar Moudle_X_Object Center Distance Y_01
前雷达目标物中心点在Y轴方向的距离_01
Center Position Of Target Vehicle In Y Direction
The rear axle center coordinate system is used";
CM_ SG_ 969 FRM_10_ObjLength_15 "Front Radar Moudle_X_Object Length_01
前雷达目标物的长度_01
Length Of Target
Note: Length of static object shall always be 0";
CM_ SG_ 969 FRM_10_ObjWidth_15 "Front Radar Moudle_X_Object Width_01
前雷达目标物的宽度_01
Width Of Target
Note: Width of static object shall always be 0";
CM_ SG_ 969 FRM_10_ObjElevnSts_15 "Front Radar Moudle_X_Object Elevation Status_01
前雷达目标物的高度状态_01
The Elevation Status Of An Object
Note: Elevation Status of moving object or stopped object shall always be 0x2: Obstacle";
CM_ SG_ 969 FRM_10_ObjElevnStsConf_15 "Front Radar Moudle_X_Object Elevation Status Confidence_01
前雷达目标物的高度状态的置信度_01
The Confidence Of An Object Elevation Status
Note: Elevation Status Confidence of moving object or stopped object shall always be 100%";
CM_ SG_ 969 FRM_10_ObjHeading_15 "Front Radar Moudle_X_Object Heading_01
前雷达目标物朝向_01
Heading of object 
Note: A rotation vector with anticlock-rotating as positive +π shall be used instead of -π when obect vertically backward
Note: Heading of static object shall always be 0";

BA_DEF_ BO_  "GenMsgSendType" ENUM  "Cyclic","Event","IfActive","CE","CA","NoMsgSendType";
BA_DEF_ BO_  "GenMsgCycleTime" INT 0 0;
BA_DEF_ SG_  "GenSigSendType" ENUM  "Cyclic","OnChange","OnWrite","IfActive","OnChangeWithRepetition","OnWriteWithRepetition","IfActiveWithRepetition","NoSigSendType","OnChangeAndIfActive","OnChangeAndIfActiveWithRepetition","CA","CE","Event";
BA_DEF_ SG_  "GenSigStartValue" INT 0 0;
BA_DEF_ BO_  "GenMsgCycleTimeFast" INT 0 0;
BA_DEF_ BO_  "GenMsgNrOfRepetition" INT 0 0;
BA_DEF_ BO_  "GenMsgDelayTime" INT 0 0;
BA_DEF_  "DBName" STRING ;
BA_DEF_ BO_  "CANFD_BRS" ENUM  "0","1";
BA_DEF_ BO_  "VFrameFormat" ENUM  "StandardCAN","ExtendedCAN","reserved","reserved","reserved","reserved","reserved","reserved","reserved","reserved","reserved","reserved","reserved","reserved","StandardCAN_FD","ExtendedCAN_FD";
BA_DEF_  "NmMessageCount" INT 0 255;
BA_DEF_ BO_  "GenMsgILSupport" ENUM  "No","Yes";
BA_DEF_  "NmBaseAddress" HEX 1024 1087;
BA_DEF_  "BusType" STRING ;
BA_DEF_ SG_ "GenSigASIL" ENUM "QM","A","B","C","D","";
BA_DEF_DEF_  "GenMsgSendType" "Cyclic";
BA_DEF_DEF_  "GenMsgCycleTime" 0;
BA_DEF_DEF_  "GenSigSendType" "Cyclic";
BA_DEF_DEF_  "GenSigStartValue" 0;
BA_DEF_DEF_  "GenMsgCycleTimeFast" 0;
BA_DEF_DEF_  "GenMsgNrOfRepetition" 0;
BA_DEF_DEF_  "GenMsgDelayTime" 0;
BA_DEF_DEF_  "DBName" "";
BA_DEF_DEF_  "CANFD_BRS" "1";
BA_DEF_DEF_  "VFrameFormat" "StandardCAN_FD";
BA_DEF_DEF_  "NmMessageCount" 128;
BA_DEF_DEF_  "GenMsgILSupport" "No";
BA_DEF_DEF_  "NmBaseAddress" 1024;
BA_DEF_DEF_  "BusType" "CAN FD";
BA_DEF_DEF_ "GenSigASIL" "QM";
BA_ "DBName" "E0X Project FCM_FM(EEA5.1) Message list  V3.12 Draft _202410281027";
BA_ "GenMsgILSupport" BO_ 1301 1;
BA_ "GenMsgCycleTime" BO_ 1301 500;
BA_ "GenMsgCycleTimeFast" BO_ 1301 20;
BA_ "GenMsgNrOfRepetition" BO_ 1301 1;
BA_ "GenMsgDelayTime" BO_ 1301 5;
BA_ "GenSigASIL"  SG_ 1301 TimeSync_Type 5;
BA_ "GenSigASIL"  SG_ 1301 TimeSync_CRC 5;
BA_ "GenSigASIL"  SG_ 1301 TimeSync_SequenceCounter 5;
BA_ "GenSigASIL"  SG_ 1301 TimeSync_TimeDomain 5;
BA_ "GenSigASIL"  SG_ 1301 TimeSync_UserByte0 5;
BA_ "GenSigASIL"  SG_ 1301 TimeSync_SyncTimeSec 5;
BA_ "GenSigASIL"  SG_ 1301 TimeSync_OverflowOfSeconds 5;
BA_ "GenSigASIL"  SG_ 1301 TimeSync_SGW 5;
BA_ "GenSigASIL"  SG_ 1301 TimeSync_Reserved0 5;
BA_ "GenSigASIL"  SG_ 1301 TimeSync_SyncTimeNSec 5;
BA_ "GenMsgILSupport" BO_ 1304 1;
BA_ "GenMsgCycleTime" BO_ 1304 500;
BA_ "GenMsgCycleTimeFast" BO_ 1304 20;
BA_ "GenMsgNrOfRepetition" BO_ 1304 1;
BA_ "GenMsgDelayTime" BO_ 1304 5;
BA_ "GenSigASIL"  SG_ 1304 TimeSync_Type 5;
BA_ "GenSigASIL"  SG_ 1304 TimeSync_CRC 5;
BA_ "GenSigASIL"  SG_ 1304 TimeSync_SequenceCounter 5;
BA_ "GenSigASIL"  SG_ 1304 TimeSync_TimeDomain 5;
BA_ "GenSigASIL"  SG_ 1304 TimeSync_UserByte0 5;
BA_ "GenSigASIL"  SG_ 1304 TimeSync_SyncTimeSec 5;
BA_ "GenSigASIL"  SG_ 1304 TimeSync_OverflowOfSeconds 5;
BA_ "GenSigASIL"  SG_ 1304 TimeSync_SGW 5;
BA_ "GenSigASIL"  SG_ 1304 TimeSync_Reserved0 5;
BA_ "GenSigASIL"  SG_ 1304 TimeSync_SyncTimeNSec 5;
BA_ "GenMsgILSupport" BO_ 960 1;
BA_ "GenMsgCycleTime" BO_ 960 50;
BA_ "GenSigASIL"  SG_ 960 FRM_1_CRC 5;
BA_ "GenSigASIL"  SG_ 960 FRM_1_RollgCntr 5;
BA_ "GenSigASIL"  SG_ 960 FRM_1_ObjHd_ObjBlockCounter 2;
BA_ "GenSigASIL"  SG_ 960 FRM_1_ObjHd_MountPosX 2;
BA_ "GenSigStartValue" SG_ 960 FRM_1_ObjHd_MountPosY 250;
BA_ "GenSigASIL"  SG_ 960 FRM_1_ObjHd_MountPosY 2;
BA_ "GenSigASIL"  SG_ 960 FRM_1_ObjHd_MountPosZ 2;
BA_ "GenSigStartValue" SG_ 960 FRM_1_ObjHd_MountAngleYaw 150;
BA_ "GenSigASIL"  SG_ 960 FRM_1_ObjHd_MountAngleYaw 2;
BA_ "GenSigStartValue" SG_ 960 FRM_1_ObjHd_MountAnglePitch 150;
BA_ "GenSigASIL"  SG_ 960 FRM_1_ObjHd_MountAnglePitch 2;
BA_ "GenSigStartValue" SG_ 960 FRM_1_ObjHd_MountAngleRoll 150;
BA_ "GenSigASIL"  SG_ 960 FRM_1_ObjHd_MountAngleRoll 2;
BA_ "GenSigStartValue" SG_ 960 FRM_1_ObjHd_AlignAglYawErrCurr 150;
BA_ "GenSigASIL"  SG_ 960 FRM_1_ObjHd_AlignAglYawErrCurr 2;
BA_ "GenSigStartValue" SG_ 960 FRM_1_ObjHd_AlignAglYawErrEOL 150;
BA_ "GenSigASIL"  SG_ 960 FRM_1_ObjHd_AlignAglYawErrEOL 2;
BA_ "GenSigStartValue" SG_ 960 FRM_1_ObjHd_AlignAglPitchErrEOL 150;
BA_ "GenSigASIL"  SG_ 960 FRM_1_ObjHd_AlignAglPitchErrEOL 2;
BA_ "GenSigStartValue" SG_ 960 FRM_1_ObjHd_FOVYawAglLower 900;
BA_ "GenSigASIL"  SG_ 960 FRM_1_ObjHd_FOVYawAglLower 2;
BA_ "GenSigStartValue" SG_ 960 FRM_1_ObjHd_FOVYawAglUpper 900;
BA_ "GenSigASIL"  SG_ 960 FRM_1_ObjHd_FOVYawAglUpper 2;
BA_ "GenSigStartValue" SG_ 960 FRM_1_ObjHd_FOVPitchAglLower 400;
BA_ "GenSigASIL"  SG_ 960 FRM_1_ObjHd_FOVPitchAglLower 2;
BA_ "GenSigStartValue" SG_ 960 FRM_1_ObjHd_FOVPitchAglUpper 400;
BA_ "GenSigASIL"  SG_ 960 FRM_1_ObjHd_FOVPitchAglUpper 2;
BA_ "GenSigASIL"  SG_ 960 FRM_1_ObjHd_MaxDetectionRange 2;
BA_ "GenSigASIL"  SG_ 960 FRM_1_ObjHd_ObjDetFail 2;
BA_ "GenSigASIL"  SG_ 960 FRM_1_ObjHd_ValidObjCount 2;
BA_ "GenSigASIL"  SG_ 960 FRM_1_ObjHd_ObjDownSel 2;
BA_ "GenSigASIL"  SG_ 960 FRM_1_ObjHd_ObjTimeLatency 2;
BA_ "GenMsgILSupport" BO_ 961 1;
BA_ "GenMsgCycleTime" BO_ 961 50;
BA_ "GenSigASIL"  SG_ 961 FRM_2_CRC 5;
BA_ "GenSigASIL"  SG_ 961 FRM_2_RollgCntr 5;
BA_ "GenSigASIL"  SG_ 961 FRM_2_DetnHd_DetnBlockCounter 2;
BA_ "GenSigASIL"  SG_ 961 FRM_2_DetnHd_MountPosX 2;
BA_ "GenSigStartValue" SG_ 961 FRM_2_DetnHd_MountPosY 250;
BA_ "GenSigASIL"  SG_ 961 FRM_2_DetnHd_MountPosY 2;
BA_ "GenSigASIL"  SG_ 961 FRM_2_DetnHd_MountPosZ 2;
BA_ "GenSigStartValue" SG_ 961 FRM_2_DetnHd_MountAngleYaw 150;
BA_ "GenSigASIL"  SG_ 961 FRM_2_DetnHd_MountAngleYaw 2;
BA_ "GenSigStartValue" SG_ 961 FRM_2_DetnHd_MountAnglePitch 150;
BA_ "GenSigASIL"  SG_ 961 FRM_2_DetnHd_MountAnglePitch 2;
BA_ "GenSigStartValue" SG_ 961 FRM_2_DetnHd_MountAngleRoll 150;
BA_ "GenSigASIL"  SG_ 961 FRM_2_DetnHd_MountAngleRoll 2;
BA_ "GenSigStartValue" SG_ 961 FRM_2_DetnHd_AlignAglYawErrCurr 150;
BA_ "GenSigASIL"  SG_ 961 FRM_2_DetnHd_AlignAglYawErrCurr 2;
BA_ "GenSigStartValue" SG_ 961 FRM_2_DetnHd_AlignAglYawErrEOL 150;
BA_ "GenSigASIL"  SG_ 961 FRM_2_DetnHd_AlignAglYawErrEOL 2;
BA_ "GenSigStartValue" SG_ 961 FRM_2_DetnHd_AlignAglPitchErrEOL 150;
BA_ "GenSigASIL"  SG_ 961 FRM_2_DetnHd_AlignAglPitchErrEOL 2;
BA_ "GenSigStartValue" SG_ 961 FRM_2_DetnHd_FOVYawAglLower 900;
BA_ "GenSigASIL"  SG_ 961 FRM_2_DetnHd_FOVYawAglLower 2;
BA_ "GenSigStartValue" SG_ 961 FRM_2_DetnHd_FOVYawAglUpper 900;
BA_ "GenSigASIL"  SG_ 961 FRM_2_DetnHd_FOVYawAglUpper 2;
BA_ "GenSigStartValue" SG_ 961 FRM_2_DetnHd_FOVPitchAglLower 400;
BA_ "GenSigASIL"  SG_ 961 FRM_2_DetnHd_FOVPitchAglLower 2;
BA_ "GenSigStartValue" SG_ 961 FRM_2_DetnHd_FOVPitchAglUpper 400;
BA_ "GenSigASIL"  SG_ 961 FRM_2_DetnHd_FOVPitchAglUpper 2;
BA_ "GenSigASIL"  SG_ 961 FRM_2_DetnHd_MaxDetectionRange 2;
BA_ "GenSigASIL"  SG_ 961 FRM_2_DetnHd_ObjDetFail 2;
BA_ "GenSigASIL"  SG_ 961 FRM_2_DetnHd_ValidDetnCount 2;
BA_ "GenSigASIL"  SG_ 961 FRM_2_DetnHd_DetnDownSel 2;
BA_ "GenSigASIL"  SG_ 961 FRM_2_DetnHd_DetnTimeLatency 2;
BA_ "GenMsgILSupport" BO_ 962 1;
BA_ "GenMsgCycleTime" BO_ 962 50;
BA_ "GenSigASIL"  SG_ 962 FRM_3_CRC 5;
BA_ "GenSigASIL"  SG_ 962 FRM_3_RollgCntr 5;
BA_ "GenSigASIL"  SG_ 962 FRM_3_ObjBlockCounter 2;
BA_ "GenSigASIL"  SG_ 962 FRM_3_ObjID_00 2;
BA_ "GenSigASIL"  SG_ 962 FRM_3_ObjClosestDistX_00 2;
BA_ "GenSigStartValue" SG_ 962 FRM_3_ObjClosestDistY_00 10000;
BA_ "GenSigASIL"  SG_ 962 FRM_3_ObjClosestDistY_00 2;
BA_ "GenSigStartValue" SG_ 962 FRM_3_ObjRelVelX_00 10000;
BA_ "GenSigASIL"  SG_ 962 FRM_3_ObjRelVelX_00 2;
BA_ "GenSigStartValue" SG_ 962 FRM_3_ObjRelVelY_00 10000;
BA_ "GenSigASIL"  SG_ 962 FRM_3_ObjRelVelY_00 2;
BA_ "GenSigStartValue" SG_ 962 FRM_3_ObjAccelX_00 2500;
BA_ "GenSigASIL"  SG_ 962 FRM_3_ObjAccelX_00 2;
BA_ "GenSigStartValue" SG_ 962 FRM_3_ObjAccelY_00 2500;
BA_ "GenSigASIL"  SG_ 962 FRM_3_ObjAccelY_00 2;
BA_ "GenSigASIL"  SG_ 962 FRM_3_ObjClosestDistXStd_00 2;
BA_ "GenSigASIL"  SG_ 962 FRM_3_ObjClosestDistYStd_00 2;
BA_ "GenSigASIL"  SG_ 962 FRM_3_ObjRelVelXStd_00 2;
BA_ "GenSigASIL"  SG_ 962 FRM_3_ObjRelVelYStd_00 2;
BA_ "GenSigASIL"  SG_ 962 FRM_3_ObjRelAccelXStd_00 2;
BA_ "GenSigASIL"  SG_ 962 FRM_3_ObjRelAccelYStd_00 2;
BA_ "GenSigASIL"  SG_ 962 FRM_3_ObjExistProb_00 2;
BA_ "GenSigASIL"  SG_ 962 FRM_3_ObjType_00 2;
BA_ "GenSigASIL"  SG_ 962 FRM_3_ObjTypeConf_00 2;
BA_ "GenSigASIL"  SG_ 962 FRM_3_ObjTrackSts_00 2;
BA_ "GenSigASIL"  SG_ 962 FRM_3_ObjMotionSts_00 2;
BA_ "GenSigASIL"  SG_ 962 FRM_3_ObjMotionDirection_00 2;
BA_ "GenSigASIL"  SG_ 962 FRM_3_ObjCenterDistX_00 2;
BA_ "GenSigStartValue" SG_ 962 FRM_3_ObjCenterDistY_00 10000;
BA_ "GenSigASIL"  SG_ 962 FRM_3_ObjCenterDistY_00 2;
BA_ "GenSigASIL"  SG_ 962 FRM_3_ObjLength_00 2;
BA_ "GenSigASIL"  SG_ 962 FRM_3_ObjWidth_00 2;
BA_ "GenSigASIL"  SG_ 962 FRM_3_ObjElevnSts_00 2;
BA_ "GenSigASIL"  SG_ 962 FRM_3_ObjElevnStsConf_00 2;
BA_ "GenSigStartValue" SG_ 962 FRM_3_ObjHeading_00 1800;
BA_ "GenSigASIL"  SG_ 962 FRM_3_ObjHeading_00 2;
BA_ "GenSigASIL"  SG_ 962 FRM_3_ObjID_01 2;
BA_ "GenSigASIL"  SG_ 962 FRM_3_ObjClosestDistX_01 2;
BA_ "GenSigStartValue" SG_ 962 FRM_3_ObjClosestDistY_01 10000;
BA_ "GenSigASIL"  SG_ 962 FRM_3_ObjClosestDistY_01 2;
BA_ "GenSigStartValue" SG_ 962 FRM_3_ObjRelVelX_01 10000;
BA_ "GenSigASIL"  SG_ 962 FRM_3_ObjRelVelX_01 2;
BA_ "GenSigStartValue" SG_ 962 FRM_3_ObjRelVelY_01 10000;
BA_ "GenSigASIL"  SG_ 962 FRM_3_ObjRelVelY_01 2;
BA_ "GenSigStartValue" SG_ 962 FRM_3_ObjAccelX_01 2500;
BA_ "GenSigASIL"  SG_ 962 FRM_3_ObjAccelX_01 2;
BA_ "GenSigStartValue" SG_ 962 FRM_3_ObjAccelY_01 2500;
BA_ "GenSigASIL"  SG_ 962 FRM_3_ObjAccelY_01 2;
BA_ "GenSigASIL"  SG_ 962 FRM_3_ObjClosestDistXStd_01 2;
BA_ "GenSigASIL"  SG_ 962 FRM_3_ObjClosestDistYStd_01 2;
BA_ "GenSigASIL"  SG_ 962 FRM_3_ObjRelVelXStd_01 2;
BA_ "GenSigASIL"  SG_ 962 FRM_3_ObjRelVelYStd_01 2;
BA_ "GenSigASIL"  SG_ 962 FRM_3_ObjRelAccelXStd_01 2;
BA_ "GenSigASIL"  SG_ 962 FRM_3_ObjRelAccelYStd_01 2;
BA_ "GenSigASIL"  SG_ 962 FRM_3_ObjExistProb_01 2;
BA_ "GenSigASIL"  SG_ 962 FRM_3_ObjType_01 2;
BA_ "GenSigASIL"  SG_ 962 FRM_3_ObjTypeConf_01 2;
BA_ "GenSigASIL"  SG_ 962 FRM_3_ObjTrackSts_01 2;
BA_ "GenSigASIL"  SG_ 962 FRM_3_ObjMotionSts_01 2;
BA_ "GenSigASIL"  SG_ 962 FRM_3_ObjMotionDirection_01 2;
BA_ "GenSigASIL"  SG_ 962 FRM_3_ObjCenterDistX_01 2;
BA_ "GenSigStartValue" SG_ 962 FRM_3_ObjCenterDistY_01 10000;
BA_ "GenSigASIL"  SG_ 962 FRM_3_ObjCenterDistY_01 2;
BA_ "GenSigASIL"  SG_ 962 FRM_3_ObjLength_01 2;
BA_ "GenSigASIL"  SG_ 962 FRM_3_ObjWidth_01 2;
BA_ "GenSigASIL"  SG_ 962 FRM_3_ObjElevnSts_01 2;
BA_ "GenSigASIL"  SG_ 962 FRM_3_ObjElevnStsConf_01 2;
BA_ "GenSigStartValue" SG_ 962 FRM_3_ObjHeading_01 1800;
BA_ "GenSigASIL"  SG_ 962 FRM_3_ObjHeading_01 2;
BA_ "GenMsgILSupport" BO_ 963 1;
BA_ "GenMsgCycleTime" BO_ 963 50;
BA_ "GenSigASIL"  SG_ 963 FRM_4_CRC 5;
BA_ "GenSigASIL"  SG_ 963 FRM_4_RollgCntr 5;
BA_ "GenSigASIL"  SG_ 963 FRM_4_ObjBlockCounter 2;
BA_ "GenSigASIL"  SG_ 963 FRM_4_ObjID_02 2;
BA_ "GenSigASIL"  SG_ 963 FRM_4_ObjClosestDistX_02 2;
BA_ "GenSigStartValue" SG_ 963 FRM_4_ObjClosestDistY_02 10000;
BA_ "GenSigASIL"  SG_ 963 FRM_4_ObjClosestDistY_02 2;
BA_ "GenSigStartValue" SG_ 963 FRM_4_ObjRelVelX_02 10000;
BA_ "GenSigASIL"  SG_ 963 FRM_4_ObjRelVelX_02 2;
BA_ "GenSigStartValue" SG_ 963 FRM_4_ObjRelVelY_02 10000;
BA_ "GenSigASIL"  SG_ 963 FRM_4_ObjRelVelY_02 2;
BA_ "GenSigStartValue" SG_ 963 FRM_4_ObjAccelX_02 2500;
BA_ "GenSigASIL"  SG_ 963 FRM_4_ObjAccelX_02 2;
BA_ "GenSigStartValue" SG_ 963 FRM_4_ObjAccelY_02 2500;
BA_ "GenSigASIL"  SG_ 963 FRM_4_ObjAccelY_02 2;
BA_ "GenSigASIL"  SG_ 963 FRM_4_ObjClosestDistXStd_02 2;
BA_ "GenSigASIL"  SG_ 963 FRM_4_ObjClosestDistYStd_02 2;
BA_ "GenSigASIL"  SG_ 963 FRM_4_ObjRelVelXStd_02 2;
BA_ "GenSigASIL"  SG_ 963 FRM_4_ObjRelVelYStd_02 2;
BA_ "GenSigASIL"  SG_ 963 FRM_4_ObjRelAccelXStd_02 2;
BA_ "GenSigASIL"  SG_ 963 FRM_4_ObjRelAccelYStd_02 2;
BA_ "GenSigASIL"  SG_ 963 FRM_4_ObjExistProb_02 2;
BA_ "GenSigASIL"  SG_ 963 FRM_4_ObjType_02 2;
BA_ "GenSigASIL"  SG_ 963 FRM_4_ObjTypeConf_02 2;
BA_ "GenSigASIL"  SG_ 963 FRM_4_ObjTrackSts_02 2;
BA_ "GenSigASIL"  SG_ 963 FRM_4_ObjMotionSts_02 2;
BA_ "GenSigASIL"  SG_ 963 FRM_4_ObjMotionDirection_02 2;
BA_ "GenSigASIL"  SG_ 963 FRM_4_ObjCenterDistX_02 2;
BA_ "GenSigStartValue" SG_ 963 FRM_4_ObjCenterDistY_02 10000;
BA_ "GenSigASIL"  SG_ 963 FRM_4_ObjCenterDistY_02 2;
BA_ "GenSigASIL"  SG_ 963 FRM_4_ObjLength_02 2;
BA_ "GenSigASIL"  SG_ 963 FRM_4_ObjWidth_02 2;
BA_ "GenSigASIL"  SG_ 963 FRM_4_ObjElevnSts_02 2;
BA_ "GenSigASIL"  SG_ 963 FRM_4_ObjElevnStsConf_02 2;
BA_ "GenSigStartValue" SG_ 963 FRM_4_ObjHeading_02 1800;
BA_ "GenSigASIL"  SG_ 963 FRM_4_ObjHeading_02 2;
BA_ "GenSigASIL"  SG_ 963 FRM_4_ObjID_03 2;
BA_ "GenSigASIL"  SG_ 963 FRM_4_ObjClosestDistX_03 2;
BA_ "GenSigStartValue" SG_ 963 FRM_4_ObjClosestDistY_03 10000;
BA_ "GenSigASIL"  SG_ 963 FRM_4_ObjClosestDistY_03 2;
BA_ "GenSigStartValue" SG_ 963 FRM_4_ObjRelVelX_03 10000;
BA_ "GenSigASIL"  SG_ 963 FRM_4_ObjRelVelX_03 2;
BA_ "GenSigStartValue" SG_ 963 FRM_4_ObjRelVelY_03 10000;
BA_ "GenSigASIL"  SG_ 963 FRM_4_ObjRelVelY_03 2;
BA_ "GenSigStartValue" SG_ 963 FRM_4_ObjAccelX_03 2500;
BA_ "GenSigASIL"  SG_ 963 FRM_4_ObjAccelX_03 2;
BA_ "GenSigStartValue" SG_ 963 FRM_4_ObjAccelY_03 2500;
BA_ "GenSigASIL"  SG_ 963 FRM_4_ObjAccelY_03 2;
BA_ "GenSigASIL"  SG_ 963 FRM_4_ObjClosestDistXStd_03 2;
BA_ "GenSigASIL"  SG_ 963 FRM_4_ObjClosestDistYStd_03 2;
BA_ "GenSigASIL"  SG_ 963 FRM_4_ObjRelVelXStd_03 2;
BA_ "GenSigASIL"  SG_ 963 FRM_4_ObjRelVelYStd_03 2;
BA_ "GenSigASIL"  SG_ 963 FRM_4_ObjRelAccelXStd_03 2;
BA_ "GenSigASIL"  SG_ 963 FRM_4_ObjRelAccelYStd_03 2;
BA_ "GenSigASIL"  SG_ 963 FRM_4_ObjExistProb_03 2;
BA_ "GenSigASIL"  SG_ 963 FRM_4_ObjType_03 2;
BA_ "GenSigASIL"  SG_ 963 FRM_4_ObjTypeConf_03 2;
BA_ "GenSigASIL"  SG_ 963 FRM_4_ObjTrackSts_03 2;
BA_ "GenSigASIL"  SG_ 963 FRM_4_ObjMotionSts_03 2;
BA_ "GenSigASIL"  SG_ 963 FRM_4_ObjMotionDirection_03 2;
BA_ "GenSigASIL"  SG_ 963 FRM_4_ObjCenterDistX_03 2;
BA_ "GenSigStartValue" SG_ 963 FRM_4_ObjCenterDistY_03 10000;
BA_ "GenSigASIL"  SG_ 963 FRM_4_ObjCenterDistY_03 2;
BA_ "GenSigASIL"  SG_ 963 FRM_4_ObjLength_03 2;
BA_ "GenSigASIL"  SG_ 963 FRM_4_ObjWidth_03 2;
BA_ "GenSigASIL"  SG_ 963 FRM_4_ObjElevnSts_03 2;
BA_ "GenSigASIL"  SG_ 963 FRM_4_ObjElevnStsConf_03 2;
BA_ "GenSigStartValue" SG_ 963 FRM_4_ObjHeading_03 1800;
BA_ "GenSigASIL"  SG_ 963 FRM_4_ObjHeading_03 2;
BA_ "GenMsgILSupport" BO_ 964 1;
BA_ "GenMsgCycleTime" BO_ 964 50;
BA_ "GenSigASIL"  SG_ 964 FRM_5_CRC 5;
BA_ "GenSigASIL"  SG_ 964 FRM_5_RollgCntr 5;
BA_ "GenSigASIL"  SG_ 964 FRM_5_ObjBlockCounter 2;
BA_ "GenSigASIL"  SG_ 964 FRM_5_ObjID_04 2;
BA_ "GenSigASIL"  SG_ 964 FRM_5_ObjClosestDistX_04 2;
BA_ "GenSigStartValue" SG_ 964 FRM_5_ObjClosestDistY_04 10000;
BA_ "GenSigASIL"  SG_ 964 FRM_5_ObjClosestDistY_04 2;
BA_ "GenSigStartValue" SG_ 964 FRM_5_ObjRelVelX_04 10000;
BA_ "GenSigASIL"  SG_ 964 FRM_5_ObjRelVelX_04 2;
BA_ "GenSigStartValue" SG_ 964 FRM_5_ObjRelVelY_04 10000;
BA_ "GenSigASIL"  SG_ 964 FRM_5_ObjRelVelY_04 2;
BA_ "GenSigStartValue" SG_ 964 FRM_5_ObjAccelX_04 2500;
BA_ "GenSigASIL"  SG_ 964 FRM_5_ObjAccelX_04 2;
BA_ "GenSigStartValue" SG_ 964 FRM_5_ObjAccelY_04 2500;
BA_ "GenSigASIL"  SG_ 964 FRM_5_ObjAccelY_04 2;
BA_ "GenSigASIL"  SG_ 964 FRM_5_ObjClosestDistXStd_04 2;
BA_ "GenSigASIL"  SG_ 964 FRM_5_ObjClosestDistYStd_04 2;
BA_ "GenSigASIL"  SG_ 964 FRM_5_ObjRelVelXStd_04 2;
BA_ "GenSigASIL"  SG_ 964 FRM_5_ObjRelVelYStd_04 2;
BA_ "GenSigASIL"  SG_ 964 FRM_5_ObjRelAccelXStd_04 2;
BA_ "GenSigASIL"  SG_ 964 FRM_5_ObjRelAccelYStd_04 2;
BA_ "GenSigASIL"  SG_ 964 FRM_5_ObjExistProb_04 2;
BA_ "GenSigASIL"  SG_ 964 FRM_5_ObjType_04 2;
BA_ "GenSigASIL"  SG_ 964 FRM_5_ObjTypeConf_04 2;
BA_ "GenSigASIL"  SG_ 964 FRM_5_ObjTrackSts_04 2;
BA_ "GenSigASIL"  SG_ 964 FRM_5_ObjMotionSts_04 2;
BA_ "GenSigASIL"  SG_ 964 FRM_5_ObjMotionDirection_04 2;
BA_ "GenSigASIL"  SG_ 964 FRM_5_ObjCenterDistX_04 2;
BA_ "GenSigStartValue" SG_ 964 FRM_5_ObjCenterDistY_04 10000;
BA_ "GenSigASIL"  SG_ 964 FRM_5_ObjCenterDistY_04 2;
BA_ "GenSigASIL"  SG_ 964 FRM_5_ObjLength_04 2;
BA_ "GenSigASIL"  SG_ 964 FRM_5_ObjWidth_04 2;
BA_ "GenSigASIL"  SG_ 964 FRM_5_ObjElevnSts_04 2;
BA_ "GenSigASIL"  SG_ 964 FRM_5_ObjElevnStsConf_04 2;
BA_ "GenSigStartValue" SG_ 964 FRM_5_ObjHeading_04 1800;
BA_ "GenSigASIL"  SG_ 964 FRM_5_ObjHeading_04 2;
BA_ "GenSigASIL"  SG_ 964 FRM_5_ObjID_05 2;
BA_ "GenSigASIL"  SG_ 964 FRM_5_ObjClosestDistX_05 2;
BA_ "GenSigStartValue" SG_ 964 FRM_5_ObjClosestDistY_05 10000;
BA_ "GenSigASIL"  SG_ 964 FRM_5_ObjClosestDistY_05 2;
BA_ "GenSigStartValue" SG_ 964 FRM_5_ObjRelVelX_05 10000;
BA_ "GenSigASIL"  SG_ 964 FRM_5_ObjRelVelX_05 2;
BA_ "GenSigStartValue" SG_ 964 FRM_5_ObjRelVelY_05 10000;
BA_ "GenSigASIL"  SG_ 964 FRM_5_ObjRelVelY_05 2;
BA_ "GenSigStartValue" SG_ 964 FRM_5_ObjAccelX_05 2500;
BA_ "GenSigASIL"  SG_ 964 FRM_5_ObjAccelX_05 2;
BA_ "GenSigStartValue" SG_ 964 FRM_5_ObjAccelY_05 2500;
BA_ "GenSigASIL"  SG_ 964 FRM_5_ObjAccelY_05 2;
BA_ "GenSigASIL"  SG_ 964 FRM_5_ObjClosestDistXStd_05 2;
BA_ "GenSigASIL"  SG_ 964 FRM_5_ObjClosestDistYStd_05 2;
BA_ "GenSigASIL"  SG_ 964 FRM_5_ObjRelVelXStd_05 2;
BA_ "GenSigASIL"  SG_ 964 FRM_5_ObjRelVelYStd_05 2;
BA_ "GenSigASIL"  SG_ 964 FRM_5_ObjRelAccelXStd_05 2;
BA_ "GenSigASIL"  SG_ 964 FRM_5_ObjRelAccelYStd_05 2;
BA_ "GenSigASIL"  SG_ 964 FRM_5_ObjExistProb_05 2;
BA_ "GenSigASIL"  SG_ 964 FRM_5_ObjType_05 2;
BA_ "GenSigASIL"  SG_ 964 FRM_5_ObjTypeConf_05 2;
BA_ "GenSigASIL"  SG_ 964 FRM_5_ObjTrackSts_05 2;
BA_ "GenSigASIL"  SG_ 964 FRM_5_ObjMotionSts_05 2;
BA_ "GenSigASIL"  SG_ 964 FRM_5_ObjMotionDirection_05 2;
BA_ "GenSigASIL"  SG_ 964 FRM_5_ObjCenterDistX_05 2;
BA_ "GenSigStartValue" SG_ 964 FRM_5_ObjCenterDistY_05 10000;
BA_ "GenSigASIL"  SG_ 964 FRM_5_ObjCenterDistY_05 2;
BA_ "GenSigASIL"  SG_ 964 FRM_5_ObjLength_05 2;
BA_ "GenSigASIL"  SG_ 964 FRM_5_ObjWidth_05 2;
BA_ "GenSigASIL"  SG_ 964 FRM_5_ObjElevnSts_05 2;
BA_ "GenSigASIL"  SG_ 964 FRM_5_ObjElevnStsConf_05 2;
BA_ "GenSigStartValue" SG_ 964 FRM_5_ObjHeading_05 1800;
BA_ "GenSigASIL"  SG_ 964 FRM_5_ObjHeading_05 2;
BA_ "GenMsgILSupport" BO_ 965 1;
BA_ "GenMsgCycleTime" BO_ 965 50;
BA_ "GenSigASIL"  SG_ 965 FRM_6_CRC 5;
BA_ "GenSigASIL"  SG_ 965 FRM_6_RollgCntr 5;
BA_ "GenSigASIL"  SG_ 965 FRM_6_ObjBlockCounter 2;
BA_ "GenSigASIL"  SG_ 965 FRM_6_ObjID_06 2;
BA_ "GenSigASIL"  SG_ 965 FRM_6_ObjClosestDistX_06 2;
BA_ "GenSigStartValue" SG_ 965 FRM_6_ObjClosestDistY_06 10000;
BA_ "GenSigASIL"  SG_ 965 FRM_6_ObjClosestDistY_06 2;
BA_ "GenSigStartValue" SG_ 965 FRM_6_ObjRelVelX_06 10000;
BA_ "GenSigASIL"  SG_ 965 FRM_6_ObjRelVelX_06 2;
BA_ "GenSigStartValue" SG_ 965 FRM_6_ObjRelVelY_06 10000;
BA_ "GenSigASIL"  SG_ 965 FRM_6_ObjRelVelY_06 2;
BA_ "GenSigStartValue" SG_ 965 FRM_6_ObjAccelX_06 2500;
BA_ "GenSigASIL"  SG_ 965 FRM_6_ObjAccelX_06 2;
BA_ "GenSigStartValue" SG_ 965 FRM_6_ObjAccelY_06 2500;
BA_ "GenSigASIL"  SG_ 965 FRM_6_ObjAccelY_06 2;
BA_ "GenSigASIL"  SG_ 965 FRM_6_ObjClosestDistXStd_06 2;
BA_ "GenSigASIL"  SG_ 965 FRM_6_ObjClosestDistYStd_06 2;
BA_ "GenSigASIL"  SG_ 965 FRM_6_ObjRelVelXStd_06 2;
BA_ "GenSigASIL"  SG_ 965 FRM_6_ObjRelVelYStd_06 2;
BA_ "GenSigASIL"  SG_ 965 FRM_6_ObjRelAccelXStd_06 2;
BA_ "GenSigASIL"  SG_ 965 FRM_6_ObjRelAccelYStd_06 2;
BA_ "GenSigASIL"  SG_ 965 FRM_6_ObjExistProb_06 2;
BA_ "GenSigASIL"  SG_ 965 FRM_6_ObjType_06 2;
BA_ "GenSigASIL"  SG_ 965 FRM_6_ObjTypeConf_06 2;
BA_ "GenSigASIL"  SG_ 965 FRM_6_ObjTrackSts_06 2;
BA_ "GenSigASIL"  SG_ 965 FRM_6_ObjMotionSts_06 2;
BA_ "GenSigASIL"  SG_ 965 FRM_6_ObjMotionDirection_06 2;
BA_ "GenSigASIL"  SG_ 965 FRM_6_ObjCenterDistX_06 2;
BA_ "GenSigStartValue" SG_ 965 FRM_6_ObjCenterDistY_06 10000;
BA_ "GenSigASIL"  SG_ 965 FRM_6_ObjCenterDistY_06 2;
BA_ "GenSigASIL"  SG_ 965 FRM_6_ObjLength_06 2;
BA_ "GenSigASIL"  SG_ 965 FRM_6_ObjWidth_06 2;
BA_ "GenSigASIL"  SG_ 965 FRM_6_ObjElevnSts_06 2;
BA_ "GenSigASIL"  SG_ 965 FRM_6_ObjElevnStsConf_06 2;
BA_ "GenSigStartValue" SG_ 965 FRM_6_ObjHeading_06 1800;
BA_ "GenSigASIL"  SG_ 965 FRM_6_ObjHeading_06 2;
BA_ "GenSigASIL"  SG_ 965 FRM_6_ObjID_07 2;
BA_ "GenSigASIL"  SG_ 965 FRM_6_ObjClosestDistX_07 2;
BA_ "GenSigStartValue" SG_ 965 FRM_6_ObjClosestDistY_07 10000;
BA_ "GenSigASIL"  SG_ 965 FRM_6_ObjClosestDistY_07 2;
BA_ "GenSigStartValue" SG_ 965 FRM_6_ObjRelVelX_07 10000;
BA_ "GenSigASIL"  SG_ 965 FRM_6_ObjRelVelX_07 2;
BA_ "GenSigStartValue" SG_ 965 FRM_6_ObjRelVelY_07 10000;
BA_ "GenSigASIL"  SG_ 965 FRM_6_ObjRelVelY_07 2;
BA_ "GenSigStartValue" SG_ 965 FRM_6_ObjAccelX_07 2500;
BA_ "GenSigASIL"  SG_ 965 FRM_6_ObjAccelX_07 2;
BA_ "GenSigStartValue" SG_ 965 FRM_6_ObjAccelY_07 2500;
BA_ "GenSigASIL"  SG_ 965 FRM_6_ObjAccelY_07 2;
BA_ "GenSigASIL"  SG_ 965 FRM_6_ObjClosestDistXStd_07 2;
BA_ "GenSigASIL"  SG_ 965 FRM_6_ObjClosestDistYStd_07 2;
BA_ "GenSigASIL"  SG_ 965 FRM_6_ObjRelVelXStd_07 2;
BA_ "GenSigASIL"  SG_ 965 FRM_6_ObjRelVelYStd_07 2;
BA_ "GenSigASIL"  SG_ 965 FRM_6_ObjRelAccelXStd_07 2;
BA_ "GenSigASIL"  SG_ 965 FRM_6_ObjRelAccelYStd_07 2;
BA_ "GenSigASIL"  SG_ 965 FRM_6_ObjExistProb_07 2;
BA_ "GenSigASIL"  SG_ 965 FRM_6_ObjType_07 2;
BA_ "GenSigASIL"  SG_ 965 FRM_6_ObjTypeConf_07 2;
BA_ "GenSigASIL"  SG_ 965 FRM_6_ObjTrackSts_07 2;
BA_ "GenSigASIL"  SG_ 965 FRM_6_ObjMotionSts_07 2;
BA_ "GenSigASIL"  SG_ 965 FRM_6_ObjMotionDirection_07 2;
BA_ "GenSigASIL"  SG_ 965 FRM_6_ObjCenterDistX_07 2;
BA_ "GenSigStartValue" SG_ 965 FRM_6_ObjCenterDistY_07 10000;
BA_ "GenSigASIL"  SG_ 965 FRM_6_ObjCenterDistY_07 2;
BA_ "GenSigASIL"  SG_ 965 FRM_6_ObjLength_07 2;
BA_ "GenSigASIL"  SG_ 965 FRM_6_ObjWidth_07 2;
BA_ "GenSigASIL"  SG_ 965 FRM_6_ObjElevnSts_07 2;
BA_ "GenSigASIL"  SG_ 965 FRM_6_ObjElevnStsConf_07 2;
BA_ "GenSigStartValue" SG_ 965 FRM_6_ObjHeading_07 1800;
BA_ "GenSigASIL"  SG_ 965 FRM_6_ObjHeading_07 2;
BA_ "GenMsgILSupport" BO_ 966 1;
BA_ "GenMsgCycleTime" BO_ 966 50;
BA_ "GenSigASIL"  SG_ 966 FRM_7_CRC 5;
BA_ "GenSigASIL"  SG_ 966 FRM_7_RollgCntr 5;
BA_ "GenSigASIL"  SG_ 966 FRM_7_ObjBlockCounter 2;
BA_ "GenSigASIL"  SG_ 966 FRM_7_ObjID_08 2;
BA_ "GenSigASIL"  SG_ 966 FRM_7_ObjClosestDistX_08 2;
BA_ "GenSigStartValue" SG_ 966 FRM_7_ObjClosestDistY_08 10000;
BA_ "GenSigASIL"  SG_ 966 FRM_7_ObjClosestDistY_08 2;
BA_ "GenSigStartValue" SG_ 966 FRM_7_ObjRelVelX_08 10000;
BA_ "GenSigASIL"  SG_ 966 FRM_7_ObjRelVelX_08 2;
BA_ "GenSigStartValue" SG_ 966 FRM_7_ObjRelVelY_08 10000;
BA_ "GenSigASIL"  SG_ 966 FRM_7_ObjRelVelY_08 2;
BA_ "GenSigStartValue" SG_ 966 FRM_7_ObjAccelX_08 2500;
BA_ "GenSigASIL"  SG_ 966 FRM_7_ObjAccelX_08 2;
BA_ "GenSigStartValue" SG_ 966 FRM_7_ObjAccelY_08 2500;
BA_ "GenSigASIL"  SG_ 966 FRM_7_ObjAccelY_08 2;
BA_ "GenSigASIL"  SG_ 966 FRM_7_ObjClosestDistXStd_08 2;
BA_ "GenSigASIL"  SG_ 966 FRM_7_ObjClosestDistYStd_08 2;
BA_ "GenSigASIL"  SG_ 966 FRM_7_ObjRelVelXStd_08 2;
BA_ "GenSigASIL"  SG_ 966 FRM_7_ObjRelVelYStd_08 2;
BA_ "GenSigASIL"  SG_ 966 FRM_7_ObjRelAccelXStd_08 2;
BA_ "GenSigASIL"  SG_ 966 FRM_7_ObjRelAccelYStd_08 2;
BA_ "GenSigASIL"  SG_ 966 FRM_7_ObjExistProb_08 2;
BA_ "GenSigASIL"  SG_ 966 FRM_7_ObjType_08 2;
BA_ "GenSigASIL"  SG_ 966 FRM_7_ObjTypeConf_08 2;
BA_ "GenSigASIL"  SG_ 966 FRM_7_ObjTrackSts_08 2;
BA_ "GenSigASIL"  SG_ 966 FRM_7_ObjMotionSts_08 2;
BA_ "GenSigASIL"  SG_ 966 FRM_7_ObjMotionDirection_08 2;
BA_ "GenSigASIL"  SG_ 966 FRM_7_ObjCenterDistX_08 2;
BA_ "GenSigStartValue" SG_ 966 FRM_7_ObjCenterDistY_08 10000;
BA_ "GenSigASIL"  SG_ 966 FRM_7_ObjCenterDistY_08 2;
BA_ "GenSigASIL"  SG_ 966 FRM_7_ObjLength_08 2;
BA_ "GenSigASIL"  SG_ 966 FRM_7_ObjWidth_08 2;
BA_ "GenSigASIL"  SG_ 966 FRM_7_ObjElevnSts_08 2;
BA_ "GenSigASIL"  SG_ 966 FRM_7_ObjElevnStsConf_08 2;
BA_ "GenSigStartValue" SG_ 966 FRM_7_ObjHeading_08 1800;
BA_ "GenSigASIL"  SG_ 966 FRM_7_ObjHeading_08 2;
BA_ "GenSigASIL"  SG_ 966 FRM_7_ObjID_09 2;
BA_ "GenSigASIL"  SG_ 966 FRM_7_ObjClosestDistX_09 2;
BA_ "GenSigStartValue" SG_ 966 FRM_7_ObjClosestDistY_09 10000;
BA_ "GenSigASIL"  SG_ 966 FRM_7_ObjClosestDistY_09 2;
BA_ "GenSigStartValue" SG_ 966 FRM_7_ObjRelVelX_09 10000;
BA_ "GenSigASIL"  SG_ 966 FRM_7_ObjRelVelX_09 2;
BA_ "GenSigStartValue" SG_ 966 FRM_7_ObjRelVelY_09 10000;
BA_ "GenSigASIL"  SG_ 966 FRM_7_ObjRelVelY_09 2;
BA_ "GenSigStartValue" SG_ 966 FRM_7_ObjAccelX_09 2500;
BA_ "GenSigASIL"  SG_ 966 FRM_7_ObjAccelX_09 2;
BA_ "GenSigStartValue" SG_ 966 FRM_7_ObjAccelY_09 2500;
BA_ "GenSigASIL"  SG_ 966 FRM_7_ObjAccelY_09 2;
BA_ "GenSigASIL"  SG_ 966 FRM_7_ObjClosestDistXStd_09 2;
BA_ "GenSigASIL"  SG_ 966 FRM_7_ObjClosestDistYStd_09 2;
BA_ "GenSigASIL"  SG_ 966 FRM_7_ObjRelVelXStd_09 2;
BA_ "GenSigASIL"  SG_ 966 FRM_7_ObjRelVelYStd_09 2;
BA_ "GenSigASIL"  SG_ 966 FRM_7_ObjRelAccelXStd_09 2;
BA_ "GenSigASIL"  SG_ 966 FRM_7_ObjRelAccelYStd_09 2;
BA_ "GenSigASIL"  SG_ 966 FRM_7_ObjExistProb_09 2;
BA_ "GenSigASIL"  SG_ 966 FRM_7_ObjType_09 2;
BA_ "GenSigASIL"  SG_ 966 FRM_7_ObjTypeConf_09 2;
BA_ "GenSigASIL"  SG_ 966 FRM_7_ObjTrackSts_09 2;
BA_ "GenSigASIL"  SG_ 966 FRM_7_ObjMotionSts_09 2;
BA_ "GenSigASIL"  SG_ 966 FRM_7_ObjMotionDirection_09 2;
BA_ "GenSigASIL"  SG_ 966 FRM_7_ObjCenterDistX_09 2;
BA_ "GenSigStartValue" SG_ 966 FRM_7_ObjCenterDistY_09 10000;
BA_ "GenSigASIL"  SG_ 966 FRM_7_ObjCenterDistY_09 2;
BA_ "GenSigASIL"  SG_ 966 FRM_7_ObjLength_09 2;
BA_ "GenSigASIL"  SG_ 966 FRM_7_ObjWidth_09 2;
BA_ "GenSigASIL"  SG_ 966 FRM_7_ObjElevnSts_09 2;
BA_ "GenSigASIL"  SG_ 966 FRM_7_ObjElevnStsConf_09 2;
BA_ "GenSigStartValue" SG_ 966 FRM_7_ObjHeading_09 1800;
BA_ "GenSigASIL"  SG_ 966 FRM_7_ObjHeading_09 2;
BA_ "GenMsgILSupport" BO_ 967 1;
BA_ "GenMsgCycleTime" BO_ 967 50;
BA_ "GenSigASIL"  SG_ 967 FRM_8_CRC 5;
BA_ "GenSigASIL"  SG_ 967 FRM_8_RollgCntr 5;
BA_ "GenSigASIL"  SG_ 967 FRM_8_ObjBlockCounter 2;
BA_ "GenSigASIL"  SG_ 967 FRM_8_ObjID_10 2;
BA_ "GenSigASIL"  SG_ 967 FRM_8_ObjClosestDistX_10 2;
BA_ "GenSigStartValue" SG_ 967 FRM_8_ObjClosestDistY_10 10000;
BA_ "GenSigASIL"  SG_ 967 FRM_8_ObjClosestDistY_10 2;
BA_ "GenSigStartValue" SG_ 967 FRM_8_ObjRelVelX_10 10000;
BA_ "GenSigASIL"  SG_ 967 FRM_8_ObjRelVelX_10 2;
BA_ "GenSigStartValue" SG_ 967 FRM_8_ObjRelVelY_10 10000;
BA_ "GenSigASIL"  SG_ 967 FRM_8_ObjRelVelY_10 2;
BA_ "GenSigStartValue" SG_ 967 FRM_8_ObjAccelX_10 2500;
BA_ "GenSigASIL"  SG_ 967 FRM_8_ObjAccelX_10 2;
BA_ "GenSigStartValue" SG_ 967 FRM_8_ObjAccelY_10 2500;
BA_ "GenSigASIL"  SG_ 967 FRM_8_ObjAccelY_10 2;
BA_ "GenSigASIL"  SG_ 967 FRM_8_ObjClosestDistXStd_10 2;
BA_ "GenSigASIL"  SG_ 967 FRM_8_ObjClosestDistYStd_10 2;
BA_ "GenSigASIL"  SG_ 967 FRM_8_ObjRelVelXStd_10 2;
BA_ "GenSigASIL"  SG_ 967 FRM_8_ObjRelVelYStd_10 2;
BA_ "GenSigASIL"  SG_ 967 FRM_8_ObjRelAccelXStd_10 2;
BA_ "GenSigASIL"  SG_ 967 FRM_8_ObjRelAccelYStd_10 2;
BA_ "GenSigASIL"  SG_ 967 FRM_8_ObjExistProb_10 2;
BA_ "GenSigASIL"  SG_ 967 FRM_8_ObjType_10 2;
BA_ "GenSigASIL"  SG_ 967 FRM_8_ObjTypeConf_10 2;
BA_ "GenSigASIL"  SG_ 967 FRM_8_ObjTrackSts_10 2;
BA_ "GenSigASIL"  SG_ 967 FRM_8_ObjMotionSts_10 2;
BA_ "GenSigASIL"  SG_ 967 FRM_8_ObjMotionDirection_10 2;
BA_ "GenSigASIL"  SG_ 967 FRM_8_ObjCenterDistX_10 2;
BA_ "GenSigStartValue" SG_ 967 FRM_8_ObjCenterDistY_10 10000;
BA_ "GenSigASIL"  SG_ 967 FRM_8_ObjCenterDistY_10 2;
BA_ "GenSigASIL"  SG_ 967 FRM_8_ObjLength_10 2;
BA_ "GenSigASIL"  SG_ 967 FRM_8_ObjWidth_10 2;
BA_ "GenSigASIL"  SG_ 967 FRM_8_ObjElevnSts_10 2;
BA_ "GenSigASIL"  SG_ 967 FRM_8_ObjElevnStsConf_10 2;
BA_ "GenSigStartValue" SG_ 967 FRM_8_ObjHeading_10 1800;
BA_ "GenSigASIL"  SG_ 967 FRM_8_ObjHeading_10 2;
BA_ "GenSigASIL"  SG_ 967 FRM_8_ObjID_11 2;
BA_ "GenSigASIL"  SG_ 967 FRM_8_ObjClosestDistX_11 2;
BA_ "GenSigStartValue" SG_ 967 FRM_8_ObjClosestDistY_11 10000;
BA_ "GenSigASIL"  SG_ 967 FRM_8_ObjClosestDistY_11 2;
BA_ "GenSigStartValue" SG_ 967 FRM_8_ObjRelVelX_11 10000;
BA_ "GenSigASIL"  SG_ 967 FRM_8_ObjRelVelX_11 2;
BA_ "GenSigStartValue" SG_ 967 FRM_8_ObjRelVelY_11 10000;
BA_ "GenSigASIL"  SG_ 967 FRM_8_ObjRelVelY_11 2;
BA_ "GenSigStartValue" SG_ 967 FRM_8_ObjAccelX_11 2500;
BA_ "GenSigASIL"  SG_ 967 FRM_8_ObjAccelX_11 2;
BA_ "GenSigStartValue" SG_ 967 FRM_8_ObjAccelY_11 2500;
BA_ "GenSigASIL"  SG_ 967 FRM_8_ObjAccelY_11 2;
BA_ "GenSigASIL"  SG_ 967 FRM_8_ObjClosestDistXStd_11 2;
BA_ "GenSigASIL"  SG_ 967 FRM_8_ObjClosestDistYStd_11 2;
BA_ "GenSigASIL"  SG_ 967 FRM_8_ObjRelVelXStd_11 2;
BA_ "GenSigASIL"  SG_ 967 FRM_8_ObjRelVelYStd_11 2;
BA_ "GenSigASIL"  SG_ 967 FRM_8_ObjRelAccelXStd_11 2;
BA_ "GenSigASIL"  SG_ 967 FRM_8_ObjRelAccelYStd_11 2;
BA_ "GenSigASIL"  SG_ 967 FRM_8_ObjExistProb_11 2;
BA_ "GenSigASIL"  SG_ 967 FRM_8_ObjType_11 2;
BA_ "GenSigASIL"  SG_ 967 FRM_8_ObjTypeConf_11 2;
BA_ "GenSigASIL"  SG_ 967 FRM_8_ObjTrackSts_11 2;
BA_ "GenSigASIL"  SG_ 967 FRM_8_ObjMotionSts_11 2;
BA_ "GenSigASIL"  SG_ 967 FRM_8_ObjMotionDirection_11 2;
BA_ "GenSigASIL"  SG_ 967 FRM_8_ObjCenterDistX_11 2;
BA_ "GenSigStartValue" SG_ 967 FRM_8_ObjCenterDistY_11 10000;
BA_ "GenSigASIL"  SG_ 967 FRM_8_ObjCenterDistY_11 2;
BA_ "GenSigASIL"  SG_ 967 FRM_8_ObjLength_11 2;
BA_ "GenSigASIL"  SG_ 967 FRM_8_ObjWidth_11 2;
BA_ "GenSigASIL"  SG_ 967 FRM_8_ObjElevnSts_11 2;
BA_ "GenSigASIL"  SG_ 967 FRM_8_ObjElevnStsConf_11 2;
BA_ "GenSigStartValue" SG_ 967 FRM_8_ObjHeading_11 1800;
BA_ "GenSigASIL"  SG_ 967 FRM_8_ObjHeading_11 2;
BA_ "GenMsgILSupport" BO_ 968 1;
BA_ "GenMsgCycleTime" BO_ 968 50;
BA_ "GenSigASIL"  SG_ 968 FRM_9_CRC 5;
BA_ "GenSigASIL"  SG_ 968 FRM_9_RollgCntr 5;
BA_ "GenSigASIL"  SG_ 968 FRM_9_ObjBlockCounter 2;
BA_ "GenSigASIL"  SG_ 968 FRM_9_ObjID_12 2;
BA_ "GenSigASIL"  SG_ 968 FRM_9_ObjClosestDistX_12 2;
BA_ "GenSigStartValue" SG_ 968 FRM_9_ObjClosestDistY_12 10000;
BA_ "GenSigASIL"  SG_ 968 FRM_9_ObjClosestDistY_12 2;
BA_ "GenSigStartValue" SG_ 968 FRM_9_ObjRelVelX_12 10000;
BA_ "GenSigASIL"  SG_ 968 FRM_9_ObjRelVelX_12 2;
BA_ "GenSigStartValue" SG_ 968 FRM_9_ObjRelVelY_12 10000;
BA_ "GenSigASIL"  SG_ 968 FRM_9_ObjRelVelY_12 2;
BA_ "GenSigStartValue" SG_ 968 FRM_9_ObjAccelX_12 2500;
BA_ "GenSigASIL"  SG_ 968 FRM_9_ObjAccelX_12 2;
BA_ "GenSigStartValue" SG_ 968 FRM_9_ObjAccelY_12 2500;
BA_ "GenSigASIL"  SG_ 968 FRM_9_ObjAccelY_12 2;
BA_ "GenSigASIL"  SG_ 968 FRM_9_ObjClosestDistXStd_12 2;
BA_ "GenSigASIL"  SG_ 968 FRM_9_ObjClosestDistYStd_12 2;
BA_ "GenSigASIL"  SG_ 968 FRM_9_ObjRelVelXStd_12 2;
BA_ "GenSigASIL"  SG_ 968 FRM_9_ObjRelVelYStd_12 2;
BA_ "GenSigASIL"  SG_ 968 FRM_9_ObjRelAccelXStd_12 2;
BA_ "GenSigASIL"  SG_ 968 FRM_9_ObjRelAccelYStd_12 2;
BA_ "GenSigASIL"  SG_ 968 FRM_9_ObjExistProb_12 2;
BA_ "GenSigASIL"  SG_ 968 FRM_9_ObjType_12 2;
BA_ "GenSigASIL"  SG_ 968 FRM_9_ObjTypeConf_12 2;
BA_ "GenSigASIL"  SG_ 968 FRM_9_ObjTrackSts_12 2;
BA_ "GenSigASIL"  SG_ 968 FRM_9_ObjMotionSts_12 2;
BA_ "GenSigASIL"  SG_ 968 FRM_9_ObjMotionDirection_12 2;
BA_ "GenSigASIL"  SG_ 968 FRM_9_ObjCenterDistX_12 2;
BA_ "GenSigStartValue" SG_ 968 FRM_9_ObjCenterDistY_12 10000;
BA_ "GenSigASIL"  SG_ 968 FRM_9_ObjCenterDistY_12 2;
BA_ "GenSigASIL"  SG_ 968 FRM_9_ObjLength_12 2;
BA_ "GenSigASIL"  SG_ 968 FRM_9_ObjWidth_12 2;
BA_ "GenSigASIL"  SG_ 968 FRM_9_ObjElevnSts_12 2;
BA_ "GenSigASIL"  SG_ 968 FRM_9_ObjElevnStsConf_12 2;
BA_ "GenSigStartValue" SG_ 968 FRM_9_ObjHeading_12 1800;
BA_ "GenSigASIL"  SG_ 968 FRM_9_ObjHeading_12 2;
BA_ "GenSigASIL"  SG_ 968 FRM_9_ObjID_13 2;
BA_ "GenSigASIL"  SG_ 968 FRM_9_ObjClosestDistX_13 2;
BA_ "GenSigStartValue" SG_ 968 FRM_9_ObjClosestDistY_13 10000;
BA_ "GenSigASIL"  SG_ 968 FRM_9_ObjClosestDistY_13 2;
BA_ "GenSigStartValue" SG_ 968 FRM_9_ObjRelVelX_13 10000;
BA_ "GenSigASIL"  SG_ 968 FRM_9_ObjRelVelX_13 2;
BA_ "GenSigStartValue" SG_ 968 FRM_9_ObjRelVelY_13 10000;
BA_ "GenSigASIL"  SG_ 968 FRM_9_ObjRelVelY_13 2;
BA_ "GenSigStartValue" SG_ 968 FRM_9_ObjAccelX_13 2500;
BA_ "GenSigASIL"  SG_ 968 FRM_9_ObjAccelX_13 2;
BA_ "GenSigStartValue" SG_ 968 FRM_9_ObjAccelY_13 2500;
BA_ "GenSigASIL"  SG_ 968 FRM_9_ObjAccelY_13 2;
BA_ "GenSigASIL"  SG_ 968 FRM_9_ObjClosestDistXStd_13 2;
BA_ "GenSigASIL"  SG_ 968 FRM_9_ObjClosestDistYStd_13 2;
BA_ "GenSigASIL"  SG_ 968 FRM_9_ObjRelVelXStd_13 2;
BA_ "GenSigASIL"  SG_ 968 FRM_9_ObjRelVelYStd_13 2;
BA_ "GenSigASIL"  SG_ 968 FRM_9_ObjRelAccelXStd_13 2;
BA_ "GenSigASIL"  SG_ 968 FRM_9_ObjRelAccelYStd_13 2;
BA_ "GenSigASIL"  SG_ 968 FRM_9_ObjExistProb_13 2;
BA_ "GenSigASIL"  SG_ 968 FRM_9_ObjType_13 2;
BA_ "GenSigASIL"  SG_ 968 FRM_9_ObjTypeConf_13 2;
BA_ "GenSigASIL"  SG_ 968 FRM_9_ObjTrackSts_13 2;
BA_ "GenSigASIL"  SG_ 968 FRM_9_ObjMotionSts_13 2;
BA_ "GenSigASIL"  SG_ 968 FRM_9_ObjMotionDirection_13 2;
BA_ "GenSigASIL"  SG_ 968 FRM_9_ObjCenterDistX_13 2;
BA_ "GenSigStartValue" SG_ 968 FRM_9_ObjCenterDistY_13 10000;
BA_ "GenSigASIL"  SG_ 968 FRM_9_ObjCenterDistY_13 2;
BA_ "GenSigASIL"  SG_ 968 FRM_9_ObjLength_13 2;
BA_ "GenSigASIL"  SG_ 968 FRM_9_ObjWidth_13 2;
BA_ "GenSigASIL"  SG_ 968 FRM_9_ObjElevnSts_13 2;
BA_ "GenSigASIL"  SG_ 968 FRM_9_ObjElevnStsConf_13 2;
BA_ "GenSigStartValue" SG_ 968 FRM_9_ObjHeading_13 1800;
BA_ "GenSigASIL"  SG_ 968 FRM_9_ObjHeading_13 2;
BA_ "GenMsgILSupport" BO_ 969 1;
BA_ "GenMsgCycleTime" BO_ 969 50;
BA_ "GenSigASIL"  SG_ 969 FRM_10_CRC 5;
BA_ "GenSigASIL"  SG_ 969 FRM_10_RollgCntr 5;
BA_ "GenSigASIL"  SG_ 969 FRM_10_ObjBlockCounter 2;
BA_ "GenSigASIL"  SG_ 969 FRM_10_ObjID_14 2;
BA_ "GenSigASIL"  SG_ 969 FRM_10_ObjClosestDistX_14 2;
BA_ "GenSigStartValue" SG_ 969 FRM_10_ObjClosestDistY_14 10000;
BA_ "GenSigASIL"  SG_ 969 FRM_10_ObjClosestDistY_14 2;
BA_ "GenSigStartValue" SG_ 969 FRM_10_ObjRelVelX_14 10000;
BA_ "GenSigASIL"  SG_ 969 FRM_10_ObjRelVelX_14 2;
BA_ "GenSigStartValue" SG_ 969 FRM_10_ObjRelVelY_14 10000;
BA_ "GenSigASIL"  SG_ 969 FRM_10_ObjRelVelY_14 2;
BA_ "GenSigStartValue" SG_ 969 FRM_10_ObjAccelX_14 2500;
BA_ "GenSigASIL"  SG_ 969 FRM_10_ObjAccelX_14 2;
BA_ "GenSigStartValue" SG_ 969 FRM_10_ObjAccelY_14 2500;
BA_ "GenSigASIL"  SG_ 969 FRM_10_ObjAccelY_14 2;
BA_ "GenSigASIL"  SG_ 969 FRM_10_ObjClosestDistXStd_14 2;
BA_ "GenSigASIL"  SG_ 969 FRM_10_ObjClosestDistYStd_14 2;
BA_ "GenSigASIL"  SG_ 969 FRM_10_ObjRelVelXStd_14 2;
BA_ "GenSigASIL"  SG_ 969 FRM_10_ObjRelVelYStd_14 2;
BA_ "GenSigASIL"  SG_ 969 FRM_10_ObjRelAccelXStd_14 2;
BA_ "GenSigASIL"  SG_ 969 FRM_10_ObjRelAccelYStd_14 2;
BA_ "GenSigASIL"  SG_ 969 FRM_10_ObjExistProb_14 2;
BA_ "GenSigASIL"  SG_ 969 FRM_10_ObjType_14 2;
BA_ "GenSigASIL"  SG_ 969 FRM_10_ObjTypeConf_14 2;
BA_ "GenSigASIL"  SG_ 969 FRM_10_ObjTrackSts_14 2;
BA_ "GenSigASIL"  SG_ 969 FRM_10_ObjMotionSts_14 2;
BA_ "GenSigASIL"  SG_ 969 FRM_10_ObjMotionDirection_14 2;
BA_ "GenSigASIL"  SG_ 969 FRM_10_ObjCenterDistX_14 2;
BA_ "GenSigStartValue" SG_ 969 FRM_10_ObjCenterDistY_14 10000;
BA_ "GenSigASIL"  SG_ 969 FRM_10_ObjCenterDistY_14 2;
BA_ "GenSigASIL"  SG_ 969 FRM_10_ObjLength_14 2;
BA_ "GenSigASIL"  SG_ 969 FRM_10_ObjWidth_14 2;
BA_ "GenSigASIL"  SG_ 969 FRM_10_ObjElevnSts_14 2;
BA_ "GenSigASIL"  SG_ 969 FRM_10_ObjElevnStsConf_14 2;
BA_ "GenSigStartValue" SG_ 969 FRM_10_ObjHeading_14 1800;
BA_ "GenSigASIL"  SG_ 969 FRM_10_ObjHeading_14 2;
BA_ "GenSigASIL"  SG_ 969 FRM_10_ObjID_15 2;
BA_ "GenSigASIL"  SG_ 969 FRM_10_ObjClosestDistX_15 2;
BA_ "GenSigStartValue" SG_ 969 FRM_10_ObjClosestDistY_15 10000;
BA_ "GenSigASIL"  SG_ 969 FRM_10_ObjClosestDistY_15 2;
BA_ "GenSigStartValue" SG_ 969 FRM_10_ObjRelVelX_15 10000;
BA_ "GenSigASIL"  SG_ 969 FRM_10_ObjRelVelX_15 2;
BA_ "GenSigStartValue" SG_ 969 FRM_10_ObjRelVelY_15 10000;
BA_ "GenSigASIL"  SG_ 969 FRM_10_ObjRelVelY_15 2;
BA_ "GenSigStartValue" SG_ 969 FRM_10_ObjAccelX_15 2500;
BA_ "GenSigASIL"  SG_ 969 FRM_10_ObjAccelX_15 2;
BA_ "GenSigStartValue" SG_ 969 FRM_10_ObjAccelY_15 2500;
BA_ "GenSigASIL"  SG_ 969 FRM_10_ObjAccelY_15 2;
BA_ "GenSigASIL"  SG_ 969 FRM_10_ObjClosestDistXStd_15 2;
BA_ "GenSigASIL"  SG_ 969 FRM_10_ObjClosestDistYStd_15 2;
BA_ "GenSigASIL"  SG_ 969 FRM_10_ObjRelVelXStd_15 2;
BA_ "GenSigASIL"  SG_ 969 FRM_10_ObjRelVelYStd_15 2;
BA_ "GenSigASIL"  SG_ 969 FRM_10_ObjRelAccelXStd_15 2;
BA_ "GenSigASIL"  SG_ 969 FRM_10_ObjRelAccelYStd_15 2;
BA_ "GenSigASIL"  SG_ 969 FRM_10_ObjExistProb_15 2;
BA_ "GenSigASIL"  SG_ 969 FRM_10_ObjType_15 2;
BA_ "GenSigASIL"  SG_ 969 FRM_10_ObjTypeConf_15 2;
BA_ "GenSigASIL"  SG_ 969 FRM_10_ObjTrackSts_15 2;
BA_ "GenSigASIL"  SG_ 969 FRM_10_ObjMotionSts_15 2;
BA_ "GenSigASIL"  SG_ 969 FRM_10_ObjMotionDirection_15 2;
BA_ "GenSigASIL"  SG_ 969 FRM_10_ObjCenterDistX_15 2;
BA_ "GenSigStartValue" SG_ 969 FRM_10_ObjCenterDistY_15 10000;
BA_ "GenSigASIL"  SG_ 969 FRM_10_ObjCenterDistY_15 2;
BA_ "GenSigASIL"  SG_ 969 FRM_10_ObjLength_15 2;
BA_ "GenSigASIL"  SG_ 969 FRM_10_ObjWidth_15 2;
BA_ "GenSigASIL"  SG_ 969 FRM_10_ObjElevnSts_15 2;
BA_ "GenSigASIL"  SG_ 969 FRM_10_ObjElevnStsConf_15 2;
BA_ "GenSigStartValue" SG_ 969 FRM_10_ObjHeading_15 1800;
BA_ "GenSigASIL"  SG_ 969 FRM_10_ObjHeading_15 2;
VAL_ 960 FRM_1_ObjHd_HWFail 1 "HWFailure" 0 "NoHWFailure" ;
VAL_ 960 FRM_1_ObjHd_Misalignment 1 "Misalignment" 0 "NoMisalignment" ;
VAL_ 960 FRM_1_ObjHd_AlignmentNotDone 1 "AlignmentNotDone" 0 "AlignmentDone" ;
VAL_ 960 FRM_1_ObjHd_SensorBlockage 1 "SensorBlockage" 0 "NoSensorBlockage" ;
VAL_ 960 FRM_1_ObjHd_ObjDetFail 1 "ObjDetFailure" 0 "NoObjDetFailure" ;
VAL_ 960 FRM_1_ObjHd_OutOfVoltage 1 "OutOfVoltage" 0 "NoOutOfVoltage" ;
VAL_ 960 FRM_1_ObjHd_OverTemperature 1 "OverTemperature" 0 "NoOverTemperature" ;
VAL_ 960 FRM_1_ObjHd_ReceivedCANTimeOut 1 "ReceivedCANTimeOut" 0 "NoReceivedCANTimeOut" ;
VAL_ 960 FRM_1_ObjHd_ReceivedCANInvalid 1 "ReceivedCANInvalid" 0 "NoReceivedCANInvalid" ;
VAL_ 960 FRM_1_ObjHd_RFBoardWorkingSts 1 "NoWorking" 0 "Working" ;
VAL_ 960 FRM_1_ObjHd_ObjDownSel 1 "down selected" 0 "no down selection" ;
VAL_ 960 FRM_1_ObjHd_NotConfigured 1 "NotConfigured" 0 "Configured" ;
VAL_ 960 FRM_1_ObjHd_ParameterInvalid 1 "ParameterInvalid" 0 "ParameterValid" ;
VAL_ 961 FRM_2_DetnHd_HWFail 1 "HWFailure" 0 "NoHWFailure" ;
VAL_ 961 FRM_2_DetnHd_Misalignment 1 "Misalignment" 0 "NoMisalignment" ;
VAL_ 961 FRM_2_DetnHd_AlignmentNotDone 1 "AlignmentNotDone" 0 "AlignmentDone" ;
VAL_ 961 FRM_2_DetnHd_SensorBlockage 1 "SensorBlockage" 0 "NoSensorBlockage" ;
VAL_ 961 FRM_2_DetnHd_ObjDetFail 1 "ObjDetFailure" 0 "NoObjDetFailure" ;
VAL_ 961 FRM_2_DetnHd_OutOfVoltage 1 "OutOfVoltage" 0 "NoOutOfVoltage" ;
VAL_ 961 FRM_2_DetnHd_OverTemperature 1 "OverTemperature" 0 "NoOverTemperature" ;
VAL_ 961 FRM_2_DetnHd_ReceivedCANTimeOut 1 "ReceivedCANTimeOut" 0 "NoReceivedCANTimeOut" ;
VAL_ 961 FRM_2_DetnHd_ReceivedCANInvalid 1 "ReceivedCANInvalid" 0 "NoReceivedCANInvalid" ;
VAL_ 961 FRM_2_DetnHd_RFBoardWorkingSts 1 "NoWorking" 0 "Working" ;
VAL_ 961 FRM_2_DetnHd_DetnDownSel 1 "down selected" 0 "no down selection" ;
VAL_ 961 FRM_2_DetnHd_NotConfigured 1 "NotConfigured" 0 "Configured" ;
VAL_ 961 FRM_2_DetnHd_ParameterInvalid 1 "ParameterInvalid" 0 "ParameterValid" ;
VAL_ 962 FRM_3_ObjType_00 3 "Four-wheels" 2 "Two-wheels" 1 "Pedestrian" 0 "Unknown" ;
VAL_ 962 FRM_3_ObjTrackSts_00 3 "Coasted" 2 "New" 1 "Updated" 0 "Unknown" ;
VAL_ 962 FRM_3_ObjMotionSts_00 3 "Static" 2 "Stopped" 1 "Moving" 0 "Unknown" ;
VAL_ 962 FRM_3_ObjMotionDirection_00 3 "Cossing" 2 "Reverse" 1 "Homogeneous" 0 "Unknown" ;
VAL_ 962 FRM_3_ObjElevnSts_00 3 "UnderRidable" 2 "Obstacle" 1 "OverRidable" 0 "Unknown" ;
VAL_ 962 FRM_3_ObjType_01 3 "Four-wheels" 2 "Two-wheels" 1 "Pedestrian" 0 "Unknown" ;
VAL_ 962 FRM_3_ObjTrackSts_01 3 "Coasted" 2 "New" 1 "Updated" 0 "Unknown" ;
VAL_ 962 FRM_3_ObjMotionSts_01 3 "Static" 2 "Stopped" 1 "Moving" 0 "Unknown" ;
VAL_ 962 FRM_3_ObjMotionDirection_01 3 "Cossing" 2 "Reverse" 1 "Homogeneous" 0 "Unknown" ;
VAL_ 962 FRM_3_ObjElevnSts_01 3 "UnderRidable" 2 "Obstacle" 1 "OverRidable" 0 "Unknown" ;
VAL_ 963 FRM_4_ObjType_02 3 "Four-wheels" 2 "Two-wheels" 1 "Pedestrian" 0 "Unknown" ;
VAL_ 963 FRM_4_ObjTrackSts_02 3 "Coasted" 2 "New" 1 "Updated" 0 "Unknown" ;
VAL_ 963 FRM_4_ObjMotionSts_02 3 "Static" 2 "Stopped" 1 "Moving" 0 "Unknown" ;
VAL_ 963 FRM_4_ObjMotionDirection_02 3 "Cossing" 2 "Reverse" 1 "Homogeneous" 0 "Unknown" ;
VAL_ 963 FRM_4_ObjElevnSts_02 3 "UnderRidable" 2 "Obstacle" 1 "OverRidable" 0 "Unknown" ;
VAL_ 963 FRM_4_ObjType_03 3 "Four-wheels" 2 "Two-wheels" 1 "Pedestrian" 0 "Unknown" ;
VAL_ 963 FRM_4_ObjTrackSts_03 3 "Coasted" 2 "New" 1 "Updated" 0 "Unknown" ;
VAL_ 963 FRM_4_ObjMotionSts_03 3 "Static" 2 "Stopped" 1 "Moving" 0 "Unknown" ;
VAL_ 963 FRM_4_ObjMotionDirection_03 3 "Cossing" 2 "Reverse" 1 "Homogeneous" 0 "Unknown" ;
VAL_ 963 FRM_4_ObjElevnSts_03 3 "UnderRidable" 2 "Obstacle" 1 "OverRidable" 0 "Unknown" ;
VAL_ 964 FRM_5_ObjType_04 3 "Four-wheels" 2 "Two-wheels" 1 "Pedestrian" 0 "Unknown" ;
VAL_ 964 FRM_5_ObjTrackSts_04 3 "Coasted" 2 "New" 1 "Updated" 0 "Unknown" ;
VAL_ 964 FRM_5_ObjMotionSts_04 3 "Static" 2 "Stopped" 1 "Moving" 0 "Unknown" ;
VAL_ 964 FRM_5_ObjMotionDirection_04 3 "Cossing" 2 "Reverse" 1 "Homogeneous" 0 "Unknown" ;
VAL_ 964 FRM_5_ObjElevnSts_04 3 "UnderRidable" 2 "Obstacle" 1 "OverRidable" 0 "Unknown" ;
VAL_ 964 FRM_5_ObjType_05 3 "Four-wheels" 2 "Two-wheels" 1 "Pedestrian" 0 "Unknown" ;
VAL_ 964 FRM_5_ObjTrackSts_05 3 "Coasted" 2 "New" 1 "Updated" 0 "Unknown" ;
VAL_ 964 FRM_5_ObjMotionSts_05 3 "Static" 2 "Stopped" 1 "Moving" 0 "Unknown" ;
VAL_ 964 FRM_5_ObjMotionDirection_05 3 "Cossing" 2 "Reverse" 1 "Homogeneous" 0 "Unknown" ;
VAL_ 964 FRM_5_ObjElevnSts_05 3 "UnderRidable" 2 "Obstacle" 1 "OverRidable" 0 "Unknown" ;
VAL_ 965 FRM_6_ObjType_06 3 "Four-wheels" 2 "Two-wheels" 1 "Pedestrian" 0 "Unknown" ;
VAL_ 965 FRM_6_ObjTrackSts_06 3 "Coasted" 2 "New" 1 "Updated" 0 "Unknown" ;
VAL_ 965 FRM_6_ObjMotionSts_06 3 "Static" 2 "Stopped" 1 "Moving" 0 "Unknown" ;
VAL_ 965 FRM_6_ObjMotionDirection_06 3 "Cossing" 2 "Reverse" 1 "Homogeneous" 0 "Unknown" ;
VAL_ 965 FRM_6_ObjElevnSts_06 3 "UnderRidable" 2 "Obstacle" 1 "OverRidable" 0 "Unknown" ;
VAL_ 965 FRM_6_ObjType_07 3 "Four-wheels" 2 "Two-wheels" 1 "Pedestrian" 0 "Unknown" ;
VAL_ 965 FRM_6_ObjTrackSts_07 3 "Coasted" 2 "New" 1 "Updated" 0 "Unknown" ;
VAL_ 965 FRM_6_ObjMotionSts_07 3 "Static" 2 "Stopped" 1 "Moving" 0 "Unknown" ;
VAL_ 965 FRM_6_ObjMotionDirection_07 3 "Cossing" 2 "Reverse" 1 "Homogeneous" 0 "Unknown" ;
VAL_ 965 FRM_6_ObjElevnSts_07 3 "UnderRidable" 2 "Obstacle" 1 "OverRidable" 0 "Unknown" ;
VAL_ 966 FRM_7_ObjType_08 3 "Four-wheels" 2 "Two-wheels" 1 "Pedestrian" 0 "Unknown" ;
VAL_ 966 FRM_7_ObjTrackSts_08 3 "Coasted" 2 "New" 1 "Updated" 0 "Unknown" ;
VAL_ 966 FRM_7_ObjMotionSts_08 3 "Static" 2 "Stopped" 1 "Moving" 0 "Unknown" ;
VAL_ 966 FRM_7_ObjMotionDirection_08 3 "Cossing" 2 "Reverse" 1 "Homogeneous" 0 "Unknown" ;
VAL_ 966 FRM_7_ObjElevnSts_08 3 "UnderRidable" 2 "Obstacle" 1 "OverRidable" 0 "Unknown" ;
VAL_ 966 FRM_7_ObjType_09 3 "Four-wheels" 2 "Two-wheels" 1 "Pedestrian" 0 "Unknown" ;
VAL_ 966 FRM_7_ObjTrackSts_09 3 "Coasted" 2 "New" 1 "Updated" 0 "Unknown" ;
VAL_ 966 FRM_7_ObjMotionSts_09 3 "Static" 2 "Stopped" 1 "Moving" 0 "Unknown" ;
VAL_ 966 FRM_7_ObjMotionDirection_09 3 "Cossing" 2 "Reverse" 1 "Homogeneous" 0 "Unknown" ;
VAL_ 966 FRM_7_ObjElevnSts_09 3 "UnderRidable" 2 "Obstacle" 1 "OverRidable" 0 "Unknown" ;
VAL_ 967 FRM_8_ObjType_10 3 "Four-wheels" 2 "Two-wheels" 1 "Pedestrian" 0 "Unknown" ;
VAL_ 967 FRM_8_ObjTrackSts_10 3 "Coasted" 2 "New" 1 "Updated" 0 "Unknown" ;
VAL_ 967 FRM_8_ObjMotionSts_10 3 "Static" 2 "Stopped" 1 "Moving" 0 "Unknown" ;
VAL_ 967 FRM_8_ObjMotionDirection_10 3 "Cossing" 2 "Reverse" 1 "Homogeneous" 0 "Unknown" ;
VAL_ 967 FRM_8_ObjElevnSts_10 3 "UnderRidable" 2 "Obstacle" 1 "OverRidable" 0 "Unknown" ;
VAL_ 967 FRM_8_ObjType_11 3 "Four-wheels" 2 "Two-wheels" 1 "Pedestrian" 0 "Unknown" ;
VAL_ 967 FRM_8_ObjTrackSts_11 3 "Coasted" 2 "New" 1 "Updated" 0 "Unknown" ;
VAL_ 967 FRM_8_ObjMotionSts_11 3 "Static" 2 "Stopped" 1 "Moving" 0 "Unknown" ;
VAL_ 967 FRM_8_ObjMotionDirection_11 3 "Cossing" 2 "Reverse" 1 "Homogeneous" 0 "Unknown" ;
VAL_ 967 FRM_8_ObjElevnSts_11 3 "UnderRidable" 2 "Obstacle" 1 "OverRidable" 0 "Unknown" ;
VAL_ 968 FRM_9_ObjType_12 3 "Four-wheels" 2 "Two-wheels" 1 "Pedestrian" 0 "Unknown" ;
VAL_ 968 FRM_9_ObjTrackSts_12 3 "Coasted" 2 "New" 1 "Updated" 0 "Unknown" ;
VAL_ 968 FRM_9_ObjMotionSts_12 3 "Static" 2 "Stopped" 1 "Moving" 0 "Unknown" ;
VAL_ 968 FRM_9_ObjMotionDirection_12 3 "Cossing" 2 "Reverse" 1 "Homogeneous" 0 "Unknown" ;
VAL_ 968 FRM_9_ObjElevnSts_12 3 "UnderRidable" 2 "Obstacle" 1 "OverRidable" 0 "Unknown" ;
VAL_ 968 FRM_9_ObjType_13 3 "Four-wheels" 2 "Two-wheels" 1 "Pedestrian" 0 "Unknown" ;
VAL_ 968 FRM_9_ObjTrackSts_13 3 "Coasted" 2 "New" 1 "Updated" 0 "Unknown" ;
VAL_ 968 FRM_9_ObjMotionSts_13 3 "Static" 2 "Stopped" 1 "Moving" 0 "Unknown" ;
VAL_ 968 FRM_9_ObjMotionDirection_13 3 "Cossing" 2 "Reverse" 1 "Homogeneous" 0 "Unknown" ;
VAL_ 968 FRM_9_ObjElevnSts_13 3 "UnderRidable" 2 "Obstacle" 1 "OverRidable" 0 "Unknown" ;
VAL_ 969 FRM_10_ObjType_14 3 "Four-wheels" 2 "Two-wheels" 1 "Pedestrian" 0 "Unknown" ;
VAL_ 969 FRM_10_ObjTrackSts_14 3 "Coasted" 2 "New" 1 "Updated" 0 "Unknown" ;
VAL_ 969 FRM_10_ObjMotionSts_14 3 "Static" 2 "Stopped" 1 "Moving" 0 "Unknown" ;
VAL_ 969 FRM_10_ObjMotionDirection_14 3 "Cossing" 2 "Reverse" 1 "Homogeneous" 0 "Unknown" ;
VAL_ 969 FRM_10_ObjElevnSts_14 3 "UnderRidable" 2 "Obstacle" 1 "OverRidable" 0 "Unknown" ;
VAL_ 969 FRM_10_ObjType_15 3 "Four-wheels" 2 "Two-wheels" 1 "Pedestrian" 0 "Unknown" ;
VAL_ 969 FRM_10_ObjTrackSts_15 3 "Coasted" 2 "New" 1 "Updated" 0 "Unknown" ;
VAL_ 969 FRM_10_ObjMotionSts_15 3 "Static" 2 "Stopped" 1 "Moving" 0 "Unknown" ;
VAL_ 969 FRM_10_ObjMotionDirection_15 3 "Cossing" 2 "Reverse" 1 "Homogeneous" 0 "Unknown" ;
VAL_ 969 FRM_10_ObjElevnSts_15 3 "UnderRidable" 2 "Obstacle" 1 "OverRidable" 0 "Unknown" ;
